VERSION "HNNBNNNYNNNNNNNNNNNNNNNNNNNNNNNNNNNNNNNNNN/4/%%%/4/'%**4NNN///"

NS_ :

BS_:

BU_: BAP_Tester ELV Gateway_Max HUD Kombi

BO_ 2536714496 BAP_Audio_ASG_01: 8 Kombi
 SG_ BAP_Audio_ASG_01_Header : 0|8@1+ (1.0,0.0) [0.0|255] ""  Gateway_Max

BO_ 2536714497 BAP_Audio_ASG_02: 8 Kombi
 SG_ BAP_Audio_ASG_02_Header : 0|8@1+ (1.0,0.0) [0.0|255] ""  Gateway_Max

BO_ 2536714498 BAP_Audio_ASG_03: 8 HUD
 SG_ BAP_Audio_ASG_03_Header : 0|8@1+ (1.0,0.0) [0.0|255] ""  Gateway_Max

BO_ 2536714499 BAP_Audio_ASG_04: 8 HUD
 SG_ BAP_Audio_ASG_04_Header : 0|8@1+ (1.0,0.0) [0.0|255] ""  Gateway_Max

BO_ 2536714512 BAP_Audio_FSG_01: 8 Gateway_Max
 SG_ BAP_Audio_FSG_01_Header : 0|8@1+ (1.0,0.0) [0.0|255] ""  HUD,Kombi

BO_ 2536714513 BAP_Audio_FSG_02: 8 Gateway_Max
 SG_ BAP_Audio_FSG_02_Header : 0|8@1+ (1.0,0.0) [0.0|255] ""  HUD,Kombi

BO_ 2536704256 BAP_Aussenlicht_ASG_01: 8 Kombi
 SG_ BAP_Aussenlicht_ASG_01_Header : 0|8@1+ (1.0,0.0) [0.0|255] ""  Gateway_Max

BO_ 2536704272 BAP_Aussenlicht_FSG_01: 8 Gateway_Max
 SG_ BAP_Aussenlicht_FSG_01_Header : 0|8@1+ (1.0,0.0) [0.0|255] ""  Kombi

BO_ 2536708865 BAP_AWV_ASG_02: 8 Kombi
 SG_ BAP_AWV_ASG_02_Header : 0|8@1+ (1.0,0.0) [0.0|255] ""  Gateway_Max

BO_ 2536708880 BAP_AWV_FSG_01: 8 Gateway_Max
 SG_ BAP_AWV_FSG_01_Header : 0|8@1+ (1.0,0.0) [0.0|255] ""  Kombi

BO_ 2536711426 BAP_BatteryControl_ASG_03: 8 Kombi
 SG_ BAP_BatteryControl_ASG_03_Header : 0|8@1+ (1.0,0.0) [0.0|255] ""  Gateway_Max

BO_ 2536711440 BAP_BatteryControl_FSG_01: 8 Gateway_Max
 SG_ BAP_BatteryControl_FSG_01_Header : 0|8@1+ (1.0,0.0) [0.0|255] ""  Kombi

BO_ 2536705792 BAP_BC_ASG_01: 8 Gateway_Max
 SG_ BAP_BC_ASG_01_Header : 0|8@1+ (1.0,0.0) [0.0|255] ""  Kombi

BO_ 2536705793 BAP_BC_ASG_02: 8 Gateway_Max
 SG_ BAP_BC_ASG_02_Header : 0|8@1+ (1.0,0.0) [0.0|255] ""  Kombi

BO_ 2536705808 BAP_BC_FSG_01: 8 Kombi
 SG_ BAP_BC_FSG_01_Header : 0|8@1+ (1.0,0.0) [0.0|255] ""  Gateway_Max

BO_ 2536705809 BAP_BC_FSG_02: 8 Kombi
 SG_ BAP_BC_FSG_02_Header : 0|64@1+ (1.0,0.0) [0.0|18446744073709551615] ""  Gateway_Max

BO_ 2536710912 BAP_BCmE_ASG_01: 8 Kombi
 SG_ BAP_BCmE_ASG_01_Header : 0|8@1+ (1.0,0.0) [0.0|255] ""  Gateway_Max

BO_ 2536710928 BAP_BCmE_FSG_01: 8 Gateway_Max
 SG_ BAP_BCmE_FSG_01_Header : 0|8@1+ (1.0,0.0) [0.0|255] ""  Kombi

BO_ 2536734976 BAP_California_ASG_01: 8 Gateway_Max
 SG_ BAP_California_ASG_01_Header : 0|64@1+ (1.0,0.0) [0.0|18446744073709551615] ""  Vector__XXX

BO_ 2536734992 BAP_California_FSG_01: 8 Vector__XXX
 SG_ BAP_California_FSG_01_Header : 0|64@1+ (1.0,0.0) [0.0|18446744073709551615] ""  Gateway_Max

BO_ 2536767264 BAP_Debug_Cmd: 8 BAP_Tester
 SG_ BAP_Debug_Cmd : 0|16@1+ (1.0,0.0) [0.0|65535] ""  Gateway_Max,HUD,Kombi

BO_ 2536767280 BAP_Debug_Data: 8 Gateway_Max
 SG_ BAP_Debug_Data : 0|64@1+ (1.0,0.0) [0.0|18446744073709551615] ""  BAP_Tester

BO_ 2536719616 BAP_DisplayConfig_ASG_01: 8 Gateway_Max
 SG_ BAP_DisplayConfig_ASG_01_Header : 0|8@1+ (1,0) [0|255] "Unit_None"  Kombi

BO_ 2536719617 BAP_DisplayConfig_ASG_02: 8 Gateway_Max
 SG_ BAP_DisplayConfig_ASG_02_Header : 0|64@1+ (1.0,0.0) [0.0|18446744073709551615] ""  Kombi

BO_ 2536719632 BAP_DisplayConfig_FSG_01: 8 Kombi
 SG_ BAP_DisplayConfig_FSG_01_Header : 0|8@1+ (1,0) [0|255] "Unit_None"  Gateway_Max

BO_ 2536705281 BAP_Doorlocking_ASG_02: 8 Kombi
 SG_ BAP_Doorlocking_ASG_02_Header : 0|8@1+ (1.0,0.0) [0.0|255] ""  Gateway_Max

BO_ 2536705296 BAP_Doorlocking_FSG_01: 8 Gateway_Max
 SG_ BAP_Doorlocking_FSG_01_Header : 0|8@1+ (1.0,0.0) [0.0|255] ""  Kombi

BO_ 2536717313 BAP_EfficiencyAssist_ASG_02: 8 Kombi
 SG_ BAP_EfficAssist_ASG_02_Header : 0|64@1+ (1.0,0.0) [0.0|18446744073709551615] ""  Gateway_Max

BO_ 2536717314 BAP_EfficiencyAssist_ASG_03: 8 HUD
 SG_ BAP_EfficAssist_ASG_03_Header : 0|64@1+ (1.0,0.0) [0.0|18446744073709551615] ""  Vector__XXX

BO_ 2536717328 BAP_EfficiencyAssist_FSG_01: 8 Gateway_Max
 SG_ BAP_EfficAssist_FSG_01_Header : 0|8@1+ (1.0,0.0) [0.0|255] ""  HUD,Kombi

BO_ 2536706816 BAP_Einheiten_ASG_01: 8 Gateway_Max
 SG_ BAP_Einheiten_ASG_01_Header : 0|8@1+ (1.0,0.0) [0.0|255] ""  Kombi

BO_ 2536706819 BAP_Einheiten_ASG_04: 8 Gateway_Max
 SG_ BAP_Einheiten_ASG_04_Header : 0|8@1+ (1,0) [0|255] "Unit_None"  Kombi

BO_ 2536706832 BAP_Einheiten_FSG_01: 8 Kombi
 SG_ BAP_Einheiten_FSG_01_Header : 0|8@1+ (1.0,0.0) [0.0|255] ""  Gateway_Max

BO_ 2536702976 BAP_HUD_ASG_01: 8 Gateway_Max
 SG_ BAP_HUD_ASG_01_Header : 0|8@1+ (1.0,0.0) [0.0|255] ""  HUD

BO_ 2536702977 BAP_HUD_ASG_02: 8 Kombi
 SG_ BAP_HUD_ASG_02_Header : 0|8@1+ (1,0) [0|255] "Unit_None"  HUD

BO_ 2536702978 BAP_HUD_ASG_03: 8 Gateway_Max
 SG_ BAP_HUD_ASG_03_Header : 0|8@1+ (1,0) [0|255] "Unit_None"  HUD

BO_ 2536702992 BAP_HUD_FSG_01: 8 HUD
 SG_ BAP_HUD_FSG_01_Header : 0|8@1+ (1.0,0.0) [0.0|255] ""  Gateway_Max,Kombi

BO_ 2536709121 BAP_Hybrid_ASG_02: 8 Kombi
 SG_ BAP_Hybrid_ASG_02_Header : 0|8@1+ (1.0,0.0) [0.0|255] ""  Gateway_Max

BO_ 2536709136 BAP_Hybrid_FSG_01: 8 Gateway_Max
 SG_ BAP_Hybrid_FSG_01_Header : 0|8@1+ (1.0,0.0) [0.0|255] ""  Kombi

BO_ 2536722945 BAP_IAA_PSO_ASG_02: 8 Kombi
 SG_ BAP_IAA_PSO_ASG_02_Header : 0|8@1+ (1,0) [0|255] "Unit_None"  Gateway_Max

BO_ 2536722960 BAP_IAA_PSO_FSG_01: 8 Gateway_Max
 SG_ BAP_IAA_PSO_FSG_01_Header : 0|8@1+ (1,0) [0|255] "Unit_None"  Kombi

BO_ 2536704000 BAP_Innenlicht_ASG_01: 8 Kombi
 SG_ BAP_Innenlicht_ASG_01_Header : 0|8@1+ (1.0,0.0) [0.0|255] ""  Gateway_Max

BO_ 2536704003 BAP_Innenlicht_ASG_04: 8 HUD
 SG_ BAP_Innenlicht_ASG_04_Header : 0|64@1+ (1.0,0.0) [0.0|18446744073709551615] ""  Gateway_Max

BO_ 2536704016 BAP_Innenlicht_FSG_01: 8 Gateway_Max
 SG_ BAP_Innenlicht_FSG_01_Header : 0|8@1+ (1.0,0.0) [0.0|255] ""  HUD,Kombi

BO_ 2536708353 BAP_LDW_ASG_02: 8 Kombi
 SG_ BAP_LDW_ASG_02_Header : 0|8@1+ (1.0,0.0) [0.0|255] ""  Gateway_Max

BO_ 2536708368 BAP_LDW_FSG_01: 8 Gateway_Max
 SG_ BAP_LDW_FSG_01_Header : 0|8@1+ (1.0,0.0) [0.0|255] ""  Kombi

BO_ 2536715264 BAP_MFL_ASG_01: 8 Kombi
 SG_ BAP_MFL_ASG_01_Header : 0|8@1+ (1.0,0.0) [0.0|255] ""  Gateway_Max

BO_ 2536715280 BAP_MFL_FSG_01: 8 Gateway_Max
 SG_ BAP_MFL_FSG_01_Header : 0|8@1+ (1.0,0.0) [0.0|255] ""  Kombi

BO_ 2536714752 BAP_Navigation_ASG_01: 8 Kombi
 SG_ BAP_Navigation_ASG_01_Header : 0|8@1+ (1.0,0.0) [0.0|255] ""  Gateway_Max

BO_ 2536714753 BAP_Navigation_ASG_02: 8 Kombi
 SG_ BAP_Navigation_ASG_02_Header : 0|8@1+ (1.0,0.0) [0.0|255] ""  Gateway_Max

BO_ 2536714754 BAP_Navigation_ASG_03: 8 HUD
 SG_ BAP_Navigation_ASG_03_Header : 0|8@1+ (1.0,0.0) [0.0|255] ""  Gateway_Max

BO_ 2536714755 BAP_Navigation_ASG_04: 8 HUD
 SG_ BAP_Navigation_ASG_04_Header : 0|8@1+ (1.0,0.0) [0.0|255] ""  Gateway_Max

BO_ 2536714768 BAP_Navigation_FSG_01: 8 Gateway_Max
 SG_ BAP_Navigation_FSG_01_Header : 0|8@1+ (1.0,0.0) [0.0|255] ""  HUD,Kombi

BO_ 2536714769 BAP_Navigation_FSG_02: 8 Gateway_Max
 SG_ BAP_Navigation_FSG_02_Header : 0|8@1+ (1.0,0.0) [0.0|255] ""  HUD,Kombi

BO_ 2536712704 BAP_OnlineFunction_ASG_01: 8 Kombi
 SG_ BAP_OnlineFunction_ASG_01_Header : 0|8@1+ (1,0) [0|255] "Unit_None"  Gateway_Max

BO_ 2536712705 BAP_OnlineFunction_ASG_02: 8 HUD
 SG_ BAP_OnlineFunction_ASG_02_Header : 0|8@1+ (1,0) [0|255] "Unit_None"  Gateway_Max

BO_ 2536712720 BAP_OnlineFunction_FSG_01: 8 Gateway_Max
 SG_ BAP_OnlineFunction_FSG_01_Header : 0|8@1+ (1,0) [0|255] "Unit_None"  HUD,Kombi

BO_ 2536704512 BAP_OPS_ASG_01: 8 Kombi
 SG_ BAP_OPS_ASG_01_Header : 0|8@1+ (1.0,0.0) [0.0|255] ""  Gateway_Max

BO_ 2536704518 BAP_OPS_ASG_07: 8 HUD
 SG_ BAP_OPS_ASG_07_Header : 0|64@1+ (1.0,0.0) [0.0|18446744073709551615] ""  Gateway_Max

BO_ 2536704528 BAP_OPS_FSG_01: 8 Gateway_Max
 SG_ BAP_OPS_FSG_01_Header : 0|8@1+ (1.0,0.0) [0.0|255] ""  HUD,Kombi

BO_ 2536704529 BAP_OPS_FSG_02: 8 Gateway_Max
 SG_ BAP_OPS_FSG_02_Header : 0|8@1+ (1.0,0.0) [0.0|255] ""  HUD,Kombi

BO_ 2536723713 BAP_PaCo_ASG_02: 8 Kombi
 SG_ BAP_PaCo_ASG_02_Header : 0|8@1+ (1,0) [0|255] "Unit_None"  Gateway_Max

BO_ 2536723716 BAP_PaCo_ASG_05: 8 HUD
 SG_ BAP_PaCo_ASG_05_Header : 0|64@1+ (1.0,0.0) [0.0|18446744073709551615] ""  Gateway_Max

BO_ 2536723728 BAP_PaCo_FSG_01: 8 Gateway_Max
 SG_ BAP_PaCo_FSG_01_Header : 0|8@1+ (1,0) [0|255] "Unit_None"  HUD,Kombi

BO_ 2536731136 BAP_RaceMeasurement_ASG_01: 8 Kombi
 SG_ BAP_RMeasurement_ASG_01_Header : 0|64@1+ (1.0,0.0) [0.0|18446744073709551615] ""  Gateway_Max

BO_ 2536731137 BAP_RaceMeasurement_ASG_02: 64 Kombi
 SG_ BAP_RMeasurement_ASG_02_Header : 0|512@1+ (1.0,0.0) [0.0|13407807929942597099574024998205846127479365820592393377723561443721764030073546976801874298166903427690031858186486050853753882811946569946433649006084095] ""  Gateway_Max

BO_ 2536731152 BAP_RaceMeasurement_FSG_01: 8 Gateway_Max
 SG_ BAP_RMeasurement_FSG_01_Header : 0|64@1+ (1.0,0.0) [0.0|18446744073709551615] ""  Kombi

BO_ 2536731153 BAP_RaceMeasurement_FSG_02: 64 Gateway_Max
 SG_ BAP_RMeasurement_FSG_02_Header : 0|512@1+ (1.0,0.0) [0.0|13407807929942597099574024998205846127479365820592393377723561443721764030073546976801874298166903427690031858186486050853753882811946569946433649006084095] ""  Kombi

BO_ 2536703745 BAP_RDK_ASG_02: 8 Kombi
 SG_ BAP_RDK_ASG_02_Header : 0|8@1+ (1.0,0.0) [0.0|255] ""  Gateway_Max

BO_ 2536703760 BAP_RDK_FSG_01: 8 Gateway_Max
 SG_ BAP_RDK_FSG_01_Header : 0|8@1+ (1.0,0.0) [0.0|255] ""  Kombi

BO_ 2536719872 BAP_SDS_ASG_01: 8 Vector__XXX
 SG_ BAP_SDS_ASG_01_Header : 0|8@1+ (1,0) [0|255] "Unit_None"  Gateway_Max

BO_ 2536719888 BAP_SDS_FSG_01: 8 Gateway_Max
 SG_ BAP_SDS_FSG_01_Header : 0|8@1+ (1,0) [0|255] "Unit_None"  Vector__XXX

BO_ 2536706560 BAP_SIA_ASG_01: 8 Gateway_Max
 SG_ BAP_SIA_ASG_01_Header : 0|8@1+ (1.0,0.0) [0.0|255] ""  Kombi

BO_ 2536706561 BAP_SIA_ASG_02: 8 Gateway_Max
 SG_ BAP_SIA_ASG_02_Header : 0|8@1+ (1.0,0.0) [0.0|255] ""  Kombi

BO_ 2536706576 BAP_SIA_FSG_01: 8 Kombi
 SG_ BAP_SIA_FSG_01_Header : 0|8@1+ (1.0,0.0) [0.0|255] ""  Gateway_Max

BO_ 2536736001 BAP_SLCView_ASG_02: 8 Kombi
 SG_ BAP_SLCView_ASG_02_Header : 0|64@1+ (1.0,0.0) [0.0|18446744073709551615] ""  Gateway_Max

BO_ 2536736016 BAP_SLCView_FSG_01: 8 Gateway_Max
 SG_ BAP_SLCView_FSG_01_Header : 0|64@1+ (1.0,0.0) [0.0|18446744073709551615] ""  Kombi

BO_ 2536711937 BAP_StartStopReasons_ASG_02: 8 Kombi
 SG_ BAP_StartStopReasons_ASG_02_Head : 0|8@1+ (1,0) [0|255] "Unit_None"  Gateway_Max

BO_ 2536711952 BAP_StartStopReasons_FSG_01: 8 Gateway_Max
 SG_ BAP_StartStopReasons_FSG_01_Head : 0|8@1+ (1.0,0.0) [0.0|255] ""  Kombi

BO_ 2536720896 BAP_Statistics_ASG_01: 8 Gateway_Max
 SG_ BAP_Statistics_ASG_01_Header : 0|8@1+ (1,0) [0|255] "Unit_None"  Kombi

BO_ 2536720912 BAP_Statistics_FSG_01: 8 Kombi
 SG_ BAP_Statistics_FSG_01_Header : 0|8@1+ (1,0) [0|255] "Unit_None"  Gateway_Max

BO_ 2536708609 BAP_SWA_ASG_02: 8 Kombi
 SG_ BAP_SWA_ASG_02_Header : 0|8@1+ (1.0,0.0) [0.0|255] ""  Gateway_Max

BO_ 2536708624 BAP_SWA_FSG_01: 8 Gateway_Max
 SG_ BAP_SWA_FSG_01_Header : 0|8@1+ (1.0,0.0) [0.0|255] ""  Kombi

BO_ 2536712448 BAP_Telefon2_ASG_01: 8 Kombi
 SG_ BAP_Telefon2_ASG_01_Header : 0|8@1+ (1.0,0.0) [0.0|255] ""  Gateway_Max

BO_ 2536712449 BAP_Telefon2_ASG_02: 8 HUD
 SG_ BAP_Telefon2_ASG_02_Header : 0|8@1+ (1,0) [0|255] "Unit_None"  Gateway_Max

BO_ 2536712464 BAP_Telefon2_FSG_01: 8 Gateway_Max
 SG_ BAP_Telefon2_FSG_01_Header : 0|8@1+ (1.0,0.0) [0.0|255] ""  HUD,Kombi

BO_ 2536712465 BAP_Telefon2_FSG_02: 8 Gateway_Max
 SG_ BAP_Telefon2_FSG_02_Header : 0|8@1+ (1,0) [0|255] "Unit_None"  HUD,Kombi

BO_ 2536712192 BAP_Telefon_ASG_01: 8 Kombi
 SG_ BAP_Telefon_ASG_01_Header : 0|8@1+ (1.0,0.0) [0.0|255] ""  Gateway_Max

BO_ 2536712193 BAP_Telefon_ASG_02: 8 Kombi
 SG_ BAP_Telefon_ASG_02_Header : 0|8@1+ (1.0,0.0) [0.0|255] ""  Gateway_Max

BO_ 2536712194 BAP_Telefon_ASG_03: 8 HUD
 SG_ BAP_Telefon_ASG_03_Header : 0|8@1+ (1,0) [0|255] "Unit_None"  Gateway_Max

BO_ 2536712195 BAP_Telefon_ASG_04: 8 HUD
 SG_ BAP_Telefon_ASG_04_Header : 0|8@1+ (1,0) [0|255] "Unit_None"  Gateway_Max

BO_ 2536712208 BAP_Telefon_FSG_01: 8 Gateway_Max
 SG_ BAP_Telefon_FSG_01_Header : 0|8@1+ (1.0,0.0) [0.0|255] ""  HUD,Kombi

BO_ 2536712209 BAP_Telefon_FSG_02: 8 Gateway_Max
 SG_ BAP_Telefon_FSG_02_Header : 0|8@1+ (1.0,0.0) [0.0|255] ""  HUD,Kombi

BO_ 2536706304 BAP_Uhrzeit_ASG_01: 8 Gateway_Max
 SG_ BAP_Uhrzeit_ASG_01_Header : 0|8@1+ (1.0,0.0) [0.0|255] ""  Kombi

BO_ 2536706305 BAP_Uhrzeit_ASG_02: 8 Gateway_Max
 SG_ BAP_Uhrzeit_ASG_02_Header : 0|8@1+ (1.0,0.0) [0.0|255] ""  Kombi

BO_ 2536706308 BAP_Uhrzeit_ASG_05: 8 Gateway_Max
 SG_ BAP_Uhrzeit_ASG_05_Header : 0|8@1+ (1.0,0.0) [0.0|255] ""  Kombi

BO_ 2536706320 BAP_Uhrzeit_FSG_01: 8 Kombi
 SG_ BAP_Uhrzeit_FSG_01_Header : 0|8@1+ (1.0,0.0) [0.0|255] ""  Gateway_Max

BO_ 2536710401 BAP_VZA_ASG_02: 8 Kombi
 SG_ BAP_VZA_ASG_02_Header : 0|8@1+ (1.0,0.0) [0.0|255] ""  Gateway_Max

BO_ 2536710402 BAP_VZA_ASG_03: 8 HUD
 SG_ BAP_VZA_ASG_03_Header : 0|8@1+ (1,0) [0|255] "Unit_None"  Gateway_Max

BO_ 2536710416 BAP_VZA_FSG_01: 8 Gateway_Max
 SG_ BAP_VZA_FSG_01_Header : 0|8@1+ (1.0,0.0) [0.0|255] ""  HUD,Kombi

BO_ 2583694872 BCM1_AuthTime_Req: 8 Gateway_Max
 SG_ BCM1_AuthTime_Req_Data : 0|64@1+ (1.0,0.0) [0.0|18446744073709551615] ""  Kombi

BO_ 2583825944 BCM1_AuthTime_Resp: 8 Kombi
 SG_ BCM1_AuthTime_Resp_Data : 0|64@1+ (1.0,0.0) [0.0|18446744073709551615] ""  Gateway_Max

BO_ 1626 BCM_01: 8 Gateway_Max
 SG_ BCM_Bremsbelag_Sensor : 12|1@1+ (1.0,0.0) [0.0|1] ""  Kombi
 SG_ BCM_Bremsfluessigkeit_Sensor : 13|1@1+ (1.0,0.0) [0.0|1] ""  Kombi
 SG_ BCM1_Licht_Warn : 14|1@1+ (1.0,0.0) [0.0|1] ""  Vector__XXX
 SG_ BCM_Waschwasser_Sensor : 15|1@1+ (1.0,0.0) [0.0|1] ""  Kombi
 SG_ BCM_Kuehlmittel_Sensor : 16|1@1+ (1.0,0.0) [0.0|1] ""  Kombi
 SG_ BCM1_Kl_15_HW_erkannt : 17|1@1+ (1.0,0.0) [0.0|1] ""  Vector__XXX
 SG_ BCM1_Kl_15_Sig_HW_erkannt : 18|1@1+ (1.0,0.0) [0.0|1] ""  Vector__XXX
 SG_ BCM_Kuehlmittel_Sensor_02 : 19|1@1+ (1.0,0.0) [0.0|1] ""  Vector__XXX
 SG_ BCM1_Hinweis_Lichtnachlauf : 20|1@1+ (1.0,0.0) [0.0|1] ""  Kombi
 SG_ BCM_Offroad_Taste : 21|1@1+ (1.0,0.0) [0.0|1] ""  Vector__XXX
 SG_ BCM_Charisma_Taste2 : 22|1@1+ (1.0,0.0) [0.0|1] ""  Vector__XXX
 SG_ BCM_Hybrid_StSt_Taste_Fehler : 23|1@1+ (1.0,0.0) [0.0|1] ""  Vector__XXX
 SG_ BCM_Hybrid_StartStopp_Taste : 24|1@1+ (1.0,0.0) [0.0|1] ""  Vector__XXX
 SG_ BCM1_Warnblink_Taster : 25|1@1+ (1.0,0.0) [0.0|1] ""  Kombi
 SG_ BCM1_Valet_Parking_Taster : 26|1@1+ (1.0,0.0) [0.0|1] ""  Vector__XXX
 SG_ BCM1_LDS_Stellung : 27|3@1+ (1.0,0.0) [0.0|7] ""  Vector__XXX
 SG_ BCM1_Rueckfahrlicht_Schalter : 30|1@1+ (1.0,0.0) [0.0|1] ""  Vector__XXX
 SG_ BCM1_MH_Schalter : 31|1@1+ (1.0,0.0) [0.0|1] ""  Kombi
 SG_ BCM1_MH_WIV_Schalter : 32|1@1+ (1.0,0.0) [0.0|1] ""  Vector__XXX
 SG_ BCM_Eco_Charisma_Taste : 33|1@1+ (1.0,0.0) [0.0|1] ""  Vector__XXX
 SG_ BCM1_NV_Taster : 34|1@1+ (1.0,0.0) [0.0|1] ""  Vector__XXX
 SG_ BCM1_AFS_Lampe : 35|1@1+ (1.0,0.0) [0.0|1] ""  Vector__XXX
 SG_ BCM1_Reisemodus_Texte : 36|2@1+ (1.0,0.0) [0.0|3] ""  Vector__XXX
 SG_ BCM1_Lichtwarn_Texte : 38|2@1+ (1.0,0.0) [0.0|3] ""  Kombi
 SG_ Gong_TFL_Umschaltung : 40|1@1+ (1.0,0.0) [0.0|1] ""  Kombi
 SG_ BCM_ValetTaster_Fkts_LED : 42|1@1+ (1.0,0.0) [0.0|1] ""  Kombi
 SG_ LRH_Taster : 43|1@1+ (1.0,0.0) [0.0|1] ""  Vector__XXX
 SG_ APS_Tongeber_defekt : 44|1@1+ (1.0,0.0) [0.0|1] ""  Vector__XXX
 SG_ BCM1_EasyEntry_Status : 45|1@1+ (1.0,0.0) [0.0|1] ""  Vector__XXX
 SG_ BCM1_Lenksaeule_aktiv : 46|1@1+ (1.0,0.0) [0.0|1] ""  Vector__XXX
 SG_ BCM1_Spannungs_Anf : 47|2@1+ (1.0,0.0) [0.0|3] ""  Vector__XXX
 SG_ DWA_Alarmquelle : 49|5@1+ (1.0,0.0) [0.0|31] ""  Vector__XXX
 SG_ DWA_Einschraenkung : 54|1@1+ (1.0,0.0) [0.0|1] ""  Vector__XXX
 SG_ BCM_HBFS_EOE_aktiv : 56|1@1+ (1.0,0.0) [0.0|1] ""  Vector__XXX
 SG_ BCM_HFS_EOE_aktiv : 57|1@1+ (1.0,0.0) [0.0|1] ""  Vector__XXX
 SG_ BCM_Anf_AAW_MoLaWa : 58|2@1+ (1.0,0.0) [0.0|3] ""  Kombi
 SG_ BCM_Handbremse_Hinweis : 60|1@1+ (1.0,0.0) [0.0|1] ""  Kombi
 SG_ BCM_Waehlhebel_P_Hinweis : 61|1@1+ (1.0,0.0) [0.0|1] ""  Kombi
 SG_ BCM1_Fahrlicht_Hinweis : 62|1@1+ (1.0,0.0) [0.0|1] ""  Kombi
 SG_ BCM_HDF_betaetigt : 63|1@1+ (1.0,0.0) [0.0|1] ""  Vector__XXX

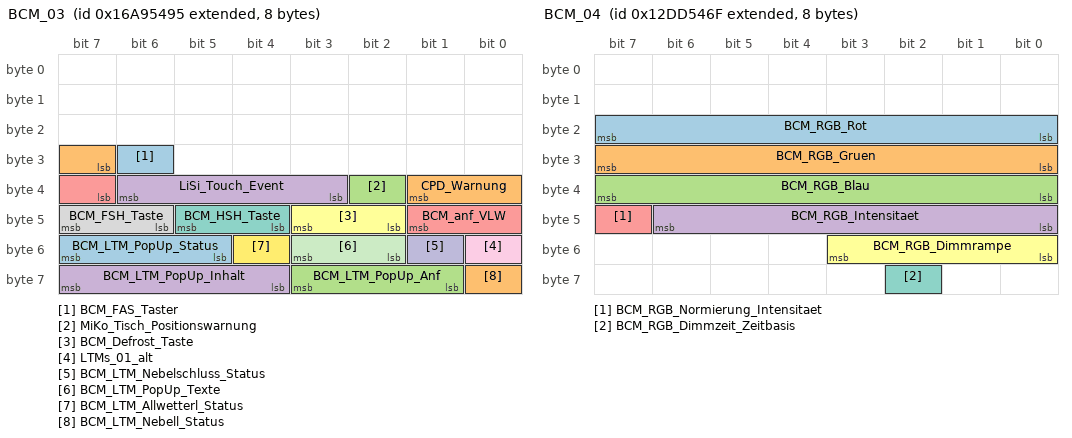
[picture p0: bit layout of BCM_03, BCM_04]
BO_ 2527679637 BCM_03: 8 Gateway_Max
 SG_ BCM_FAS_Taster : 30|1@1+ (1.0,0.0) [0.0|1] ""  Vector__XXX
 SG_ CPD_Warnung : 31|3@1+ (1.0,0.0) [0.0|7] ""  Kombi
 SG_ MiKo_Tisch_Positionswarnung : 34|1@1+ (1.0,0.0) [0.0|1] ""  Kombi
 SG_ LiSi_Touch_Event : 35|4@1+ (1.0,0.0) [0.0|15] ""  Vector__XXX
 SG_ BCM_anf_VLW : 39|3@1+ (1.0,0.0) [0.0|7] ""  Kombi
 SG_ BCM_Defrost_Taste : 42|2@1+ (1.0,0.0) [0.0|3] ""  Vector__XXX
 SG_ BCM_HSH_Taste : 44|2@1+ (1.0,0.0) [0.0|3] ""  Vector__XXX
 SG_ BCM_FSH_Taste : 46|2@1+ (1.0,0.0) [0.0|3] ""  Vector__XXX
 SG_ LTMs_01_alt : 48|1@1+ (1.0,0.0) [0.0|1] ""  Vector__XXX
 SG_ BCM_LTM_Nebelschluss_Status : 49|1@1+ (1.0,0.0) [0.0|1] ""  Kombi
 SG_ BCM_LTM_PopUp_Texte : 50|2@1+ (1.0,0.0) [0.0|3] ""  Vector__XXX
 SG_ BCM_LTM_Allwetterl_Status : 52|1@1+ (1.0,0.0) [0.0|1] ""  Kombi
 SG_ BCM_LTM_PopUp_Status : 53|3@1+ (1.0,0.0) [0.0|7] ""  Kombi
 SG_ BCM_LTM_Nebell_Status : 56|1@1+ (1.0,0.0) [0.0|1] ""  Kombi
 SG_ BCM_LTM_PopUp_Anf : 57|3@1+ (1.0,0.0) [0.0|7] ""  Kombi
 SG_ BCM_LTM_PopUp_Inhalt : 60|4@1+ (1.0,0.0) [0.0|15] ""  Kombi

BO_ 2463978607 BCM_04: 8 Gateway_Max
 SG_ BCM_RGB_Rot : 16|8@1+ (1,0) [0|255] ""  HUD,Kombi
 SG_ BCM_RGB_Gruen : 24|8@1+ (1,0) [0|255] ""  HUD,Kombi
 SG_ BCM_RGB_Blau : 32|8@1+ (1,0) [0|255] ""  HUD,Kombi
 SG_ BCM_RGB_Intensitaet : 40|7@1+ (1,0) [0|100] "Unit_PerCent"  Vector__XXX
 SG_ BCM_RGB_Normierung_Intensitaet : 47|1@1+ (1.0,0.0) [0.0|1] ""  Vector__XXX
 SG_ BCM_RGB_Dimmrampe : 48|4@1+ (0.25,0) [0.00|3.75] "Unit_Secon"  Vector__XXX
 SG_ BCM_RGB_Dimmzeit_Zeitbasis : 58|1@1+ (1.0,0.0) [0.0|1] ""  Vector__XXX

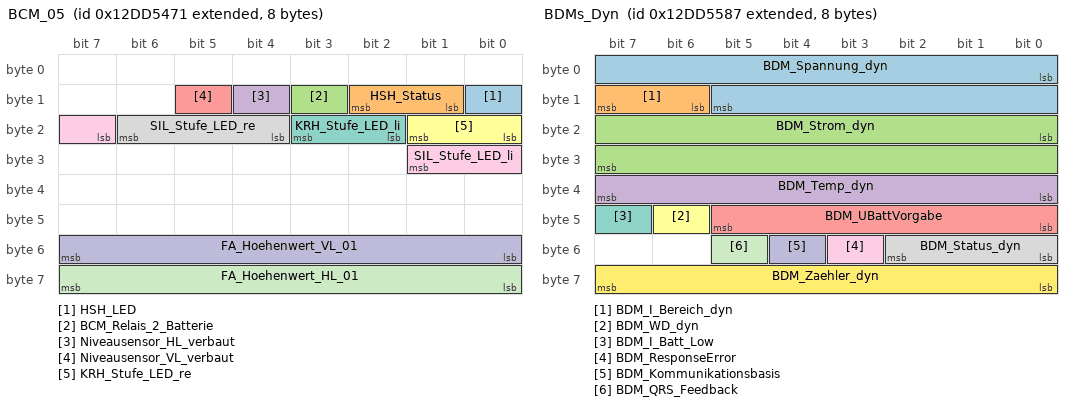
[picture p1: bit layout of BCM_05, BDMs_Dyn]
BO_ 2463978609 BCM_05: 8 Gateway_Max
 SG_ HSH_LED : 8|1@1+ (1.0,0.0) [0.0|1] ""  Vector__XXX
 SG_ HSH_Status : 9|2@1+ (1.0,0.0) [0.0|3] ""  Vector__XXX
 SG_ BCM_Relais_2_Batterie : 11|1@1+ (1.0,0.0) [0.0|1] ""  Vector__XXX
 SG_ Niveausensor_HL_verbaut : 12|1@1+ (1.0,0.0) [0.0|1] ""  Vector__XXX
 SG_ Niveausensor_VL_verbaut : 13|1@1+ (1.0,0.0) [0.0|1] ""  Vector__XXX
 SG_ KRH_Stufe_LED_re : 16|2@1+ (1.0,0.0) [0.0|3] ""  Vector__XXX
 SG_ KRH_Stufe_LED_li : 18|2@1+ (1.0,0.0) [0.0|3] ""  Vector__XXX
 SG_ SIL_Stufe_LED_re : 20|3@1+ (1.0,0.0) [0.0|7] ""  Vector__XXX
 SG_ SIL_Stufe_LED_li : 23|3@1+ (1.0,0.0) [0.0|7] ""  Vector__XXX
 SG_ FA_Hoehenwert_VL_01 : 48|8@1+ (0.4,0) [0.0|100.0] "Unit_PerCent"  Vector__XXX
 SG_ FA_Hoehenwert_HL_01 : 56|8@1+ (0.4,0) [0.0|100.0] "Unit_PerCent"  Vector__XXX

BO_ 2463978887 BDMs_Dyn: 8 Gateway_Max
 SG_ BDM_Spannung_dyn : 0|14@1+ (0.001,4) [4.000|20.000] "Unit_Volt"  Vector__XXX
 SG_ BDM_I_Bereich_dyn : 14|2@1+ (1.0,0.0) [0.0|3] ""  Vector__XXX
 SG_ BDM_Strom_dyn : 16|16@1+ (1,-32768) [-30000|30000] ""  Vector__XXX
 SG_ BDM_Temp_dyn : 32|8@1+ (1,-40) [-40|105] "Unit_DegreCelsi"  Vector__XXX
 SG_ BDM_UBattVorgabe : 40|6@1+ (0.1,12) [12.0|18.0] "Unit_Volt"  Vector__XXX
 SG_ BDM_WD_dyn : 46|1@1+ (1.0,0.0) [0.0|1] ""  Vector__XXX
 SG_ BDM_I_Batt_Low : 47|1@1+ (1.0,0.0) [0.0|1] ""  Vector__XXX
 SG_ BDM_Status_dyn : 48|3@1+ (1.0,0.0) [0.0|7] ""  Vector__XXX
 SG_ BDM_ResponseError : 51|1@1+ (1.0,0.0) [0.0|1] ""  Vector__XXX
 SG_ BDM_Kommunikationsbasis : 52|1@1+ (1.0,0.0) [0.0|1] ""  Vector__XXX
 SG_ BDM_QRS_Feedback : 53|1@1+ (1.0,0.0) [0.0|1] ""  Vector__XXX
 SG_ BDM_Zaehler_dyn : 56|8@1+ (1,0) [0|255] ""  Vector__XXX

BO_ 2463978882 BedienDisp_hbfs_01: 8 Gateway_Max
 SG_ BedienDisp_hbfs_01_CRC : 0|8@1+ (1,0) [0|255] ""  Kombi
 SG_ BedienDisp_hbfs_01_BZ : 8|4@1+ (1,0) [0|15] ""  Kombi
 SG_ BedienDisp_hbfs_control_vol : 12|4@1+ (1.0,0.0) [0.0|15] ""  Vector__XXX
 SG_ BedienDisp_hbfs_fader : 16|4@1+ (1.0,0.0) [0.0|15] ""  Vector__XXX
 SG_ BedienDisp_hbfs_surround : 20|4@1+ (1.0,0.0) [0.0|15] ""  Vector__XXX
 SG_ BedienDisp_hbfs_sound : 24|4@1+ (1.0,0.0) [0.0|15] ""  Vector__XXX
 SG_ BedienDisp_hbfs_Lordose_hoch : 28|1@1+ (1.0,0.0) [0.0|1] ""  Vector__XXX
 SG_ BedienDisp_hbfs_Lordose_runter : 29|1@1+ (1.0,0.0) [0.0|1] ""  Vector__XXX
 SG_ BedienDisp_hbfs_Lordose_vor : 30|1@1+ (1.0,0.0) [0.0|1] ""  Vector__XXX
 SG_ BedienDisp_hbfs_Lordose_zurueck : 31|1@1+ (1.0,0.0) [0.0|1] ""  Vector__XXX
 SG_ BedienDisp_hbfs_touch : 32|4@1+ (1.0,0.0) [0.0|15] ""  Vector__XXX
 SG_ BedienDisp_hbfs_sound_fokus : 36|4@1+ (1.0,0.0) [0.0|15] ""  Vector__XXX
 SG_ BedienDisp_hbfs_surround_02 : 40|7@1+ (1,0) [0|100] "Unit_None"  Vector__XXX
 SG_ BedienDisp_hbfs_control_vol_02 : 47|7@1+ (1,0) [0|100] "Unit_None"  Vector__XXX
 SG_ BedienDisp_HBFSFo_Bestaetigung : 54|2@1+ (1.0,0.0) [0.0|3] ""  Vector__XXX
 SG_ BedienDisp_HBFSFo_Stoerung : 56|2@1+ (1.0,0.0) [0.0|3] ""  Kombi
 SG_ BedienDisp_hbfs_UseCase_Pos : 58|3@1+ (1.0,0.0) [0.0|7] ""  Vector__XXX

BO_ 2463978881 BedienDisp_hfs_01: 8 Gateway_Max
 SG_ BedienDisp_hfs_01_CRC : 0|8@1+ (1,0) [0|255] ""  Kombi
 SG_ BedienDisp_hfs_01_BZ : 8|4@1+ (1,0) [0|15] ""  Kombi
 SG_ BedienDisp_hfs_control_vol : 12|4@1+ (1.0,0.0) [0.0|15] ""  Vector__XXX
 SG_ BedienDisp_hfs_fader : 16|4@1+ (1.0,0.0) [0.0|15] ""  Vector__XXX
 SG_ BedienDisp_hfs_surround : 20|4@1+ (1.0,0.0) [0.0|15] ""  Vector__XXX
 SG_ BedienDisp_hfs_sound : 24|4@1+ (1.0,0.0) [0.0|15] ""  Vector__XXX
 SG_ BedienDisp_hfs_Lordose_hoch : 28|1@1+ (1.0,0.0) [0.0|1] ""  Vector__XXX
 SG_ BedienDisp_hfs_Lordose_runter : 29|1@1+ (1.0,0.0) [0.0|1] ""  Vector__XXX
 SG_ BedienDisp_hfs_Lordose_vor : 30|1@1+ (1.0,0.0) [0.0|1] ""  Vector__XXX
 SG_ BedienDisp_hfs_Lordose_zurueck : 31|1@1+ (1.0,0.0) [0.0|1] ""  Vector__XXX
 SG_ BedienDisp_hfs_touch : 32|4@1+ (1.0,0.0) [0.0|15] ""  Vector__XXX
 SG_ BedienDisp_hfs_sound_fokus : 36|4@1+ (1.0,0.0) [0.0|15] ""  Vector__XXX
 SG_ BedienDisp_hfs_surround_02 : 40|7@1+ (1,0) [0|100] "Unit_None"  Vector__XXX
 SG_ BedienDisp_hfs_control_vol_02 : 47|7@1+ (1,0) [0|100] "Unit_None"  Vector__XXX
 SG_ BedienDisp_HFSFo_Bestaetigung : 54|2@1+ (1.0,0.0) [0.0|3] ""  Vector__XXX
 SG_ BedienDisp_HFSFo_Stoerung : 56|2@1+ (1.0,0.0) [0.0|3] ""  Kombi
 SG_ BedienDisp_hfs_UseCase_Pos : 58|3@1+ (1.0,0.0) [0.0|7] ""  Vector__XXX

BO_ 1635 BEM_02: 8 Gateway_Max
 SG_ NVEM_Abschaltstufe : 0|2@1+ (1.0,0.0) [0.0|3] ""  HUD
 SG_ BEM_STH_Zielzeit : 3|4@1+ (5,0) [0|60] "Unit_Minut"  Vector__XXX
 SG_ BEM_MMI_Vorwarnung : 7|1@1+ (1.0,0.0) [0.0|1] ""  Vector__XXX
 SG_ BEM_HL_Kontingentierung : 8|6@1+ (50,-1000) [-1000|1000] "Unit_Watt"  Vector__XXX
 SG_ NVEM_Freigabe_ZusBatt_Laden : 14|1@1+ (1.0,0.0) [0.0|1] ""  Vector__XXX
 SG_ NVEM_Anf_SD_schalten : 15|1@1+ (1.0,0.0) [0.0|1] ""  Vector__XXX
 SG_ BEM_Generatordiagnose : 16|2@1+ (1.0,0.0) [0.0|3] ""  Vector__XXX
 SG_ BEM_Red_Innengeblaese : 18|2@1+ (1.0,0.0) [0.0|3] ""  Vector__XXX
 SG_ BEM_STH_Einschaltverbot : 20|1@1+ (1.0,0.0) [0.0|1] ""  Vector__XXX
 SG_ BEM_HL_Regelung_Status : 21|3@1+ (1.0,0.0) [0.0|7] ""  Vector__XXX
 SG_ BEM_Ladezustand : 24|4@1+ (10,0) [0|100] "Unit_PerCent"  Vector__XXX
 SG_ BEM_Batteriediagnose : 28|3@1+ (1.0,0.0) [0.0|7] ""  Vector__XXX
 SG_ MIB_Stromsparmodus : 31|1@1+ (1.0,0.0) [0.0|1] ""  Vector__XXX
 SG_ BEM_DFM : 32|5@1+ (3.225,0.025) [0.025|100.000] ""  Vector__XXX
 SG_ BEM_REK_aktiv : 37|1@1+ (1.0,0.0) [0.0|1] ""  Vector__XXX
 SG_ BEM_EMLIN_ungueltig : 38|1@1+ (1.0,0.0) [0.0|1] ""  Vector__XXX
 SG_ BEM_Batt_Ab : 39|1@1+ (1.0,0.0) [0.0|1] ""  Vector__XXX
 SG_ BEM_UBDM : 40|8@1+ (0.05,5) [5.05|17.70] "Unit_Volt"  Vector__XXX
 SG_ BEM_UGenSoll : 48|6@1+ (0.1,10.6) [10.6|16.0] "Unit_Volt"  Vector__XXX
 SG_ BEM_Anf_KL15_schalten : 54|2@1+ (1.0,0.0) [0.0|3] ""  Vector__XXX
 SG_ NVEM_Batterie_Service : 56|2@1+ (1.0,0.0) [0.0|3] ""  Vector__XXX
 SG_ NVEM_Freigabe_OnlineUpdate : 58|1@1+ (1.0,0.0) [0.0|1] ""  Vector__XXX
 SG_ NVEM_Freigabe_ORU4 : 59|2@1+ (1.0,0.0) [0.0|3] ""  Vector__XXX
 SG_ NVEM_Verbraucherabsch_Anz : 61|1@1+ (1.0,0.0) [0.0|1] ""  Vector__XXX

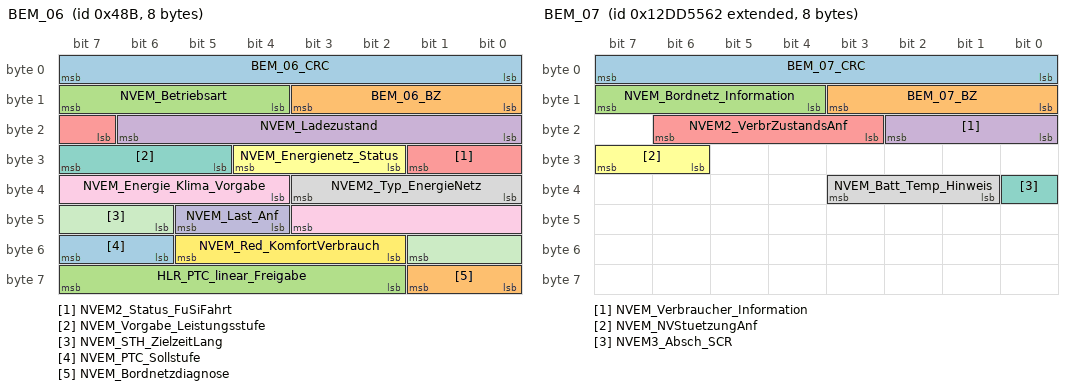
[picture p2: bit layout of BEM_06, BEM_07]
BO_ 1163 BEM_06: 8 Gateway_Max
 SG_ BEM_06_CRC : 0|8@1+ (1,0) [0|255] ""  Kombi
 SG_ BEM_06_BZ : 8|4@1+ (1,0) [0|15] ""  Kombi
 SG_ NVEM_Betriebsart : 12|4@1+ (1.0,0.0) [0.0|15] ""  Vector__XXX
 SG_ NVEM_Ladezustand : 16|7@1+ (1,0) [0|100] "Unit_PerCent"  Kombi
 SG_ NVEM2_Status_FuSiFahrt : 23|3@1+ (1.0,0.0) [0.0|7] ""  Vector__XXX
 SG_ NVEM_Energienetz_Status : 26|3@1+ (1.0,0.0) [0.0|7] ""  Vector__XXX
 SG_ NVEM_Vorgabe_Leistungsstufe : 29|3@1+ (1.0,0.0) [0.0|7] ""  Vector__XXX
 SG_ NVEM2_Typ_EnergieNetz : 32|4@1+ (1.0,0.0) [0.0|15] ""  Vector__XXX
 SG_ NVEM_Energie_Klima_Vorgabe : 36|8@1+ (10,0) [0|2530] "Unit_WattHour"  Vector__XXX
 SG_ NVEM_Last_Anf : 44|2@1+ (1.0,0.0) [0.0|3] ""  Vector__XXX
 SG_ NVEM_STH_ZielzeitLang : 46|4@1+ (10,0) [0|120] "Unit_Minut"  Vector__XXX
 SG_ NVEM_Red_KomfortVerbrauch : 50|4@1+ (1.0,0.0) [0.0|15] ""  Vector__XXX
 SG_ NVEM_PTC_Sollstufe : 54|2@1+ (1.0,0.0) [0.0|3] ""  Vector__XXX
 SG_ NVEM_Bordnetzdiagnose : 56|2@1+ (1.0,0.0) [0.0|3] ""  Kombi
 SG_ HLR_PTC_linear_Freigabe : 58|6@1+ (50,0) [0|3100] "Unit_Watt"  Vector__XXX

BO_ 2463978850 BEM_07: 8 Gateway_Max
 SG_ BEM_07_CRC : 0|8@1+ (1,0) [0|255] ""  Vector__XXX
 SG_ BEM_07_BZ : 8|4@1+ (1,0) [0|15] ""  Vector__XXX
 SG_ NVEM_Bordnetz_Information : 12|4@1+ (1.0,0.0) [0.0|15] ""  Kombi
 SG_ NVEM_Verbraucher_Information : 16|3@1+ (1.0,0.0) [0.0|7] ""  Kombi
 SG_ NVEM2_VerbrZustandsAnf : 19|4@1+ (1.0,0.0) [0.0|15] ""  Vector__XXX
 SG_ NVEM_NVStuetzungAnf : 30|2@1+ (1.0,0.0) [0.0|3] ""  Vector__XXX
 SG_ NVEM3_Absch_SCR : 32|1@1+ (1.0,0.0) [0.0|1] ""  Vector__XXX
 SG_ NVEM_Batt_Temp_Hinweis : 33|3@1+ (1.0,0.0) [0.0|7] ""  Kombi

BO_ 870 Blinkmodi_02: 8 Gateway_Max
 SG_ Blinkmodi_02_CRC : 0|8@1+ (1,0) [0|255] ""  Vector__XXX
 SG_ Blinkmodi_02_BZ : 8|4@1+ (1,0) [0|15] ""  Vector__XXX
 SG_ BM_ZV_auf : 12|1@1+ (1.0,0.0) [0.0|1] ""  Vector__XXX
 SG_ BM_ZV_zu : 13|1@1+ (1.0,0.0) [0.0|1] ""  Vector__XXX
 SG_ BM_DWA_ein : 14|1@1+ (1.0,0.0) [0.0|1] ""  Vector__XXX
 SG_ BM_DWA_Alarm : 15|1@1+ (1.0,0.0) [0.0|1] ""  Vector__XXX
 SG_ BM_Crash : 16|1@1+ (1.0,0.0) [0.0|1] ""  Vector__XXX
 SG_ BM_Panik : 17|1@1+ (1.0,0.0) [0.0|1] ""  Vector__XXX
 SG_ BM_Not_Bremsung : 18|1@1+ (1.0,0.0) [0.0|1] ""  Vector__XXX
 SG_ BM_GDO : 19|1@1+ (1.0,0.0) [0.0|1] ""  Vector__XXX
 SG_ BM_Warnblinken : 20|1@1+ (1.0,0.0) [0.0|1] ""  Kombi
 SG_ BM_Taxi_Notalarm : 21|1@1+ (1.0,0.0) [0.0|1] ""  Vector__XXX
 SG_ BM_Telematik : 22|1@1+ (1.0,0.0) [0.0|1] ""  Vector__XXX
 SG_ BM_links : 23|1@1+ (1.0,0.0) [0.0|1] ""  Vector__XXX
 SG_ BM_rechts : 24|1@1+ (1.0,0.0) [0.0|1] ""  Vector__XXX
 SG_ Blinken_li_Fzg_Takt : 25|1@1+ (1.0,0.0) [0.0|1] ""  Vector__XXX
 SG_ Blinken_re_Fzg_Takt : 26|1@1+ (1.0,0.0) [0.0|1] ""  Vector__XXX
 SG_ Blinken_li_Kombi_Takt : 27|1@1+ (1.0,0.0) [0.0|1] ""  HUD,Kombi
 SG_ Blinken_re_Kombi_Takt : 28|1@1+ (1.0,0.0) [0.0|1] ""  HUD,Kombi
 SG_ BM_NBA_n_codiert_n_aktiv : 29|1@1+ (1.0,0.0) [0.0|1] ""  Vector__XXX
 SG_ BM_NBA_Status : 30|2@1+ (1.0,0.0) [0.0|3] ""  Vector__XXX
 SG_ BM_WBT_Beleuchtung : 32|1@1+ (1.0,0.0) [0.0|1] ""  Vector__XXX
 SG_ BM_HD_Oeffnung_angelernt : 33|1@1+ (1.0,0.0) [0.0|1] ""  Vector__XXX
 SG_ BM_Autobahn : 34|1@1+ (1.0,0.0) [0.0|1] ""  Vector__XXX
 SG_ BM_Rollenmodus_Blinken : 35|1@1+ (1.0,0.0) [0.0|1] ""  Vector__XXX
 SG_ BM_Recas : 36|1@1+ (1.0,0.0) [0.0|1] ""  Vector__XXX
 SG_ BM_Wischblinken : 37|1@1+ (1.0,0.0) [0.0|1] ""  Vector__XXX
 SG_ BM_Telematik_Abbruchgrund : 38|6@1+ (1.0,0.0) [0.0|63] ""  Vector__XXX
 SG_ BM_PiloPa : 44|1@1+ (1.0,0.0) [0.0|1] ""  Vector__XXX
 SG_ SAL_TA_Blinken_Status : 45|3@1+ (1.0,0.0) [0.0|7] ""  Vector__XXX
 SG_ BM_WBA_Warnblinken : 48|1@1+ (1.0,0.0) [0.0|1] ""  Vector__XXX
 SG_ SAL_RHP_Blinken_Status : 49|3@1+ (1.0,0.0) [0.0|7] ""  Vector__XXX
 SG_ SAL_RHP_Warnblinken : 52|1@1+ (1.0,0.0) [0.0|1] ""  Vector__XXX

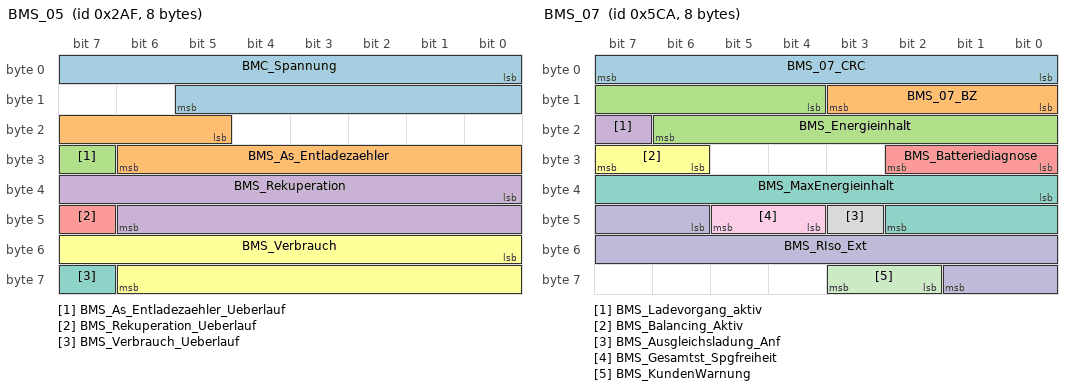
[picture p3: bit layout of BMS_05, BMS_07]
BO_ 687 BMS_05: 8 Gateway_Max
 SG_ BMC_Spannung : 0|14@1+ (0.0625,0) [0.0000|1023.7500] "Unit_Volt"  Vector__XXX
 SG_ BMS_As_Entladezaehler : 21|10@1+ (1,0) [0|1023] "Unit_AmperSecon"  Vector__XXX
 SG_ BMS_As_Entladezaehler_Ueberlauf : 31|1@1+ (1.0,0.0) [0.0|1] ""  Vector__XXX
 SG_ BMS_Rekuperation : 32|15@1+ (10,0) [0|327670] "Unit_WattSecond"  Kombi
 SG_ BMS_Rekuperation_Ueberlauf : 47|1@1+ (1.0,0.0) [0.0|1] ""  Kombi
 SG_ BMS_Verbrauch : 48|15@1+ (10,0) [0|327670] "Unit_WattSecond"  Kombi
 SG_ BMS_Verbrauch_Ueberlauf : 63|1@1+ (1.0,0.0) [0.0|1] ""  Kombi

BO_ 1482 BMS_07: 8 Gateway_Max
 SG_ BMS_07_CRC : 0|8@1+ (1,0) [0|255] ""  Kombi
 SG_ BMS_07_BZ : 8|4@1+ (1,0) [0|15] ""  Kombi
 SG_ BMS_Energieinhalt : 12|11@1+ (50,0) [0|102250] "Unit_WattHour"  Vector__XXX
 SG_ BMS_Ladevorgang_aktiv : 23|1@1+ (1.0,0.0) [0.0|1] ""  Vector__XXX
 SG_ BMS_Batteriediagnose : 24|3@1+ (1.0,0.0) [0.0|7] ""  Vector__XXX
 SG_ BMS_Balancing_Aktiv : 30|2@1+ (1.0,0.0) [0.0|3] ""  Vector__XXX
 SG_ BMS_MaxEnergieinhalt : 32|11@1+ (50,0) [0|102250] "Unit_WattHour"  Vector__XXX
 SG_ BMS_Ausgleichsladung_Anf : 43|1@1+ (1.0,0.0) [0.0|1] ""  Vector__XXX
 SG_ BMS_Gesamtst_Spgfreiheit : 44|2@1+ (1.0,0.0) [0.0|3] ""  Vector__XXX
 SG_ BMS_RIso_Ext : 46|12@1+ (5,0) [0|20465] "Unit_KiloOhm"  Vector__XXX
 SG_ BMS_KundenWarnung : 58|2@1+ (1.0,0.0) [0.0|3] ""  Kombi

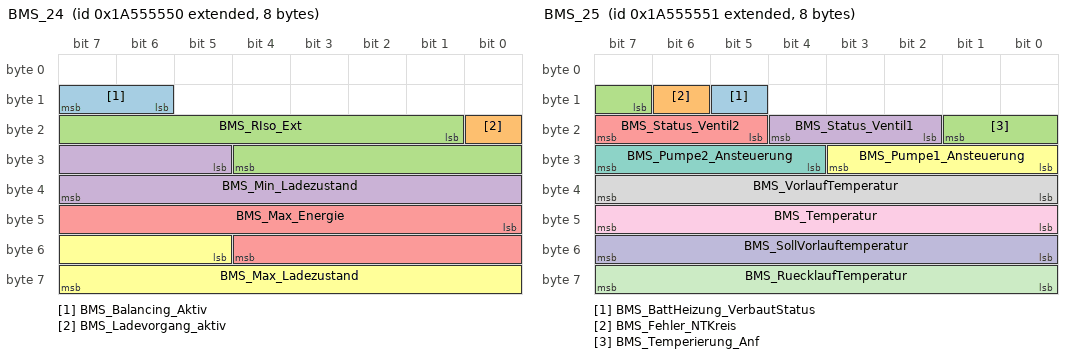
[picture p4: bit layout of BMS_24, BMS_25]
BO_ 2589283664 BMS_24: 8 Gateway_Max
 SG_ BMS_Balancing_Aktiv : 14|2@1+ (1.0,0.0) [0.0|3] ""  Vector__XXX
 SG_ BMS_Ladevorgang_aktiv : 16|1@1+ (1.0,0.0) [0.0|1] ""  Kombi
 SG_ BMS_RIso_Ext : 17|12@1+ (5,0) [0|20465] "Unit_KiloOhm"  Vector__XXX
 SG_ BMS_Min_Ladezustand : 29|11@1+ (0.05,0) [0.00|100.00] "Unit_PerCent"  Vector__XXX
 SG_ BMS_Max_Energie : 40|13@1+ (40,0) [0|327400] "Unit_WattHour"  Vector__XXX
 SG_ BMS_Max_Ladezustand : 53|11@1+ (0.05,0) [0.00|100.00] "Unit_PerCent"  Vector__XXX

BO_ 2589283665 BMS_25: 8 Gateway_Max
 SG_ BMS_BattHeizung_VerbautStatus : 13|1@1+ (1.0,0.0) [0.0|1] ""  Vector__XXX
 SG_ BMS_Fehler_NTKreis : 14|1@1+ (1.0,0.0) [0.0|1] ""  Vector__XXX
 SG_ BMS_Temperierung_Anf : 15|3@1+ (1.0,0.0) [0.0|7] ""  Vector__XXX
 SG_ BMS_Status_Ventil1 : 18|3@1+ (1.0,0.0) [0.0|7] ""  Vector__XXX
 SG_ BMS_Status_Ventil2 : 21|3@1+ (1.0,0.0) [0.0|7] ""  Vector__XXX
 SG_ BMS_Pumpe1_Ansteuerung : 24|4@1+ (10,0) [0|100] "Unit_PerCent"  Vector__XXX
 SG_ BMS_Pumpe2_Ansteuerung : 28|4@1+ (10,0) [0|100] "Unit_PerCent"  Vector__XXX
 SG_ BMS_VorlaufTemperatur : 32|8@1+ (0.5,-40) [-40.0|86.0] "Unit_DegreCelsi"  Vector__XXX
 SG_ BMS_Temperatur : 40|8@1+ (0.5,-40) [-40.0|86.5] "Unit_DegreCelsi"  Kombi
 SG_ BMS_SollVorlauftemperatur : 48|8@1+ (0.5,-40) [-40.0|86.5] "Unit_DegreCelsi"  Vector__XXX
 SG_ BMS_RuecklaufTemperatur : 56|8@1+ (0.5,-40) [-40.0|86.0] "Unit_DegreCelsi"  Vector__XXX

BO_ 2331595856 BMS_34: 32 Gateway_Max
 SG_ BMS_UBE : 16|16@1+ (5,-7400) [-7400|320000] "Unit_WattHour"  Vector__XXX
 SG_ BMS_UBE_T : 32|16@1+ (5,-7400) [-7400|320000] "Unit_WattHour"  Vector__XXX
 SG_ BMS_Max_UBE : 48|16@1+ (5,-7400) [-7400|320000] "Unit_WattHour"  Vector__XXX
 SG_ BMS_Nennspannung : 64|11@1+ (0.5,0) [0.0|1000.0] "Unit_Volt"  Vector__XXX
 SG_ BMS_DC_Ladeschuetze_Ist : 75|3@1+ (1.0,0.0) [0.0|7] ""  Vector__XXX
 SG_ BMS_Hauptschuetze_Ist : 78|3@1+ (1.0,0.0) [0.0|7] ""  Vector__XXX
 SG_ BMS_UBE_Indikator : 81|11@1+ (0.05,0) [0.00|100.00] "Unit_PerCent"  Vector__XXX
 SG_ BMS_UBE_Indik_last_update_km : 92|20@1+ (1,0) [0|1000000] "Unit_KiloMeter"  Vector__XXX
 SG_ BMS_Last_Chg_adeq_SOCswing_Day : 112|5@1+ (1,0) [1|31] "Unit_Day"  Vector__XXX
 SG_ BMS_Last_Chg_adeq_SOCswing_Month : 117|4@1+ (1,0) [1|12] "Unit_Month"  Vector__XXX
 SG_ BMS_Last_Chg_adeq_SOCswing_Year : 121|7@1+ (1,2000) [2001|2127] "Unit_Year"  Vector__XXX
 SG_ BMS_EnergieVorhalt : 128|16@1+ (0.1,0) [0.0|6400.0] "Unit_KiloWattHour"  Vector__XXX
 SG_ BMS_Range_Indikator : 144|11@1+ (0.05,0) [0.00|100.00] "Unit_PerCent"  Vector__XXX
 SG_ SOK_BMS_34_Signatur : 192|64@1+ (1,0) [1|18446744073709551615] "Unit_None"  Vector__XXX

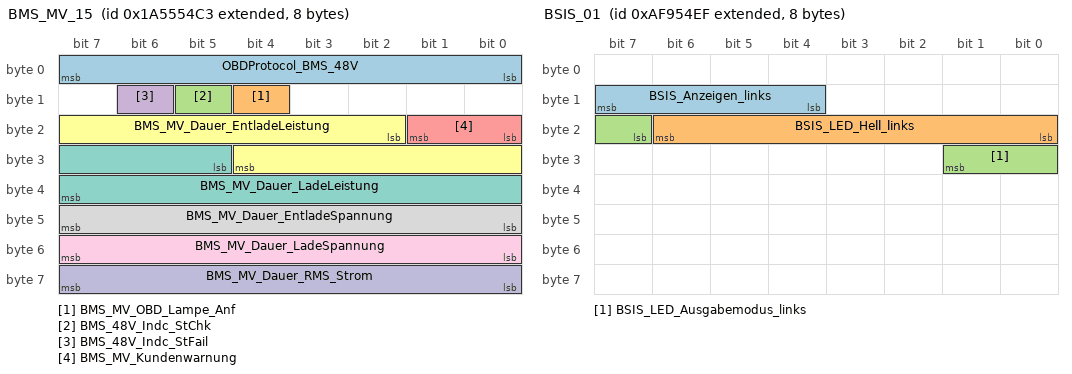
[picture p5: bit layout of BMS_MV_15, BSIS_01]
BO_ 2589283523 BMS_MV_15: 8 Gateway_Max
 SG_ OBDProtocol_BMS_48V : 0|8@1+ (1.0,0.0) [0.0|255] ""  Vector__XXX
 SG_ BMS_MV_OBD_Lampe_Anf : 12|1@1+ (1.0,0.0) [0.0|1] ""  Vector__XXX
 SG_ BMS_48V_Indc_StChk : 13|1@1+ (1.0,0.0) [0.0|1] ""  Vector__XXX
 SG_ BMS_48V_Indc_StFail : 14|1@1+ (1.0,0.0) [0.0|1] ""  Vector__XXX
 SG_ BMS_MV_Kundenwarnung : 16|2@1+ (1.0,0.0) [0.0|3] ""  Vector__XXX
 SG_ BMS_MV_Dauer_EntladeLeistung : 18|11@1+ (50,0) [0|102250] "Unit_Watt"  Vector__XXX
 SG_ BMS_MV_Dauer_LadeLeistung : 29|11@1+ (50,0) [0|102250] "Unit_Watt"  Vector__XXX
 SG_ BMS_MV_Dauer_EntladeSpannung : 40|8@1+ (0.25,0) [0.00|63.25] "Unit_Volt"  Vector__XXX
 SG_ BMS_MV_Dauer_LadeSpannung : 48|8@1+ (0.25,0) [0.00|63.25] "Unit_Volt"  Vector__XXX
 SG_ BMS_MV_Dauer_RMS_Strom : 56|8@1+ (1,0) [0|253] "Unit_Amper"  Vector__XXX

BO_ 2331596015 BSIS_01: 8 Gateway_Max
 SG_ BSIS_Anzeigen_links : 12|4@1+ (1.0,0.0) [0.0|15] ""  Kombi
 SG_ BSIS_LED_Hell_links : 16|7@1+ (1,0) [0|100] "Unit_PerCent"  Vector__XXX
 SG_ BSIS_LED_Ausgabemodus_links : 23|3@1+ (1.0,0.0) [0.0|7] ""  Vector__XXX

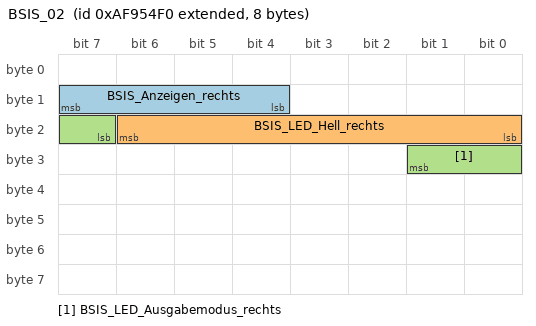
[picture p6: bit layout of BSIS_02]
BO_ 2331596016 BSIS_02: 8 Gateway_Max
 SG_ BSIS_Anzeigen_rechts : 12|4@1+ (1.0,0.0) [0.0|15] ""  Kombi
 SG_ BSIS_LED_Hell_rechts : 16|7@1+ (1,0) [0|100] "Unit_PerCent"  Vector__XXX
 SG_ BSIS_LED_Ausgabemodus_rechts : 23|3@1+ (1.0,0.0) [0.0|7] ""  Vector__XXX

BO_ 902 Charisma_03: 8 Gateway_Max
 SG_ CHA_Charisma_Taste2_LED : 0|2@1+ (1.0,0.0) [0.0|3] ""  Vector__XXX
 SG_ CHA_ReqPrgDispSetup : 2|4@1+ (1.0,0.0) [0.0|15] ""  Kombi
 SG_ CHA_Current_Mode_FPA : 6|6@1+ (1.0,0.0) [0.0|63] ""  HUD,Kombi
 SG_ CHA_Eco_Charisma_LED : 12|2@1+ (1.0,0.0) [0.0|3] ""  Vector__XXX
 SG_ CHA_Fahrer_Umschaltung : 14|1@1+ (1.0,0.0) [0.0|1] ""  Vector__XXX
 SG_ CHA_EV_LED : 15|1@1+ (1.0,0.0) [0.0|1] ""  Vector__XXX
 SG_ CHA_Ziel_FahrPr_AMB : 16|4@1+ (1.0,0.0) [0.0|15] ""  Vector__XXX
 SG_ CHA_Ziel_FahrPr_IVB : 20|4@1+ (1.0,0.0) [0.0|15] ""  Vector__XXX
 SG_ CHA_Kombi_Texte : 24|4@1+ (1.0,0.0) [0.0|15] ""  Kombi
 SG_ CHA_Ziel_FahrPr_KL : 28|4@1+ (1.0,0.0) [0.0|15] ""  Vector__XXX
 SG_ CHA_Ziel_FahrPr_HSP : 32|4@1+ (1.0,0.0) [0.0|15] ""  Vector__XXX
 SG_ CHA_StCurProfDft : 36|2@1+ (1.0,0.0) [0.0|3] ""  Kombi
 SG_ CHA_Ziel_FahrPr_RWB : 40|4@1+ (1.0,0.0) [0.0|15] ""  Vector__XXX
 SG_ CHA_Ziel_FahrPr_03_01 : 44|4@1+ (1.0,0.0) [0.0|15] ""  Vector__XXX
 SG_ CHA_Ziel_FahrPr_03_02 : 48|4@1+ (1.0,0.0) [0.0|15] ""  Vector__XXX
 SG_ CHA_Current_Mode : 52|4@1+ (1.0,0.0) [0.0|15] ""  Vector__XXX
 SG_ CHA_Charge_LED : 57|1@1+ (1.0,0.0) [0.0|1] ""  Vector__XXX
 SG_ CHA_Offroad_LED : 58|2@1+ (1.0,0.0) [0.0|3] ""  Vector__XXX
 SG_ CHA_Kombi_Texte_02 : 60|4@1+ (1.0,0.0) [0.0|15] ""  Kombi

BO_TX_BU_ 2536767280 :Gateway_Max,HUD,Kombi;
CM_ BO_ 2536717313 "BAP ASG message EfficiencyAssist (PEA)<br>
Sender: Kombi
Receiver: MSG";
CM_ BO_ 2536717314 "BAP ASG message EfficiencyAssist (PEA)<br>
Sender: Kombi
Receiver: MSG";
CM_ BO_ 2536717328 "BAP FSG message EfficiencyAssist (PEA)<br>
Sender: MSG<br>
Receiver: HU (MIB)";
CM_ BO_ 1635 "DLC=8 ab D4 gültig";
CM_ BO_ 870 "Nur die Kombination des statischen und toggelnden Signals ergibt den Blinktakt für die Hell & Dunkelphase";
CM_ BO_ 902 "ab MQB 7.2.1";

CM_ SG_ 2536705809 BAP_BC_FSG_02_Header "BC Funktionssteuergeraet zweites Sendesignal
(zusätzliches Signal für abzusichernde Inhalte)";

CM_ SG_ 2536734976 BAP_California_ASG_01_Header "California Anzeigesteuergerät";

CM_ SG_ 2536734992 BAP_California_FSG_01_Header "California Funktionssteuergeraet";

CM_ SG_ 2536719616 BAP_DisplayConfig_ASG_01_Header "Display Config Anzeigesteuergeraet";

CM_ SG_ 2536719617 BAP_DisplayConfig_ASG_02_Header "Display Config Anzeigesteuergeraet";

CM_ SG_ 2536719632 BAP_DisplayConfig_FSG_01_Header "Display Konfiguration Funktionssteuergeraet Kombi";

CM_ SG_ 2536717313 BAP_EfficAssist_ASG_02_Header "EfficiencyAssist Anzeigesteuergeraet 2";

CM_ SG_ 2536717314 BAP_EfficAssist_ASG_03_Header "EfficiencyAssist Anzeigesteuergeraet 3";

CM_ SG_ 2536717328 BAP_EfficAssist_FSG_01_Header "BAP dummy data";

CM_ SG_ 2536706819 BAP_Einheiten_ASG_04_Header "Einheiten Anzeigesteuergeraet";

CM_ SG_ 2536702977 BAP_HUD_ASG_02_Header "HUD Anzeigesteuergeraet";

CM_ SG_ 2536702978 BAP_HUD_ASG_03_Header "HUD Anzeigesteuergeraet 3";

CM_ SG_ 2536722945 BAP_IAA_PSO_ASG_02_Header "BAP Strecke für IAA & PSO
Anzeigesteuergeräte KI";

CM_ SG_ 2536722960 BAP_IAA_PSO_FSG_01_Header "BAP Strecke für IAA & PSO";

CM_ SG_ 2536704003 BAP_Innenlicht_ASG_04_Header "Innenlicht Anzeigesteuergeraet4";

CM_ SG_ 2536712704 BAP_OnlineFunction_ASG_01_Header "OnlineFunctions Anzeigesteuergeraet";

CM_ SG_ 2536712705 BAP_OnlineFunction_ASG_02_Header "OnlineFunctions Anzeigesteuergeraet";

CM_ SG_ 2536712720 BAP_OnlineFunction_FSG_01_Header "OnlineFunctions Funktionssteuergeraet";

CM_ SG_ 2536704518 BAP_OPS_ASG_07_Header "OPS Anzeigesteuergeraet 7";

CM_ SG_ 2536723713 BAP_PaCo_ASG_02_Header "PaCo Anzeigesteuergeraet2";

CM_ SG_ 2536723716 BAP_PaCo_ASG_05_Header "PaCo Anzeigesteuergeraet 5 HUD";

CM_ SG_ 2536723728 BAP_PaCo_FSG_01_Header "PaCo Funktionssteuergeraet";

CM_ SG_ 2536731136 BAP_RMeasurement_ASG_01_Header "RaceMeasurement ASG-Botschaft";

CM_ SG_ 2536731137 BAP_RMeasurement_ASG_02_Header "RaceMeasurement ASG-Botschaft
64 Byte PDU";

CM_ SG_ 2536731152 BAP_RMeasurement_FSG_01_Header "RaceMeasurement FSG-Botschaft";

CM_ SG_ 2536731153 BAP_RMeasurement_FSG_02_Header "RaceMeasurement FSG-Botschaft
64 Byte PDU";

CM_ SG_ 2536719872 BAP_SDS_ASG_01_Header "Sprach-Dialog-System Anzeigesteuergeraet";

CM_ SG_ 2536719888 BAP_SDS_FSG_01_Header "Sprach-Dialog-System
Funktionssteuergeraet";

CM_ SG_ 2536736001 BAP_SLCView_ASG_02_Header "SideLeaveCarView Anzeigesteuergeraet
LCU ID - 133dez";

CM_ SG_ 2536736016 BAP_SLCView_FSG_01_Header "SideLeaveCarView Funktionssteuergeraet
LCU ID - 133dez";

CM_ SG_ 2536711937 BAP_StartStopReasons_ASG_02_Head "LSG StartStopReasons zweite ASG Botschaft";

CM_ SG_ 2536720896 BAP_Statistics_ASG_01_Header "Statistics Anzeigesteuergeraet";

CM_ SG_ 2536720912 BAP_Statistics_FSG_01_Header "Statistics Funktionssteuergeraet";

CM_ SG_ 2536712448 BAP_Telefon2_ASG_01_Header "MQB AUDI: keine Verwendung im ZR Entry";

CM_ SG_ 2536712449 BAP_Telefon2_ASG_02_Header "Telefon2 Anzeigesteuergeraet
MMI <-> Head-Up Display";

CM_ SG_ 2536712464 BAP_Telefon2_FSG_01_Header "MQB AUDI: keine Verwendung im ZR Entry";

CM_ SG_ 2536712465 BAP_Telefon2_FSG_02_Header "BAP Strecke Telefon zum Kombi";

CM_ SG_ 2536712192 BAP_Telefon_ASG_01_Header "MQB AUDI: keine Verwendung im ZR Entry";

CM_ SG_ 2536712193 BAP_Telefon_ASG_02_Header "MQB AUDI: keine Verwendung im ZR Entry";

CM_ SG_ 2536712194 BAP_Telefon_ASG_03_Header "Telefon Anzeigesteuergeraet
Head-Up";

CM_ SG_ 2536712195 BAP_Telefon_ASG_04_Header "Telefon Anzeigesteuergeraet
MMI<->Head-Up Display";

CM_ SG_ 2536712208 BAP_Telefon_FSG_01_Header "MQB AUDI: keine Verwendung im ZR Entry";

CM_ SG_ 2536712209 BAP_Telefon_FSG_02_Header "MQB AUDI: keine Verwendung im ZR Entry";

CM_ SG_ 2583694872 BCM1_AuthTime_Req_Data "AuthTime - Authentische Zeit
ISO-TP Datenkanal - NA2FID

BCM1 an Funktion Authentische Zeit (Request)";

CM_ SG_ 2583825944 BCM1_AuthTime_Resp_Data "AuthTime - Authentische Zeit
ISO-TP Datenkanal - NA2FID
Response Funktion 0x18 AuthTime

Funktion Authentische Zeit an BCM1 (Transceiver Modul) (Response)";

CM_ SG_ 1626 APS_Tongeber_defekt "Status APS-Tongeber zur HMI-Ansteuerng der RCTA-Funktion";
CM_ SG_ 1626 BCM1_AFS_Lampe "Ansteuerung der AFS-Fehlermeldung im Kombi";
CM_ SG_ 1626 BCM1_EasyEntry_Status "Status EasyEntry für Lenksäule (wird auch von IVB verwendet)";
CM_ SG_ 1626 BCM1_Fahrlicht_Hinweis "Signal zum Kombi um den Hinweis 'Bitte Fahrlicht einschalten' anzufordern";
CM_ SG_ 1626 BCM1_Hinweis_Lichtnachlauf "Signal dient der Anzeige eines aktiven Lichtnachlaufes beim automatischen Abschalten der Klemme S und Klemme 15. Der Lichtnachlauf wird gestartet, wenn die Klemme 15 bei aktivem Fahrlicht deaktiviert wird.";
CM_ SG_ 1626 BCM1_Kl_15_HW_erkannt "Erkennung Klemme 15 (Hardware) vom BCM1
";
CM_ SG_ 1626 BCM1_Kl_15_Sig_HW_erkannt "Erkennung Klemme 15 Signal (Hardware) vom BCM1";
CM_ SG_ 1626 BCM1_LDS_Stellung "Das Signal wird vom AFS / LWR Steuergerät empfangen und dient der Verifizierung der Lichtdrehschalterstellung. Intelligente Lichtfunktionen wie dyn. KL und gleitende Leuchtweite (GLW) nur bei LDS = 'AUTO'.";
CM_ SG_ 1626 BCM1_Lenksaeule_aktiv "Lenksaeulenverstellung aktiv";
CM_ SG_ 1626 BCM1_Licht_Warn "Lichtwarnung";
CM_ SG_ 1626 BCM1_Lichtwarn_Texte "Anforderung von Lichtwarnungen vom BCM1 zum Kombi
MLB: nur Werte 0..2";
CM_ SG_ 1626 BCM1_MH_Schalter "Motorhaubenkontakt";
CM_ SG_ 1626 BCM1_MH_WIV_Schalter "Bewerteter Motorhaubenkontakt fuer WIV";
CM_ SG_ 1626 BCM1_NV_Taster "BCM1_NV_Taster gibt an, ob der NightVision-Taster im Lichtdrehschalter-Modul aktuell betaetigt wird.";
CM_ SG_ 1626 BCM1_Reisemodus_Texte "Ansteuerung der Reisemodus-Texte im Kombi";
CM_ SG_ 1626 BCM1_Rueckfahrlicht_Schalter "Rückfahrlichtschalter
ab MQB/ MLBevo: Die Ganginformation wird unentprellt übertragen, im AT-Getriebe wird evtl. kurzzeitig der R-Gang angezeigt. Eine Entprellung muß im Empfänger erfolgen (typisch 400ms).";
CM_ SG_ 1626 BCM1_Spannungs_Anf "Forderung des BCM1-SG's zur Spannungsanhebung.";
CM_ SG_ 1626 BCM1_Valet_Parking_Taster "Valet Parking Taster ";
CM_ SG_ 1626 BCM1_Warnblink_Taster "Warnblinktaster";
CM_ SG_ 1626 BCM_Anf_AAW_MoLaWa "Signal zur Anforderung der Antrieb-Aktiv-Warnung und Motorlaufwarnung. Die Berechnung erfolgt im BCM. Die Ausgabe der Warnungen wird vom Kombiinstrument realisiert";
CM_ SG_ 1626 BCM_Bremsbelag_Sensor "Sensorsignal der Stromschleife  für Bremsbelagverschleiß aktuell, entstört, unbewertet";
CM_ SG_ 1626 BCM_Bremsfluessigkeit_Sensor "Kontaktsignal des Sensorschalters für die Bremsflüssigkeitsreserve aktuell, entstört, unbewertet";
CM_ SG_ 1626 BCM_Charisma_Taste2 "Betätigung der Charisma-Taste 2";
CM_ SG_ 1626 BCM_Eco_Charisma_Taste "Betätigung Taster ECO alias BlueKey oder Charisma";
CM_ SG_ 1626 BCM_Handbremse_Hinweis "Infotext fuer das Kombiinstrument zur Oeffnung der elektr. Heckklappe.";
CM_ SG_ 1626 BCM_HBFS_EOE_aktiv "Elektrisch-Oeffnen-Motor aktiv";
CM_ SG_ 1626 BCM_HDF_betaetigt "Betätigung Taster für Heckdeckelfernentriegelung in Mittelkonsole";
CM_ SG_ 1626 BCM_HFS_EOE_aktiv "Elektrisch-Oeffnen-Motor aktiv";
CM_ SG_ 1626 BCM_Hybrid_StartStopp_Taste "Betaetigung Taster 'Hybrid' oder alternativ Taster 'Start/Stopp Deaktivierung', je nach Verbau";
CM_ SG_ 1626 BCM_Hybrid_StSt_Taste_Fehler "Fehlerflag, wenn Tasterdiagnose im BCM für den StSt-Taster anschlägt.";
CM_ SG_ 1626 BCM_Kuehlmittel_Sensor "Signal der Sensorelektroden für die Kühlmittelreserve aktuell, entstört, bewertet (OK/Mangel)";
CM_ SG_ 1626 BCM_Kuehlmittel_Sensor_02 "Signal der zweiten Sensorelektroden für die Kühlmittelreserve aktuell, entstört, bewertet (OK/Mangel)";
CM_ SG_ 1626 BCM_Offroad_Taste "Betätigung der Offroad-Taste";
CM_ SG_ 1626 BCM_ValetTaster_Fkts_LED "Im MQB beschreibt das Signal nur den Zustand der Funktion Valet Parking (aktiv/ inaktiv)
Im MLBevo wird über das Signal zusätzlich die ValetTaster_Fkts_LED (an/ aus) gesteuert";
CM_ SG_ 1626 BCM_Waehlhebel_P_Hinweis "Infotext NAR für die Vorbedingung 'Waehlhebel in P' für Öffnen der Heckklappe über den Fahrerrauminnentaster.";
CM_ SG_ 1626 BCM_Waschwasser_Sensor "Signal der Sensorelektroden für die Waschwasserreserve aktuell, entstört, bewertet (OK/Mangel)";
CM_ SG_ 1626 DWA_Alarmquelle "Signalisiert den Auslösegrund der DWA";
CM_ SG_ 1626 DWA_Einschraenkung "Signalisiert Fehler der DWA";
CM_ SG_ 1626 Gong_TFL_Umschaltung "Aktivierung / Deaktivierung des TFL per Affengriff wird mit einem Gong im Kombi quittiert.";
CM_ SG_ 1626 LRH_Taster "Tasterbetätigung Lenkradheizung";

CM_ SG_ 2527679637 BCM_anf_VLW "Über dieses Signal wird die vom BCM errechnete Verlassenswarnung sowie die Meldung eines aktiven Rollfaehigkeitsmodus zur Ausgabe durch das Kombinstrument angefordert.";
CM_ SG_ 2527679637 BCM_Defrost_Taste "Defrost AN/AUS und Status";
CM_ SG_ 2527679637 BCM_FAS_Taster "Betätigung des FAS-Tasters Schalterleiste.";
CM_ SG_ 2527679637 BCM_FSH_Taste "Frontscheibenheizung AN/AUS und Status";
CM_ SG_ 2527679637 BCM_HSH_Taste "Heckscheibenheizung AN/AUS und Status";
CM_ SG_ 2527679637 BCM_LTM_Allwetterl_Status "Allwetterlicht Status zur Anzeige im Allwetterlicht-PopUp";
CM_ SG_ 2527679637 BCM_LTM_Nebell_Status "Nebellicht Status zur Anzeige im Nebellicht-PopUp";
CM_ SG_ 2527679637 BCM_LTM_Nebelschluss_Status "Nebelschlusslicht Status zur Anzeige im Nebelschlusslicht-PopUp";
CM_ SG_ 2527679637 BCM_LTM_PopUp_Anf "Anforderung der entsprechenden Anzeige im Kombi bei Aussenlichtsteuerung über LTM (LichtTastenModul)";
CM_ SG_ 2527679637 BCM_LTM_PopUp_Inhalt "Definition Inhalt des PopUps zur Aussenlichtbedienung";
CM_ SG_ 2527679637 BCM_LTM_PopUp_Status "Auswahl der aktiven Aussenlichtfunktion im LTM PopUp";
CM_ SG_ 2527679637 BCM_LTM_PopUp_Texte "Anforderung Kombi-Texte bei Bedienung Aussenlicht über LTM (LichtTastenModul)";
CM_ SG_ 2527679637 CPD_Warnung "Ansteuerung einer Warnung im Kombi/ iID mit Ton oder ohne Ton durch die Fkt. ChildPresenceDetection";
CM_ SG_ 2527679637 LiSi_Touch_Event "Touch_Events für Informationen einer Funktionsauslösung auf der LiSi, welches dann für bspw. ein akustiches Signal zentral umgesetzt werden können.";
CM_ SG_ 2527679637 LTMs_01_alt "Veraltet-Bit für den LIN-Frame LTMs_01";
CM_ SG_ 2527679637 MiKo_Tisch_Positionswarnung "Positionswarnung des Tisches in der Mittelkonsole";

CM_ SG_ 2463978607 BCM_RGB_Blau "Farbanteil 'Blau'";
CM_ SG_ 2463978607 BCM_RGB_Dimmrampe "Vorgabe 'Dimmzeit' für RGB-Slave";
CM_ SG_ 2463978607 BCM_RGB_Dimmzeit_Zeitbasis "Umschaltung der Zeitbasis für die Berechnung der Dimmzeit zwischen 250ms (Altwert, log. Signalwert: 1) und 50ms (log. Signalwert: 0)";
CM_ SG_ 2463978607 BCM_RGB_Gruen "Farbanteil 'Grün'";
CM_ SG_ 2463978607 BCM_RGB_Intensitaet "Intensität für RGB-Slave";
CM_ SG_ 2463978607 BCM_RGB_Normierung_Intensitaet "Normierung der Intensität für die RGB-Slaves:
0 = keine Normierung
1 = Normierung";
CM_ SG_ 2463978607 BCM_RGB_Rot "Farbanteil 'Rot'";

CM_ SG_ 2463978609 BCM_Relais_2_Batterie "Zeigt den Zustand des vom BCM bzw KFG angesteuerten Laderelais einer verbauten 2. Batterie an";
CM_ SG_ 2463978609 FA_Hoehenwert_HL_01 "Aktueller Höhenwert (Rohwerte) Hinten Links; ungefiltertes Signal
Einheit, Offset und Faktor sind abhänig von 'FA_Hoehenwert_kalibriert'";
CM_ SG_ 2463978609 FA_Hoehenwert_VL_01 "Aktueller Höhenwert (Rohwerte) Vorne Links; ungefiltertes Signal
Einheit, Offset und Faktor sind abhänig von 'FA_Hoehenwert_kalibriert'";
CM_ SG_ 2463978609 HSH_LED "LED Ansteuerung Heckscheibenheizung";
CM_ SG_ 2463978609 HSH_Status "Status Heckscheibenheizung
";
CM_ SG_ 2463978609 KRH_Stufe_LED_li "Statusmeldung Kopfraumheizung links";
CM_ SG_ 2463978609 KRH_Stufe_LED_re "Statusmeldung Kopfraumheizung rechts";
CM_ SG_ 2463978609 Niveausensor_HL_verbaut "Signal wird gesetzt, wenn Niveausensor_hinten codiert wird.";
CM_ SG_ 2463978609 Niveausensor_VL_verbaut "Signal wird gesetzt, wenn Niveausensor_vorne codiert wird.";
CM_ SG_ 2463978609 SIL_Stufe_LED_li "Statusmeldung Sitzlüftung links";
CM_ SG_ 2463978609 SIL_Stufe_LED_re "Statusmeldung Sitzlüftung rechts";

CM_ SG_ 2463978887 BDM_Kommunikationsbasis "Signal zeigt die Kommunikationsbasis des BDMs an";
CM_ SG_ 2463978887 BDM_ResponseError "siehe LIN2.0-Specification
(Darf nicht über ein Fehlergueltigkeitsbit abgesichtert werden!)";
CM_ SG_ 2463978887 BDM_Status_dyn "Statusmeldung Batteriedatenmodul";

CM_ SG_ 2463978882 BedienDisp_hbfs_01_BZ "4bit Botschaftszähler, wird mit jeder Sendebotschaft inkrementiert";
CM_ SG_ 2463978882 BedienDisp_hbfs_01_CRC "Für MLB:
Berechnung siehe Lastenheft 'Kommunikationsabsicherung für FlexRay und CAN'
Ab MQB und MLBevo:
Berechnung siehe Lastenheft 'End-to-End Kommunikationsabsicherung'

Endwerte siehe Begleitdokument 'S-PDU Kennungsfolgen'";
CM_ SG_ 2463978882 BedienDisp_hbfs_control_vol "HMI Volume Steuerung via MCC4 HBFS Touch Display";
CM_ SG_ 2463978882 BedienDisp_hbfs_control_vol_02 "HMI Volume Wertebereich via MCC4 HBFS Touch Display";
CM_ SG_ 2463978882 BedienDisp_hbfs_fader "HMI Fader/Soundfokus Steuerung via MCC4 HBFS Touch Display

Fader_Front
Fader_Rear";
CM_ SG_ 2463978882 BedienDisp_hbfs_Lordose_hoch "Anforderung MCC4 Lordosenwölbung nach oben zu verschieben.";
CM_ SG_ 2463978882 BedienDisp_hbfs_Lordose_runter "Anforderung MCC4 Lordosenwölbung nach unten zu verschieben.";
CM_ SG_ 2463978882 BedienDisp_hbfs_Lordose_vor "Anforderung MCC4 Lordosenwölbung pneumatisch zu vergrößern.";
CM_ SG_ 2463978882 BedienDisp_hbfs_Lordose_zurueck "Anforderung MCC4 Lordosenwölbung zu verkleinern.";
CM_ SG_ 2463978882 BedienDisp_hbfs_sound "Source of Audio signal";
CM_ SG_ 2463978882 BedienDisp_hbfs_sound_fokus "HMI Sound Fokus Zonen via MCC4 HBFS Touch Display";
CM_ SG_ 2463978882 BedienDisp_hbfs_surround "HMI Surround Steuerung via MCC4 HBFS Touch Display";
CM_ SG_ 2463978882 BedienDisp_hbfs_surround_02 "HMI Surround Wertebereich via MCC4 HBFS Touch Display";
CM_ SG_ 2463978882 BedienDisp_hbfs_touch "Touchsignale MCC4 Toch-ABT HBFS";
CM_ SG_ 2463978882 BedienDisp_hbfs_UseCase_Pos "Anforderung MCC Sitz UseCaseposition zu verstellen";
CM_ SG_ 2463978882 BedienDisp_HBFSFo_Bestaetigung "HMI Bestätigung der Warnung nach Softstop Lehnenverstellung";
CM_ SG_ 2463978882 BedienDisp_HBFSFo_Stoerung "Störung des MCC4-ABT an Kombi und Sitz";

CM_ SG_ 2463978881 BedienDisp_hfs_01_BZ "4bit Botschaftszähler, wird mit jeder Sendebotschaft inkrementiert";
CM_ SG_ 2463978881 BedienDisp_hfs_01_CRC "Für MLB:
Berechnung siehe Lastenheft 'Kommunikationsabsicherung für FlexRay und CAN'
Ab MQB und MLBevo:
Berechnung siehe Lastenheft 'End-to-End Kommunikationsabsicherung'

Endwerte siehe Begleitdokument 'S-PDU Kennungsfolgen'";
CM_ SG_ 2463978881 BedienDisp_hfs_control_vol "HMI Volume Steuerung via MCC4 HFS Touch Display";
CM_ SG_ 2463978881 BedienDisp_hfs_control_vol_02 "HMI Volume Wertebereich via MCC4 HFS Touch Display";
CM_ SG_ 2463978881 BedienDisp_hfs_fader "HMI Fader/Soundfokus Steuerung via MCC4 HFS Touch Display

Fader_Front
Fader_Rear";
CM_ SG_ 2463978881 BedienDisp_hfs_Lordose_hoch "Anforderung MCC4 Lordosenwölbung nach oben zu verschieben.";
CM_ SG_ 2463978881 BedienDisp_hfs_Lordose_runter "Anforderung MCC4 Lordosenwölbung nach unten zu verschieben.";
CM_ SG_ 2463978881 BedienDisp_hfs_Lordose_vor "Anforderung MCC4 Lordosenwölbung pneumatisch zu vergrößern.";
CM_ SG_ 2463978881 BedienDisp_hfs_Lordose_zurueck "Anforderung MCC4 Lordosenwölbung zu verkleinern.";
CM_ SG_ 2463978881 BedienDisp_hfs_sound "Source of Audio signal";
CM_ SG_ 2463978881 BedienDisp_hfs_sound_fokus "HMI Sound Fokus Zonen via MCC4 HFS Touch Display";
CM_ SG_ 2463978881 BedienDisp_hfs_surround "HMI Surround Steuerung via MCC4 HFS Touch Display";
CM_ SG_ 2463978881 BedienDisp_hfs_surround_02 "HMI Surround Wertebereich via MCC4 HFS Touch Display";
CM_ SG_ 2463978881 BedienDisp_hfs_touch "Touchsignale MCC4 Toch-ABT HFS";
CM_ SG_ 2463978881 BedienDisp_hfs_UseCase_Pos "Anforderung MCC Sitz UseCaseposition zu verstellen";
CM_ SG_ 2463978881 BedienDisp_HFSFo_Bestaetigung "HMI Bestätigung der Warnung nach Softstop Lehnenverstellung";
CM_ SG_ 2463978881 BedienDisp_HFSFo_Stoerung "Störung des MCC4-ABT an Kombi und Sitz";

CM_ SG_ 1635 BEM_Anf_KL15_schalten "Abschaltempfehlung bzw. Verhinderung der automatischen Abschaltung Kl15 durch das BCM";
CM_ SG_ 1635 BEM_Batt_Ab "Batterieverbindungskontrolle:
0x0: Batterie am Bordnetz
0x1: Batterie ab erkannt";
CM_ SG_ 1635 BEM_Batteriediagnose "Anzeige von Textwarnungen";
CM_ SG_ 1635 BEM_DFM "Generatorauslastungsgrad, vom Generator über LIN an das Gateway gesandt. Das Motorsteuergerät regelt auf dieses Signal die PTC, das Energiemanagement im BSG/BCM kalkuliert die Bordnetzauslastung";
CM_ SG_ 1635 BEM_EMLIN_ungueltig "Energie-Lin - Signale sind ungültig vom Slave Batteriedatenmodul oder Generator
0 = Signale gültig
1 = Signale ungültig";
CM_ SG_ 1635 BEM_Generatordiagnose "Ansteuerung Generatorwarnleuchte im Kombi
";
CM_ SG_ 1635 BEM_HL_Kontingentierung "Leistungskontingente für Heizsysteme";
CM_ SG_ 1635 BEM_HL_Regelung_Status "Status Regelung Heizleistung
";
CM_ SG_ 1635 BEM_Ladezustand "Ladezustand der Niedervoltbatterie
";
CM_ SG_ 1635 BEM_MMI_Vorwarnung "Anzeige Vorwarnung MMI-Abschaltung (Initialisierungswert aus EEprom)
";
CM_ SG_ 1635 BEM_Red_Innengeblaese "Reduzierung Innengebläse
";
CM_ SG_ 1635 BEM_REK_aktiv "Rekuperationsfreigabe vom Energiemanagement
0x0 = keine Rekuperationsfreigabe
0x1 = Rekuperationsfreigabe";
CM_ SG_ 1635 BEM_STH_Einschaltverbot "Einschränkung Standheizung/-lüftung durch BEM: Setzt der BEM das Bit, dann darf die Standheizung nicht mehr einschalten
(Die Standheizung muss aber nicht abschalten, sondern darf weiterbrennen)
(Initialisierungswert aus EEprom)
";
CM_ SG_ 1635 BEM_STH_Zielzeit "Maximal mögliche Zeit für den Standheizungsbetrieb, um die Startfähigkeit nicht zu gefährden";
CM_ SG_ 1635 BEM_UBDM "Batteriespannung, gemessen vom Batteriedatenmodul";
CM_ SG_ 1635 BEM_UGenSoll "Sollspannungsvorgabe an den Generator, beinhaltet temperaturoptimierte Batterieladung und Rekuperation";
CM_ SG_ 1635 MIB_Stromsparmodus "Signal beschreibt die Aktivierung für den Stromsparmodus beim MIB.
Bei AUS (= 0) gibt es keine weitere Anforderung an die MIB-Komponenten.
Bei EIN (= 1) werden alle MIB Komponenten in einen Stromsparmodus versetzt.";
CM_ SG_ 1635 NVEM_Abschaltstufe "Abschaltstufe aus dem Ruheenergiemanagement
Maßnahmen des Empfängers werden im QLAH Ruhestrommanagement definiert";
CM_ SG_ 1635 NVEM_Anf_SD_schalten "Anforderung Nachlauf für den Steckdosenbetrieb
Initialisierungswert aus EEprom";
CM_ SG_ 1635 NVEM_Batterie_Service "Anforderung einer Batterie-Service - Anzeige / Anforderung an die Werkstatt über MOD";
CM_ SG_ 1635 NVEM_Freigabe_OnlineUpdate "Freigabe für Online-Update durch Energiemanagement";
CM_ SG_ 1635 NVEM_Freigabe_ORU4 "Bestätigung oder Ablehnung eines konkreten, angefragten Online Updates durch das Energiemanagements";
CM_ SG_ 1635 NVEM_Freigabe_ZusBatt_Laden "NVEM gibt die Freigabe zum Schließen des Laderelais im Ruhebetrieb (z.B. bei Verwendung eines Ladegerätes)";
CM_ SG_ 1635 NVEM_Verbraucherabsch_Anz "Information über eine Verbraucherbschaltung durch das Energiemanagement";

CM_ SG_ 1163 BEM_06_BZ "4bit Botschaftszähler, wird mit jeder Sendebotschaft inkrementiert";
CM_ SG_ 1163 BEM_06_CRC "Für MLB:
Berechnung siehe Lastenheft 'Kommunikationsabsicherung für FlexRay und CAN'
Ab MQB und MLBevo:
Berechnung siehe Lastenheft 'End-to-End Kommunikationsabsicherung'

Endwerte siehe Begleitdokument 'S-PDU Kennungsfolgen'";
CM_ SG_ 1163 HLR_PTC_linear_Freigabe "Freigabe des EEM für den linearen PTC-Zuheizer";
CM_ SG_ 1163 NVEM2_Status_FuSiFahrt "Status sicherheitsrelevante Diagnosen NVEM";
CM_ SG_ 1163 NVEM2_Typ_EnergieNetz "Identifizierte NV-Energiearchitektur";
CM_ SG_ 1163 NVEM_Betriebsart "Betriebsart des Niedervolt - Energiemanagements";
CM_ SG_ 1163 NVEM_Bordnetzdiagnose "Wird vom NVEM im NV-Netz ein Bordnetz-Fehler erkannt, so soll dies zu einer mehrstufigen Anzeige führen.";
CM_ SG_ 1163 NVEM_Energie_Klima_Vorgabe "NVEM-Energievorgabe für Klima-Vorkonditionierung";
CM_ SG_ 1163 NVEM_Energienetz_Status "NVEM kommuniziert abgesichert den Zustand des Energienetzes.";
CM_ SG_ 1163 NVEM_Ladezustand "Ladezustand des NV-Hauptspeichers.";
CM_ SG_ 1163 NVEM_Last_Anf "Das NVEM fordert für die Batteriediagnose einen Lastimpuls vom Fahrzeug an, der durch kontrollierte Verbraucherzuschaltungen (z. B. Aktivierung Heckscheibenheizung) generiert wird";
CM_ SG_ 1163 NVEM_PTC_Sollstufe "Vorgabe des BEM an das BCM zur Aktivierung der geforderten PTC - Stufe.
Das MSG kopiert dies auf das Signal MO_PTC_Status";
CM_ SG_ 1163 NVEM_Red_KomfortVerbrauch "Master - SubMaster Kommunikation";
CM_ SG_ 1163 NVEM_STH_ZielzeitLang "Energetisch erlaubte Betriebszeit im Zielzeitkonzept für Standheizungen mit 2 Stunden Laufzeit";
CM_ SG_ 1163 NVEM_Vorgabe_Leistungsstufe "Ermittelte Leistungsstufe der Energiequelle";

CM_ SG_ 2463978850 BEM_07_BZ "4bit Botschaftszähler, wird mit jeder Sendebotschaft inkrementiert";
CM_ SG_ 2463978850 BEM_07_CRC "Für MLB:
Berechnung siehe Lastenheft 'Kommunikationsabsicherung für FlexRay und CAN'
Ab MQB und MLBevo:
Berechnung siehe Lastenheft 'End-to-End Kommunikationsabsicherung'

Endwerte siehe Begleitdokument 'S-PDU Kennungsfolgen'";
CM_ SG_ 2463978850 NVEM2_VerbrZustandsAnf "Dieses Signal soll bei FuSi-relevanten Energienotsituationen die Reaktion bei den Nichtdynamischen Verbrauchern auslösen.";
CM_ SG_ 2463978850 NVEM3_Absch_SCR "Abschaltung der SCR-Heizung durch das NVEM bei energetisch kritischen Zuständen.";
CM_ SG_ 2463978850 NVEM_Batt_Temp_Hinweis "Anforderung Kühlungsunterstützung der NV - Batterie";
CM_ SG_ 2463978850 NVEM_Bordnetz_Information "Informationsanzeigen zum 12V - Bordnetz";
CM_ SG_ 2463978850 NVEM_NVStuetzungAnf "Aktivierung / Deaktivierung Primärenergieversorger";
CM_ SG_ 2463978850 NVEM_Verbraucher_Information "Mit diesem Signal löst Das NVM eine Anzeige bzgl. einer bevorstehenden oder erfolgten Verbraucherabschaltung aus";

CM_ SG_ 870 Blinken_li_Fzg_Takt "Fzg-Takt Blinker links

";
CM_ SG_ 870 Blinken_li_Kombi_Takt "Kombi-Takt Blinker links

";
CM_ SG_ 870 Blinken_re_Fzg_Takt "Fzg-Takt Blinker rechts

";
CM_ SG_ 870 Blinken_re_Kombi_Takt "Kombi-Takt Blinker rechts

";
CM_ SG_ 870 Blinkmodi_02_BZ "4bit Botschaftszähler, wird mit jeder Sendebotschaft inkrementiert";
CM_ SG_ 870 Blinkmodi_02_CRC "Für MLB:
Berechnung siehe Lastenheft 'Kommunikationsabsicherung für FlexRay und CAN'
Ab MQB und MLBevo:
Berechnung siehe Lastenheft 'End-to-End Kommunikationsabsicherung'

Endwerte siehe Begleitdokument 'S-PDU Kennungsfolgen'";
CM_ SG_ 870 BM_Autobahn "Status Autobahnblinken
";
CM_ SG_ 870 BM_Crash "Status Crashblinken
";
CM_ SG_ 870 BM_DWA_Alarm "Status DWA-Alarmblinken
";
CM_ SG_ 870 BM_DWA_ein "Status Quittierungsblinken DWA";
CM_ SG_ 870 BM_GDO "Blinken bei UGDO anlernen

";
CM_ SG_ 870 BM_HD_Oeffnung_angelernt "HD_Rueckmeld_prog eine Blinkerquittierung wird beim BCM2 angefordert.
Wenn die Geschwindigkeit kleiner einer vorgegebenen Schwelle (default 2km/h) ist wird das Signal BM_HD_Öffnung_angelernt versendet und die Blinkerquittierung ausgelöst";
CM_ SG_ 870 BM_links "Richtungsblinken links

";
CM_ SG_ 870 BM_NBA_n_codiert_n_aktiv "Notbremsanzeige nicht codiert/nicht aktiv (Fehler)";
CM_ SG_ 870 BM_NBA_Status "Notbremsanzeige Status nicht aktiv / BRL Dunkelphase / BRL Hellphase";
CM_ SG_ 870 BM_Not_Bremsung "Das Signal BM_Not_Bremsung  zeigt an,  ob ein Warnblinken aufgrund einer vom Bremssystem signalisierten Notbremsung aktiv ist.";
CM_ SG_ 870 BM_Panik "Panikblinken
";
CM_ SG_ 870 BM_PiloPa "Quittierungsblinken bei pilotierten Parkvorgängen";
CM_ SG_ 870 BM_Recas "Blinkermodus RECAS  (RearEndCollisionAlertSignal)";
CM_ SG_ 870 BM_rechts "Richtungsblinken rechts

";
CM_ SG_ 870 BM_Rollenmodus_Blinken "Das Signal wird statisch gesetzt, wenn die Blinkerart Rollenmodus_Blinken aktiv ist.";
CM_ SG_ 870 BM_Taxi_Notalarm "Blinken bei Taxi-Not-Alarm

";
CM_ SG_ 870 BM_Telematik "Telematikblinken
";
CM_ SG_ 870 BM_Telematik_Abbruchgrund "Gibt bei erwaretem aber ausbleibendem Flankenanstieg der BM_Telematik an wieso die Ausführung verhindert wurde. Bei Flankenabfall der BM_Telematik wird angegeben wieso die Ausführung beendet wurde.

Bei nicht bereitem Sender soll 'init' gesendet werden,";
CM_ SG_ 870 BM_Warnblinken "Warnblinken

";
CM_ SG_ 870 BM_WBA_Warnblinken "Rückkanal des durch WBA (Warnen, Bremsen, Ausweichen) angeforderten Warnblinken";
CM_ SG_ 870 BM_WBT_Beleuchtung "Aktivierung Warnblinktasterfunktionsbeleuchtung
Warnblinktasterfunktionsbeleuchtung soll aktiviert werden (statisch auf 1)";
CM_ SG_ 870 BM_Wischblinken "Blinkermodus Wisch_Blinken";
CM_ SG_ 870 BM_ZV_auf "Blinken bei ZV auf

";
CM_ SG_ 870 BM_ZV_zu "Blinken bei ZV zu

";
CM_ SG_ 870 SAL_RHP_Blinken_Status "SAL Rückmeldung Rush Hour Pilot Blinker-Status an Funktion RHP";
CM_ SG_ 870 SAL_RHP_Warnblinken "Rückkanal des durch RHP angeforderten Warnblinken";
CM_ SG_ 870 SAL_TA_Blinken_Status "SAL RückmeldungTravelAssist Blinker-Status an Funktion TA (MFK)";

CM_ SG_ 687 BMC_Spannung "actual voltage of the battery / Momentanwert: Batteriespannung";
CM_ SG_ 687 BMS_As_Entladezaehler "Signal zur Berechnung des Lastprofils durch die RWB";
CM_ SG_ 687 BMS_As_Entladezaehler_Ueberlauf "Wird beim ersten Überlauf von BMS_As_Entladezahler auf 1 gesetzt. Reset über KL15-Wechsel";
CM_ SG_ 687 BMS_Rekuperation "Zähler: Anzeigesignal: Energiezufuhr in die HV-Batterie (Reku). Darf nicht durch Laden der Batterie bedatet werden";
CM_ SG_ 687 BMS_Rekuperation_Ueberlauf "Rekuperationleistungssignal BMS_Rekuperation mindest 1x übergelaufen";
CM_ SG_ 687 BMS_Verbrauch "Zähler: Energieentnahme aus der HV-Batterie";
CM_ SG_ 687 BMS_Verbrauch_Ueberlauf "Verbrauchssignal mindest 1x übergelaufen";

CM_ SG_ 1482 BMS_07_CRC "Für MLB:
'Berechnung siehe Lastenheft 'Kommunikationsabsicherung für FlexRay und CAN''

Ab MQB und MLBevo:
'Berechnung siehe Lastenheft 'End-to-End Kommunikationsabsicherung''

Endwerte siehe Begleitdokument 'S-PDU Kennungsfolgen'";
CM_ SG_ 1482 BMS_Ausgleichsladung_Anf "BMS wünscht eine Ausgleichsladung
Flag derzeit ungenutzt, da BalancingModus im Detail noch nicht geklärt.";
CM_ SG_ 1482 BMS_Balancing_Aktiv "Signal zeigt an, ob mindestens eine Zelle der HV Batterie balanciert wird";
CM_ SG_ 1482 BMS_Batteriediagnose "Anzeige von Textwarnungen";
CM_ SG_ 1482 BMS_Energieinhalt "aktuell nutzbarer Energieinhalt der HV-Batterie
(bezogen auf ein definiertes mittleres Belastungsprofil)";
CM_ SG_ 1482 BMS_Gesamtst_Spgfreiheit "0 = Funktion nicht aktiviert
1 = HV-System spannungsfrei (U_Zwkr von BMS, LE und Ladegerät < 20V, DCLadestecker nicht gesteckt und Service Disconnect entriegelt)
2 = HV-System nicht spannungsfrei (U_Zwkr von BMS, LE und Ladegerät >= 20V, Ladestecker ges";
CM_ SG_ 1482 BMS_KundenWarnung "Kundenwarnung und Ersatzreaktionen aufgrund von Batteriebrandgefahr";
CM_ SG_ 1482 BMS_Ladevorgang_aktiv "Signalisiert aktiven Ladevorgang, Ladegerät und DC/DC aktiv.
Signal bleibt nach Kl.15 ein aktiv, bis ESP_Stillstandsflag gelöscht.

Abhängigkeit zu BMS_Energieinhalt";
CM_ SG_ 1482 BMS_MaxEnergieinhalt "maximaler nutzbarer Energieinhalt der HV-Batterie (bezogen auf Last KBI_RWDS_Lastprofil bei SOC=100%)
Abhängig von KBI_RWDS_Lastprofil";
CM_ SG_ 1482 BMS_RIso_Ext "Minimum des Isolationswiderstands zwischen Batteriegehäuse und HV+ bzw. Batteriegehäuse und HV- bei geschlossenen Schützen (externe Iso Messung)";

CM_ SG_ 2589283664 BMS_Balancing_Aktiv "Signal zeigt an, ob mindestens eine Zelle der HV Batterie balanciert wird";
CM_ SG_ 2589283664 BMS_Ladevorgang_aktiv "Signalisiert aktiven Ladevorgang, Ladegerät und DC/DC aktiv.
Signal bleibt nach Kl.15 ein aktiv, bis ESP_Stillstandsflag gelöscht.

Abhängigkeit zu BMS_Energieinhalt";
CM_ SG_ 2589283664 BMS_Max_Energie "Nutzbarer maximaler Entlade-Energieinhalt der vollgeladenen Batterie. 

Projektabhängig kann der Energiewert vom variablen SOC-Fenster (zwischen oberer und unterer SOC-Grenze), dem Alterungszustand, dem aktuellen Lastprofil sowie der Temperatur abhängen";
CM_ SG_ 2589283664 BMS_Max_Ladezustand "Obere Ladezustandsgrenze für das SOC-Fenster in der Betriebsstrategie. 
Der Wert kann sich über Lebensdauer und Alterung des Batteriesystems ändern; 
Erreicht der Wert 'BMS_Ladezustand' den hier übertragenen Wert, darf die Batterie nicht weiter geladen ";
CM_ SG_ 2589283664 BMS_Min_Ladezustand "Untere Ladezustandsgrenze für das SOC-Fenster in der Betriebsstrategie. 
Der Wert kann sich über Lebensdauer und Alterung des Batteriesystems ändern; 
Erreicht der Wert 'BMS_Ladezustand' nach unten hin den hier übertragenen Wert, darf die Batterie nicht";
CM_ SG_ 2589283664 BMS_RIso_Ext "Minimum des Isolationswiderstands zwischen Batteriegehäuse und HV+ bzw. Batteriegehäuse und HV- bei geschlossenen Schützen (externe Iso Messung)";

CM_ SG_ 2589283665 BMS_BattHeizung_VerbautStatus "Verbausignalisierung der optionalen HV-Batterieheizung";
CM_ SG_ 2589283665 BMS_Fehler_NTKreis "Fehler im NTKreis, HV-Batterie wird nicht klimatisiert
(Fehler, Fehlerfrei) ";
CM_ SG_ 2589283665 BMS_Pumpe1_Ansteuerung "Ansteuerung der Batterie-Kühlmittelpumpe.
0% = Pumpe abgeschaltet
100% = Pumpe maximal angesteuert";
CM_ SG_ 2589283665 BMS_Pumpe2_Ansteuerung "Ansteuerung einer zweiten Kühlmittelpumpe.
Projektabhängig für Systeme, die seitens Batterie zwei Pumpen ansteuern.
0% = Pumpe abgeschaltet
100% = Pumpe maximal angesteuert";
CM_ SG_ 2589283665 BMS_RuecklaufTemperatur "Aktueller Messwert der Kühlmittel-Rücklauftemperatur
am Kühlmittel-Auslass des Batteriesystems.";
CM_ SG_ 2589283665 BMS_SollVorlauftemperatur "Soll_Vorlauftemperatur_Kühlmedium in °C";
CM_ SG_ 2589283665 BMS_Status_Ventil1 "Status Ventil; wassergekühltes Batteriesystem.
Batteriekreis-Absperrventil.

nicht-angesteuert = Batterie im kleinen Kühlkreislauf, abgetrennt vom restlichen Kühlsystem
angesteuert = Batterie eingeschleift in großen Kühlkreislauf (Niedertemperatur-Küh";
CM_ SG_ 2589283665 BMS_Status_Ventil2 "Status des zweiten Ventils; wassergekühltes Batteriesystem.
Für Systeme, wo die Batterie ein zweites Ventil ansteuert.
Belegung projektabhängig.

nicht-angesteuert = großer Kühlkreislauf (Niedertemperatur-Kühlkreis) abgetrennt vom Batteriesystem oder ";
CM_ SG_ 2589283665 BMS_Temperatur "battery temperature / Momentanwert: Temperatur der Traktionsbatterie";
CM_ SG_ 2589283665 BMS_Temperierung_Anf "Temperierungsbedarf der HV-Batterie";
CM_ SG_ 2589283665 BMS_VorlaufTemperatur "Aktueller Messwert der Kühlmittel-Vorlauftemperatur
am Kühlmittel-Einlass des Batteriesystems.";

CM_ SG_ 2331595856 BMS_DC_Ladeschuetze_Ist "Status der DC-Ladeschütze der HV-Batterie";
CM_ SG_ 2331595856 BMS_EnergieVorhalt "Energievorhalt der Batterie (z.B. als Alterungsreserve), welcher nicht in der aktuellen Betriebsstrategie verwendet werden kann, aber zur Kompensation der Alterung genutzt werden kann.";
CM_ SG_ 2331595856 BMS_Hauptschuetze_Ist "Status der Hauptschütze der HV-Batterie";
CM_ SG_ 2331595856 BMS_Last_Chg_adeq_SOCswing_Day "Zeitpunkt (Tag) des letzten, für die UBE_Indikator-Berechnung adäquaten  Ladehubs (aktuelle Forderung: >50% SOC)";
CM_ SG_ 2331595856 BMS_Last_Chg_adeq_SOCswing_Month "Zeitpunkt (Monat) des letzten, für die UBE_Indikator-Berechnung adäquaten  Ladehubs (aktuelle Forderung: >50% SOC)";
CM_ SG_ 2331595856 BMS_Last_Chg_adeq_SOCswing_Year "Zeitpunkt (Jahr) des letzten, für die UBE_Indikator-Berechnung adäquaten  Ladehubs (aktuelle Forderung: >50% SOC)";
CM_ SG_ 2331595856 BMS_Max_UBE "BMS_UBE bei BMS_Ladezustand = BMS_Max_Ladezustand. Das Verhältnis BMS_UBE/BMS_UBE_Max ergibt den energetischen Kunden-SOC (ohne Berücksichtigung eventueller Anzeigereserven)";
CM_ SG_ 2331595856 BMS_Nennspannung "Nennspannung der HV Batterie (Nennspannung der Zelle nach PV8450 multipliziert mal Anzahl in Serie geschalteter Zellen)";
CM_ SG_ 2331595856 BMS_Range_Indikator "Der Range-Indikator gibt das Verhältnis der aktuellen maximalen Reichweite zur maximalen Reichweite eines Neufahrzeugs wieder. Da die Reichweite primär von der UBE abhängt, wird dieser Wert im BMS berechnet.";
CM_ SG_ 2331595856 BMS_UBE "„Usable Battery Energy“ = Nutzbare Entladeenergie der HV Batterie vom aktuellen Ladezustand bis zum Ende des elektrischen Fahrens unter Annahme von Homologationsbedingungen (Lastprofil, Temperatur). Ein negativer Wert bedeutet, dass der aktuelle Ladezusta";
CM_ SG_ 2331595856 BMS_UBE_Indik_last_update_km "Strecke seit letzter Aktualisierung des UBE-Indikators. Ausgabe in der Einheit [km]";
CM_ SG_ 2331595856 BMS_UBE_Indikator "Der UBE Indikator gibt das Verhältnis der aktuellen maximalen UBE (BMS_Max_UBE) zur maximalen UBE einer neuen HV Batterie wieder.";
CM_ SG_ 2331595856 BMS_UBE_T "Gleiche Bedeutung wie das Signal BMS_UBE unter Berücksichtigung der aktuellen Batterietemperatur. Eine Temperaturänderung wird nicht angenommen.
Dieses Signal kann zum Beispiel verwendet werden, um eine Restenergie der HV Batterie zu berechnen.";
CM_ SG_ 2331595856 SOK_BMS_34_Signatur "Signatur im Rahmen der durch SOK geschützen Broadcast-Kommunikation

Geschützte Funktion: UBE-Indikator
Geschützte PDU: BMS_34";

CM_ SG_ 2589283523 BMS_48V_Indc_StChk "Übermittlung vom Diagnoseergebnis für das Inducement";
CM_ SG_ 2589283523 BMS_48V_Indc_StFail "Inducement Anforderung";
CM_ SG_ 2589283523 BMS_MV_Dauer_EntladeLeistung "ist die aktuelle Dauer-Leistungsfähigkeit der Batterie. 
Wenn dieser Wert überschritten wird, kann ein zeitliches Derating der maximalen Leistungsgrenzen stattfindet. Die Dauerleistung ändert sich mit Batterietemperatur und Ladezustand.";
CM_ SG_ 2589283523 BMS_MV_Dauer_EntladeSpannung "Erwartete Spannung, die sich bei Belastung der MV Batterie mit der Dauer-Entladeleistung einstellt.";
CM_ SG_ 2589283523 BMS_MV_Dauer_LadeLeistung "ist die aktuelle Dauer-Leistungsfähigkeit der Batterie. 
Wenn dieser Wert überschritten wird, kann ein zeitliches Derating der maximalen Leistungsgrenzen stattfindet. Die Dauerleistung ändert sich mit Batterietemperatur und Ladezustand.";
CM_ SG_ 2589283523 BMS_MV_Dauer_LadeSpannung "Erwartete Spannung, die sich bei Belastung der MV Batterie mit der Dauer-Ladeleistung einstellt.";
CM_ SG_ 2589283523 BMS_MV_Dauer_RMS_Strom "Dauerhaft maximal verfügbarer RMS-Strom ohne thermisches Derating.";
CM_ SG_ 2589283523 BMS_MV_Kundenwarnung "Kundenwarnung aufgrund eines Batteriefehlers.";
CM_ SG_ 2589283523 BMS_MV_OBD_Lampe_Anf "Anforderung MIL (MalfunctionIndicationLamp) von BMS (Motorsteuergerät reicht diese Info an Kombi weiter).";
CM_ SG_ 2589283523 OBDProtocol_BMS_48V "Bestätigung des aktuell umgesetzten Scan Tool Protokolls";

CM_ SG_ 2331596015 BSIS_Anzeigen_links "BSIS- Texte und -Akustik zur Anzeige und Tonausgabe im Kombiinstrument";
CM_ SG_ 2331596015 BSIS_LED_Ausgabemodus_links "Ansteuerung der SWA-LED Fahrtrichtung links für die Funktion BSIS (Priorisierung BSIS/SWA)";
CM_ SG_ 2331596015 BSIS_LED_Hell_links "Helligkeitswert SWA-LED Fahrtrichtung links für die Funktion BSIS (Priorisierung BSIS/SWA)";

CM_ SG_ 2331596016 BSIS_Anzeigen_rechts "BSIS- Texte und -Akustik zur Anzeige und Tonausgabe im Kombiinstrument";
CM_ SG_ 2331596016 BSIS_LED_Ausgabemodus_rechts "Ansteuerung der SWA-LED Fahrtrichtung rechts für die Funktion BSIS (Priorisierung BSIS/SWA)";
CM_ SG_ 2331596016 BSIS_LED_Hell_rechts "Helligkeitswert SWA-LED Fahrtrichtung rechts für die Funktion BSIS (Priorisierung BSIS/SWA)";

CM_ SG_ 902 CHA_Charge_LED "Ansteuerung der LED am Charge-Taster durch Charisma im PHEV";
CM_ SG_ 902 CHA_Charisma_Taste2_LED "Ansteuerung der 2. Charisma-Taste-LED";
CM_ SG_ 902 CHA_Current_Mode "Aktuell eingestelltes Charisma Fahrprogramm";
CM_ SG_ 902 CHA_Current_Mode_FPA "Aktuell eingestelltes Charisma Fahrprogramm";
CM_ SG_ 902 CHA_Eco_Charisma_LED "Ansteuerung der Funktions-LED der ECO alias Bluekey Taste bzw. Charisma-Taste.
Der Master der Fahrmodus-Funktion soll die Funktionsleuchte ansteuern, in der MQB Architektur ist der Master im Gateway untergebracht.";
CM_ SG_ 902 CHA_EV_LED "Ansteuerung der LED am EV-Taster durch Charisma im PHEV";
CM_ SG_ 902 CHA_Fahrer_Umschaltung "Die manuelle Umschaltung durch den Fahrer soll signalisiert werden, um zu automatischen Umschaltungen (z.B. Retries) differenzieren zu können.";
CM_ SG_ 902 CHA_Kombi_Texte "Anzeige des aktuellen Charisma-Fahrprofiles im Kombi.
Die Texte werden HUT-Spezifisch in einem Schnittstellen-LAH definiert.";
CM_ SG_ 902 CHA_Kombi_Texte_02 "Anzeige von Hinweistexten bzgl. Charismaumschaltungen im Kombi.
Die Texte werden HUT-Spezifisch in einem Schnittstellen-LAH definiert.";
CM_ SG_ 902 CHA_Offroad_LED "Ansteuerung der Offroad-LED";
CM_ SG_ 902 CHA_ReqPrgDispSetup "Requested Charisma-programm to Kombi to change display setup.";
CM_ SG_ 902 CHA_StCurProfDft "Signal indicates if the current Charisma-profile";
CM_ SG_ 902 CHA_Ziel_FahrPr_03_01 "reserviert für Anforderung Ziel-Fahrprogramm";
CM_ SG_ 902 CHA_Ziel_FahrPr_03_02 "reserviert für Anforderung Ziel-Fahrprogramm";
CM_ SG_ 902 CHA_Ziel_FahrPr_AMB "Anforderung Ziel-Fahrprogramm Ambientelichtmodul";
CM_ SG_ 902 CHA_Ziel_FahrPr_HSP "Anforderung Ziel-Fahrprogramm Heckspoiler";
CM_ SG_ 902 CHA_Ziel_FahrPr_IVB "Anforderung Ziel-Fahrprogramm IVB";
CM_ SG_ 902 CHA_Ziel_FahrPr_KL "Anforderung Ziel-Fahrprogramm Klima";
CM_ SG_ 902 CHA_Ziel_FahrPr_RWB "Anforderung Zielfahrprogramm Reichweitenberechnung (RWB)";
BA_DEF_REL_ BU_SG_REL_  "GenSigTimeoutTime" INT 0 65535;
BA_DEF_ BO_  "DiagRequest" ENUM "No", "Yes";
BA_DEF_ BO_  "DiagResponse" ENUM "No", "Yes";
BA_DEF_ BO_  "DiagState" ENUM "No", "Yes";
BA_DEF_ BO_  "GenMsgChkConstant" HEX 0 4095;
BA_DEF_ BO_  "GenMsgCycleTime" INT 0 65535;
BA_DEF_ BO_  "GenMsgCycleTimeFast" INT 0 65535;
BA_DEF_ BO_  "GenMsgDelayTime" INT 0 100000;
BA_DEF_ BO_  "GenMsgILSupport" ENUM "No", "Yes";
BA_DEF_ BO_  "GenMsgNrOfRepetition" INT 0 100;
BA_DEF_ BO_  "GenMsgPDUConstants" STRING;
BA_DEF_ BO_  "GenMsgSendType" ENUM "Cyclic", "not_used", "not_used", "not_used", "not_used", "not_used", "not_used", "IfActive", "NoMsgSendType";
BA_DEF_ BO_  "GenMsgStartDelayTime" INT 0 100000;
BA_DEF_ BO_  "NmMessage" ENUM "No", "Yes";
BA_DEF_ BO_  "NmhMessage" ENUM "No", "Yes";
BA_DEF_ BO_  "MsgType" ENUM "Application", "NM ", "NMH", "TP2.0", "ISO-TP ", "BAP", "EID", "KS", "XCP_PRE_CONFIGURED", "XCP_RUNTIME_CONFIGURED";
BA_DEF_ BO_  "VAGTP20_API" HEX 0 255;
BA_DEF_ BO_  "VAGTP20_DynConnection" ENUM "No", "Yes";
BA_DEF_ BO_  "VAGTP20_DynSetup" ENUM "No", "Yes";
BA_DEF_ BO_  "VAGTP20_StatConnection" ENUM "No", "Yes";
BA_DEF_ BO_  "CANFD_BRS" ENUM "0", "1";
BA_DEF_ BO_  "VFrameFormat" ENUM "StandardCAN", "ExtendedCAN", "reserved", "reserved", "reserved", "reserved", "reserved", "reserved", "reserved", "reserved", "reserved", "reserved", "reserved", "reserved", "StandardCAN_FD", "ExtendedCAN_FD";
BA_DEF_ SG_  "GenSigActiveRepetitions" INT -2147483648 2147483647;
BA_DEF_ SG_  "GenSigInactiveValue" INT -2147483648 2147483647;
BA_DEF_ SG_  "GenSigSendType" ENUM "Cyclic", "OnWrite", "OnWriteWithRepetition", "OnChange", "OnChangeWithRepetition", "IfActive", "IfActiveWithRepetition", "NoSigSendType", "OnChangeAndIfActive", "OnChangeAndIfActiveWithRepetition";
BA_DEF_ SG_  "GenSigStartValue" INT -2147483648 2147483647;
BA_DEF_ SG_  "NWM-WakeupAllowed" ENUM "No", "Yes";
BA_DEF_ SG_  "GenSigFuncType" ENUM "NoFunction", "MsgCounter", "CRC-8", "XOR", "XOR-2", "DatedBit", "SW-Kl15", "CHK", "Constant", "Protocol", "CRC-8-SAE_J1850", "CRC-32", "DataLength", "DataID", "MsgCounter16", "SOK-Signatur", "Cluster";
BA_DEF_ SG_  "GenSigSwitchedByIgnition" ENUM "No", "Yes";
BA_DEF_ SG_  "Fehlerwert" HEX 0 2147483647;
BA_DEF_ SG_  "GenSigMissingSourceValue" HEX 0 2147483647;
BA_DEF_DEF_REL_  "GenSigTimeoutTime" 0;
BA_DEF_DEF_  "DiagRequest" "No";
BA_DEF_DEF_  "DiagResponse" "No";
BA_DEF_DEF_  "DiagState" "No";
BA_DEF_DEF_  "GenMsgChkConstant" 0;
BA_DEF_DEF_  "GenMsgCycleTime" 0;
BA_DEF_DEF_  "GenMsgCycleTimeFast" 0;
BA_DEF_DEF_  "GenMsgDelayTime" 0;
BA_DEF_DEF_  "GenMsgILSupport" "No";
BA_DEF_DEF_  "GenMsgNrOfRepetition" 0;
BA_DEF_DEF_  "GenMsgPDUConstants" "";
BA_DEF_DEF_  "GenMsgSendType" "NoMsgSendType";
BA_DEF_DEF_  "GenMsgStartDelayTime" 0;
BA_DEF_DEF_  "NmMessage" "No";
BA_DEF_DEF_  "NmhMessage" "No";
BA_DEF_DEF_  "MsgType" "Application";
BA_DEF_DEF_  "VAGTP20_API" 0;
BA_DEF_DEF_  "VAGTP20_DynConnection" "No";
BA_DEF_DEF_  "VAGTP20_DynSetup" "No";
BA_DEF_DEF_  "VAGTP20_StatConnection" "No";
BA_DEF_DEF_  "CANFD_BRS" "1";
BA_DEF_DEF_  "VFrameFormat" "StandardCAN";
BA_DEF_DEF_  "GenSigActiveRepetitions" 0;
BA_DEF_DEF_  "GenSigInactiveValue" 0;
BA_DEF_DEF_  "GenSigSendType" "NoSigSendType";
BA_DEF_DEF_  "GenSigStartValue" 0;
BA_DEF_DEF_  "NWM-WakeupAllowed" "No";
BA_DEF_DEF_  "GenSigFuncType" "NoFunction";
BA_DEF_DEF_  "GenSigSwitchedByIgnition" "Yes";
BA_DEF_DEF_  "Fehlerwert" 0;
BA_DEF_DEF_  "GenSigMissingSourceValue" 0;
BA_ "GenMsgCycleTimeFast" BO_ 2536714496 50;
BA_ "GenMsgSendType" BO_ 2536714496 7;
BA_ "MsgType" BO_ 2536714496 5;
BA_ "VFrameFormat" BO_ 2536714496 15;
BA_ "GenMsgCycleTimeFast" BO_ 2536714497 30;
BA_ "GenMsgSendType" BO_ 2536714497 7;
BA_ "MsgType" BO_ 2536714497 5;
BA_ "VFrameFormat" BO_ 2536714497 15;
BA_ "GenMsgCycleTimeFast" BO_ 2536714498 50;
BA_ "GenMsgSendType" BO_ 2536714498 7;
BA_ "MsgType" BO_ 2536714498 5;
BA_ "VFrameFormat" BO_ 2536714498 15;
BA_ "GenMsgCycleTimeFast" BO_ 2536714499 30;
BA_ "GenMsgSendType" BO_ 2536714499 7;
BA_ "MsgType" BO_ 2536714499 5;
BA_ "VFrameFormat" BO_ 2536714499 15;
BA_ "GenMsgCycleTime" BO_ 2536714512 1000;
BA_ "GenMsgCycleTimeFast" BO_ 2536714512 30;
BA_ "GenMsgSendType" BO_ 2536714512 7;
BA_ "MsgType" BO_ 2536714512 5;
BA_ "VFrameFormat" BO_ 2536714512 15;
BA_ "GenMsgCycleTime" BO_ 2536714513 1000;
BA_ "GenMsgCycleTimeFast" BO_ 2536714513 10;
BA_ "GenMsgSendType" BO_ 2536714513 7;
BA_ "MsgType" BO_ 2536714513 5;
BA_ "VFrameFormat" BO_ 2536714513 15;
BA_ "GenMsgCycleTimeFast" BO_ 2536704256 80;
BA_ "GenMsgSendType" BO_ 2536704256 7;
BA_ "MsgType" BO_ 2536704256 5;
BA_ "VFrameFormat" BO_ 2536704256 15;
BA_ "GenMsgCycleTime" BO_ 2536704272 1000;
BA_ "GenMsgCycleTimeFast" BO_ 2536704272 50;
BA_ "GenMsgSendType" BO_ 2536704272 7;
BA_ "MsgType" BO_ 2536704272 5;
BA_ "VFrameFormat" BO_ 2536704272 15;
BA_ "GenMsgCycleTimeFast" BO_ 2536708865 80;
BA_ "GenMsgSendType" BO_ 2536708865 7;
BA_ "MsgType" BO_ 2536708865 5;
BA_ "VFrameFormat" BO_ 2536708865 15;
BA_ "GenMsgCycleTime" BO_ 2536708880 1000;
BA_ "GenMsgCycleTimeFast" BO_ 2536708880 50;
BA_ "GenMsgSendType" BO_ 2536708880 7;
BA_ "MsgType" BO_ 2536708880 5;
BA_ "VFrameFormat" BO_ 2536708880 15;
BA_ "GenMsgCycleTimeFast" BO_ 2536711426 80;
BA_ "GenMsgSendType" BO_ 2536711426 7;
BA_ "MsgType" BO_ 2536711426 5;
BA_ "VFrameFormat" BO_ 2536711426 15;
BA_ "GenMsgCycleTime" BO_ 2536711440 1000;
BA_ "GenMsgCycleTimeFast" BO_ 2536711440 50;
BA_ "GenMsgSendType" BO_ 2536711440 7;
BA_ "MsgType" BO_ 2536711440 5;
BA_ "VFrameFormat" BO_ 2536711440 15;
BA_ "GenMsgCycleTimeFast" BO_ 2536705792 80;
BA_ "GenMsgSendType" BO_ 2536705792 7;
BA_ "MsgType" BO_ 2536705792 5;
BA_ "VFrameFormat" BO_ 2536705792 15;
BA_ "GenMsgCycleTimeFast" BO_ 2536705793 80;
BA_ "GenMsgSendType" BO_ 2536705793 7;
BA_ "MsgType" BO_ 2536705793 5;
BA_ "VFrameFormat" BO_ 2536705793 15;
BA_ "GenMsgCycleTime" BO_ 2536705808 1000;
BA_ "GenMsgCycleTimeFast" BO_ 2536705808 50;
BA_ "GenMsgSendType" BO_ 2536705808 7;
BA_ "MsgType" BO_ 2536705808 5;
BA_ "VFrameFormat" BO_ 2536705808 15;
BA_ "GenMsgCycleTime" BO_ 2536705809 1000;
BA_ "GenMsgCycleTimeFast" BO_ 2536705809 50;
BA_ "GenMsgSendType" BO_ 2536705809 7;
BA_ "MsgType" BO_ 2536705809 5;
BA_ "VFrameFormat" BO_ 2536705809 15;
BA_ "GenMsgCycleTimeFast" BO_ 2536710912 80;
BA_ "GenMsgSendType" BO_ 2536710912 7;
BA_ "MsgType" BO_ 2536710912 5;
BA_ "VFrameFormat" BO_ 2536710912 15;
BA_ "GenMsgCycleTime" BO_ 2536710928 1000;
BA_ "GenMsgCycleTimeFast" BO_ 2536710928 50;
BA_ "GenMsgSendType" BO_ 2536710928 7;
BA_ "MsgType" BO_ 2536710928 5;
BA_ "VFrameFormat" BO_ 2536710928 15;
BA_ "GenMsgCycleTimeFast" BO_ 2536734976 80;
BA_ "GenMsgSendType" BO_ 2536734976 7;
BA_ "MsgType" BO_ 2536734976 5;
BA_ "VFrameFormat" BO_ 2536734976 15;
BA_ "GenMsgCycleTime" BO_ 2536734992 1000;
BA_ "GenMsgCycleTimeFast" BO_ 2536734992 50;
BA_ "GenMsgSendType" BO_ 2536734992 7;
BA_ "MsgType" BO_ 2536734992 5;
BA_ "VFrameFormat" BO_ 2536734992 15;
BA_ "MsgType" BO_ 2536767264 5;
BA_ "VFrameFormat" BO_ 2536767264 15;
BA_ "MsgType" BO_ 2536767280 5;
BA_ "VFrameFormat" BO_ 2536767280 15;
BA_ "GenMsgCycleTimeFast" BO_ 2536719616 80;
BA_ "GenMsgSendType" BO_ 2536719616 7;
BA_ "MsgType" BO_ 2536719616 5;
BA_ "VFrameFormat" BO_ 2536719616 15;
BA_ "GenMsgCycleTimeFast" BO_ 2536719617 80;
BA_ "GenMsgSendType" BO_ 2536719617 7;
BA_ "MsgType" BO_ 2536719617 5;
BA_ "VFrameFormat" BO_ 2536719617 15;
BA_ "GenMsgCycleTime" BO_ 2536719632 1000;
BA_ "GenMsgCycleTimeFast" BO_ 2536719632 50;
BA_ "GenMsgSendType" BO_ 2536719632 7;
BA_ "MsgType" BO_ 2536719632 5;
BA_ "VFrameFormat" BO_ 2536719632 15;
BA_ "GenMsgCycleTimeFast" BO_ 2536705281 80;
BA_ "GenMsgSendType" BO_ 2536705281 7;
BA_ "MsgType" BO_ 2536705281 5;
BA_ "VFrameFormat" BO_ 2536705281 15;
BA_ "GenMsgCycleTime" BO_ 2536705296 1000;
BA_ "GenMsgCycleTimeFast" BO_ 2536705296 20;
BA_ "GenMsgSendType" BO_ 2536705296 7;
BA_ "MsgType" BO_ 2536705296 5;
BA_ "VFrameFormat" BO_ 2536705296 15;
BA_ "GenMsgCycleTimeFast" BO_ 2536717313 80;
BA_ "GenMsgSendType" BO_ 2536717313 7;
BA_ "MsgType" BO_ 2536717313 5;
BA_ "VFrameFormat" BO_ 2536717313 15;
BA_ "GenMsgCycleTimeFast" BO_ 2536717314 80;
BA_ "GenMsgSendType" BO_ 2536717314 7;
BA_ "MsgType" BO_ 2536717314 5;
BA_ "VFrameFormat" BO_ 2536717314 15;
BA_ "GenMsgCycleTime" BO_ 2536717328 1000;
BA_ "GenMsgCycleTimeFast" BO_ 2536717328 50;
BA_ "GenMsgSendType" BO_ 2536717328 7;
BA_ "MsgType" BO_ 2536717328 5;
BA_ "VFrameFormat" BO_ 2536717328 15;
BA_ "GenMsgCycleTimeFast" BO_ 2536706816 80;
BA_ "GenMsgSendType" BO_ 2536706816 7;
BA_ "MsgType" BO_ 2536706816 5;
BA_ "VFrameFormat" BO_ 2536706816 15;
BA_ "GenMsgCycleTimeFast" BO_ 2536706819 80;
BA_ "GenMsgSendType" BO_ 2536706819 7;
BA_ "MsgType" BO_ 2536706819 5;
BA_ "VFrameFormat" BO_ 2536706819 15;
BA_ "GenMsgCycleTime" BO_ 2536706832 1000;
BA_ "GenMsgCycleTimeFast" BO_ 2536706832 50;
BA_ "GenMsgSendType" BO_ 2536706832 7;
BA_ "MsgType" BO_ 2536706832 5;
BA_ "VFrameFormat" BO_ 2536706832 15;
BA_ "GenMsgCycleTimeFast" BO_ 2536702976 80;
BA_ "GenMsgSendType" BO_ 2536702976 7;
BA_ "MsgType" BO_ 2536702976 5;
BA_ "VFrameFormat" BO_ 2536702976 15;
BA_ "GenMsgCycleTimeFast" BO_ 2536702977 80;
BA_ "GenMsgSendType" BO_ 2536702977 7;
BA_ "MsgType" BO_ 2536702977 5;
BA_ "VFrameFormat" BO_ 2536702977 15;
BA_ "GenMsgCycleTimeFast" BO_ 2536702978 80;
BA_ "GenMsgSendType" BO_ 2536702978 7;
BA_ "MsgType" BO_ 2536702978 5;
BA_ "VFrameFormat" BO_ 2536702978 15;
BA_ "GenMsgCycleTime" BO_ 2536702992 1000;
BA_ "GenMsgCycleTimeFast" BO_ 2536702992 50;
BA_ "GenMsgSendType" BO_ 2536702992 7;
BA_ "MsgType" BO_ 2536702992 5;
BA_ "VFrameFormat" BO_ 2536702992 15;
BA_ "GenMsgCycleTimeFast" BO_ 2536709121 80;
BA_ "GenMsgSendType" BO_ 2536709121 7;
BA_ "MsgType" BO_ 2536709121 5;
BA_ "VFrameFormat" BO_ 2536709121 15;
BA_ "GenMsgCycleTime" BO_ 2536709136 1000;
BA_ "GenMsgCycleTimeFast" BO_ 2536709136 50;
BA_ "GenMsgSendType" BO_ 2536709136 7;
BA_ "MsgType" BO_ 2536709136 5;
BA_ "VFrameFormat" BO_ 2536709136 15;
BA_ "GenMsgCycleTimeFast" BO_ 2536722945 80;
BA_ "GenMsgSendType" BO_ 2536722945 7;
BA_ "MsgType" BO_ 2536722945 5;
BA_ "VFrameFormat" BO_ 2536722945 15;
BA_ "GenMsgCycleTime" BO_ 2536722960 1000;
BA_ "GenMsgCycleTimeFast" BO_ 2536722960 50;
BA_ "GenMsgSendType" BO_ 2536722960 7;
BA_ "MsgType" BO_ 2536722960 5;
BA_ "VFrameFormat" BO_ 2536722960 15;
BA_ "DiagState" BO_ 2536704000 1;
BA_ "GenMsgCycleTimeFast" BO_ 2536704000 80;
BA_ "GenMsgSendType" BO_ 2536704000 7;
BA_ "MsgType" BO_ 2536704000 5;
BA_ "VFrameFormat" BO_ 2536704000 15;
BA_ "GenMsgCycleTimeFast" BO_ 2536704003 80;
BA_ "GenMsgSendType" BO_ 2536704003 7;
BA_ "MsgType" BO_ 2536704003 5;
BA_ "VFrameFormat" BO_ 2536704003 15;
BA_ "GenMsgCycleTime" BO_ 2536704016 1000;
BA_ "GenMsgCycleTimeFast" BO_ 2536704016 50;
BA_ "GenMsgSendType" BO_ 2536704016 7;
BA_ "MsgType" BO_ 2536704016 5;
BA_ "VFrameFormat" BO_ 2536704016 15;
BA_ "GenMsgCycleTimeFast" BO_ 2536708353 80;
BA_ "GenMsgSendType" BO_ 2536708353 7;
BA_ "MsgType" BO_ 2536708353 5;
BA_ "VFrameFormat" BO_ 2536708353 15;
BA_ "GenMsgCycleTime" BO_ 2536708368 1000;
BA_ "GenMsgCycleTimeFast" BO_ 2536708368 50;
BA_ "GenMsgSendType" BO_ 2536708368 7;
BA_ "MsgType" BO_ 2536708368 5;
BA_ "VFrameFormat" BO_ 2536708368 15;
BA_ "GenMsgCycleTimeFast" BO_ 2536715264 80;
BA_ "GenMsgSendType" BO_ 2536715264 7;
BA_ "MsgType" BO_ 2536715264 5;
BA_ "VFrameFormat" BO_ 2536715264 15;
BA_ "GenMsgCycleTime" BO_ 2536715280 1000;
BA_ "GenMsgCycleTimeFast" BO_ 2536715280 50;
BA_ "GenMsgSendType" BO_ 2536715280 7;
BA_ "MsgType" BO_ 2536715280 5;
BA_ "VFrameFormat" BO_ 2536715280 15;
BA_ "GenMsgCycleTimeFast" BO_ 2536714752 30;
BA_ "GenMsgSendType" BO_ 2536714752 7;
BA_ "MsgType" BO_ 2536714752 5;
BA_ "VFrameFormat" BO_ 2536714752 15;
BA_ "GenMsgCycleTimeFast" BO_ 2536714753 50;
BA_ "GenMsgSendType" BO_ 2536714753 7;
BA_ "MsgType" BO_ 2536714753 5;
BA_ "VFrameFormat" BO_ 2536714753 15;
BA_ "GenMsgCycleTimeFast" BO_ 2536714754 30;
BA_ "GenMsgSendType" BO_ 2536714754 7;
BA_ "MsgType" BO_ 2536714754 5;
BA_ "VFrameFormat" BO_ 2536714754 15;
BA_ "GenMsgCycleTimeFast" BO_ 2536714755 50;
BA_ "GenMsgSendType" BO_ 2536714755 7;
BA_ "MsgType" BO_ 2536714755 5;
BA_ "VFrameFormat" BO_ 2536714755 15;
BA_ "GenMsgCycleTime" BO_ 2536714768 1000;
BA_ "GenMsgCycleTimeFast" BO_ 2536714768 30;
BA_ "GenMsgSendType" BO_ 2536714768 7;
BA_ "MsgType" BO_ 2536714768 5;
BA_ "VFrameFormat" BO_ 2536714768 15;
BA_ "GenMsgCycleTime" BO_ 2536714769 1000;
BA_ "GenMsgCycleTimeFast" BO_ 2536714769 10;
BA_ "GenMsgSendType" BO_ 2536714769 7;
BA_ "MsgType" BO_ 2536714769 5;
BA_ "VFrameFormat" BO_ 2536714769 15;
BA_ "GenMsgCycleTimeFast" BO_ 2536712704 80;
BA_ "GenMsgSendType" BO_ 2536712704 7;
BA_ "MsgType" BO_ 2536712704 5;
BA_ "VFrameFormat" BO_ 2536712704 15;
BA_ "GenMsgCycleTimeFast" BO_ 2536712705 80;
BA_ "GenMsgSendType" BO_ 2536712705 7;
BA_ "MsgType" BO_ 2536712705 5;
BA_ "VFrameFormat" BO_ 2536712705 15;
BA_ "GenMsgCycleTime" BO_ 2536712720 1000;
BA_ "GenMsgCycleTimeFast" BO_ 2536712720 50;
BA_ "GenMsgSendType" BO_ 2536712720 7;
BA_ "MsgType" BO_ 2536712720 5;
BA_ "VFrameFormat" BO_ 2536712720 15;
BA_ "GenMsgCycleTimeFast" BO_ 2536704512 80;
BA_ "GenMsgSendType" BO_ 2536704512 7;
BA_ "MsgType" BO_ 2536704512 5;
BA_ "VFrameFormat" BO_ 2536704512 15;
BA_ "GenMsgCycleTimeFast" BO_ 2536704518 80;
BA_ "GenMsgSendType" BO_ 2536704518 7;
BA_ "MsgType" BO_ 2536704518 5;
BA_ "VFrameFormat" BO_ 2536704518 15;
BA_ "GenMsgCycleTime" BO_ 2536704528 1000;
BA_ "GenMsgCycleTimeFast" BO_ 2536704528 50;
BA_ "GenMsgSendType" BO_ 2536704528 7;
BA_ "MsgType" BO_ 2536704528 5;
BA_ "VFrameFormat" BO_ 2536704528 15;
BA_ "GenMsgCycleTime" BO_ 2536704529 1000;
BA_ "GenMsgCycleTimeFast" BO_ 2536704529 50;
BA_ "GenMsgSendType" BO_ 2536704529 7;
BA_ "MsgType" BO_ 2536704529 5;
BA_ "VFrameFormat" BO_ 2536704529 15;
BA_ "GenMsgCycleTimeFast" BO_ 2536723713 20;
BA_ "GenMsgSendType" BO_ 2536723713 7;
BA_ "MsgType" BO_ 2536723713 5;
BA_ "VFrameFormat" BO_ 2536723713 15;
BA_ "GenMsgCycleTimeFast" BO_ 2536723716 50;
BA_ "GenMsgSendType" BO_ 2536723716 7;
BA_ "MsgType" BO_ 2536723716 5;
BA_ "VFrameFormat" BO_ 2536723716 15;
BA_ "GenMsgCycleTime" BO_ 2536723728 1000;
BA_ "GenMsgCycleTimeFast" BO_ 2536723728 20;
BA_ "GenMsgSendType" BO_ 2536723728 7;
BA_ "MsgType" BO_ 2536723728 5;
BA_ "VFrameFormat" BO_ 2536723728 15;
BA_ "GenMsgCycleTimeFast" BO_ 2536731136 80;
BA_ "GenMsgSendType" BO_ 2536731136 7;
BA_ "MsgType" BO_ 2536731136 5;
BA_ "VFrameFormat" BO_ 2536731136 15;
BA_ "GenMsgCycleTimeFast" BO_ 2536731137 80;
BA_ "GenMsgSendType" BO_ 2536731137 7;
BA_ "MsgType" BO_ 2536731137 5;
BA_ "VFrameFormat" BO_ 2536731137 15;
BA_ "GenMsgCycleTime" BO_ 2536731152 1000;
BA_ "GenMsgCycleTimeFast" BO_ 2536731152 20;
BA_ "GenMsgSendType" BO_ 2536731152 7;
BA_ "MsgType" BO_ 2536731152 5;
BA_ "VFrameFormat" BO_ 2536731152 15;
BA_ "GenMsgCycleTime" BO_ 2536731153 1000;
BA_ "GenMsgCycleTimeFast" BO_ 2536731153 50;
BA_ "GenMsgSendType" BO_ 2536731153 7;
BA_ "MsgType" BO_ 2536731153 5;
BA_ "VFrameFormat" BO_ 2536731153 15;
BA_ "GenMsgCycleTimeFast" BO_ 2536703745 80;
BA_ "GenMsgSendType" BO_ 2536703745 7;
BA_ "MsgType" BO_ 2536703745 5;
BA_ "VFrameFormat" BO_ 2536703745 15;
BA_ "GenMsgCycleTime" BO_ 2536703760 1000;
BA_ "GenMsgCycleTimeFast" BO_ 2536703760 50;
BA_ "GenMsgSendType" BO_ 2536703760 7;
BA_ "MsgType" BO_ 2536703760 5;
BA_ "VFrameFormat" BO_ 2536703760 15;
BA_ "GenMsgCycleTimeFast" BO_ 2536719872 80;
BA_ "GenMsgSendType" BO_ 2536719872 7;
BA_ "MsgType" BO_ 2536719872 5;
BA_ "VFrameFormat" BO_ 2536719872 15;
BA_ "GenMsgCycleTime" BO_ 2536719888 1000;
BA_ "GenMsgCycleTimeFast" BO_ 2536719888 50;
BA_ "GenMsgSendType" BO_ 2536719888 7;
BA_ "MsgType" BO_ 2536719888 5;
BA_ "VFrameFormat" BO_ 2536719888 15;
BA_ "GenMsgCycleTimeFast" BO_ 2536706560 80;
BA_ "GenMsgSendType" BO_ 2536706560 7;
BA_ "MsgType" BO_ 2536706560 5;
BA_ "VFrameFormat" BO_ 2536706560 15;
BA_ "GenMsgCycleTimeFast" BO_ 2536706561 80;
BA_ "GenMsgSendType" BO_ 2536706561 7;
BA_ "MsgType" BO_ 2536706561 5;
BA_ "VFrameFormat" BO_ 2536706561 15;
BA_ "GenMsgCycleTime" BO_ 2536706576 1000;
BA_ "GenMsgCycleTimeFast" BO_ 2536706576 50;
BA_ "GenMsgSendType" BO_ 2536706576 7;
BA_ "MsgType" BO_ 2536706576 5;
BA_ "VFrameFormat" BO_ 2536706576 15;
BA_ "GenMsgCycleTimeFast" BO_ 2536736001 80;
BA_ "GenMsgSendType" BO_ 2536736001 7;
BA_ "MsgType" BO_ 2536736001 5;
BA_ "VFrameFormat" BO_ 2536736001 15;
BA_ "GenMsgCycleTime" BO_ 2536736016 1000;
BA_ "GenMsgCycleTimeFast" BO_ 2536736016 50;
BA_ "GenMsgSendType" BO_ 2536736016 7;
BA_ "MsgType" BO_ 2536736016 5;
BA_ "VFrameFormat" BO_ 2536736016 15;
BA_ "GenMsgCycleTimeFast" BO_ 2536711937 80;
BA_ "GenMsgSendType" BO_ 2536711937 7;
BA_ "MsgType" BO_ 2536711937 5;
BA_ "VFrameFormat" BO_ 2536711937 15;
BA_ "GenMsgCycleTime" BO_ 2536711952 1000;
BA_ "GenMsgCycleTimeFast" BO_ 2536711952 50;
BA_ "GenMsgSendType" BO_ 2536711952 7;
BA_ "MsgType" BO_ 2536711952 5;
BA_ "VFrameFormat" BO_ 2536711952 15;
BA_ "GenMsgCycleTimeFast" BO_ 2536720896 80;
BA_ "GenMsgSendType" BO_ 2536720896 7;
BA_ "MsgType" BO_ 2536720896 5;
BA_ "VFrameFormat" BO_ 2536720896 15;
BA_ "GenMsgCycleTime" BO_ 2536720912 1000;
BA_ "GenMsgCycleTimeFast" BO_ 2536720912 50;
BA_ "GenMsgSendType" BO_ 2536720912 7;
BA_ "MsgType" BO_ 2536720912 5;
BA_ "VFrameFormat" BO_ 2536720912 15;
BA_ "GenMsgCycleTimeFast" BO_ 2536708609 80;
BA_ "GenMsgSendType" BO_ 2536708609 7;
BA_ "MsgType" BO_ 2536708609 5;
BA_ "VFrameFormat" BO_ 2536708609 15;
BA_ "GenMsgCycleTime" BO_ 2536708624 1000;
BA_ "GenMsgCycleTimeFast" BO_ 2536708624 50;
BA_ "GenMsgSendType" BO_ 2536708624 7;
BA_ "MsgType" BO_ 2536708624 5;
BA_ "VFrameFormat" BO_ 2536708624 15;
BA_ "GenMsgCycleTimeFast" BO_ 2536712448 80;
BA_ "GenMsgSendType" BO_ 2536712448 7;
BA_ "MsgType" BO_ 2536712448 5;
BA_ "VFrameFormat" BO_ 2536712448 15;
BA_ "GenMsgCycleTimeFast" BO_ 2536712449 80;
BA_ "GenMsgSendType" BO_ 2536712449 7;
BA_ "MsgType" BO_ 2536712449 5;
BA_ "VFrameFormat" BO_ 2536712449 15;
BA_ "GenMsgCycleTime" BO_ 2536712464 1000;
BA_ "GenMsgCycleTimeFast" BO_ 2536712464 50;
BA_ "GenMsgSendType" BO_ 2536712464 7;
BA_ "MsgType" BO_ 2536712464 5;
BA_ "VFrameFormat" BO_ 2536712464 15;
BA_ "GenMsgCycleTime" BO_ 2536712465 1000;
BA_ "GenMsgCycleTimeFast" BO_ 2536712465 50;
BA_ "GenMsgSendType" BO_ 2536712465 7;
BA_ "MsgType" BO_ 2536712465 5;
BA_ "VFrameFormat" BO_ 2536712465 15;
BA_ "GenMsgCycleTimeFast" BO_ 2536712192 30;
BA_ "GenMsgSendType" BO_ 2536712192 7;
BA_ "MsgType" BO_ 2536712192 5;
BA_ "VFrameFormat" BO_ 2536712192 15;
BA_ "GenMsgCycleTimeFast" BO_ 2536712193 50;
BA_ "GenMsgSendType" BO_ 2536712193 7;
BA_ "MsgType" BO_ 2536712193 5;
BA_ "VFrameFormat" BO_ 2536712193 15;
BA_ "GenMsgCycleTimeFast" BO_ 2536712194 30;
BA_ "GenMsgSendType" BO_ 2536712194 7;
BA_ "MsgType" BO_ 2536712194 5;
BA_ "VFrameFormat" BO_ 2536712194 15;
BA_ "GenMsgCycleTimeFast" BO_ 2536712195 50;
BA_ "GenMsgSendType" BO_ 2536712195 7;
BA_ "MsgType" BO_ 2536712195 5;
BA_ "VFrameFormat" BO_ 2536712195 15;
BA_ "GenMsgCycleTime" BO_ 2536712208 1000;
BA_ "GenMsgCycleTimeFast" BO_ 2536712208 30;
BA_ "GenMsgSendType" BO_ 2536712208 7;
BA_ "MsgType" BO_ 2536712208 5;
BA_ "VFrameFormat" BO_ 2536712208 15;
BA_ "GenMsgCycleTime" BO_ 2536712209 1000;
BA_ "GenMsgCycleTimeFast" BO_ 2536712209 10;
BA_ "GenMsgSendType" BO_ 2536712209 7;
BA_ "MsgType" BO_ 2536712209 5;
BA_ "VFrameFormat" BO_ 2536712209 15;
BA_ "GenMsgCycleTimeFast" BO_ 2536706304 80;
BA_ "GenMsgSendType" BO_ 2536706304 7;
BA_ "MsgType" BO_ 2536706304 5;
BA_ "VFrameFormat" BO_ 2536706304 15;
BA_ "GenMsgCycleTimeFast" BO_ 2536706305 80;
BA_ "GenMsgSendType" BO_ 2536706305 7;
BA_ "MsgType" BO_ 2536706305 5;
BA_ "VFrameFormat" BO_ 2536706305 15;
BA_ "GenMsgCycleTimeFast" BO_ 2536706308 80;
BA_ "GenMsgSendType" BO_ 2536706308 7;
BA_ "MsgType" BO_ 2536706308 5;
BA_ "VFrameFormat" BO_ 2536706308 15;
BA_ "GenMsgCycleTime" BO_ 2536706320 1000;
BA_ "GenMsgCycleTimeFast" BO_ 2536706320 50;
BA_ "GenMsgSendType" BO_ 2536706320 7;
BA_ "MsgType" BO_ 2536706320 5;
BA_ "VFrameFormat" BO_ 2536706320 15;
BA_ "GenMsgCycleTimeFast" BO_ 2536710401 80;
BA_ "GenMsgSendType" BO_ 2536710401 7;
BA_ "MsgType" BO_ 2536710401 5;
BA_ "VFrameFormat" BO_ 2536710401 15;
BA_ "GenMsgCycleTimeFast" BO_ 2536710402 80;
BA_ "GenMsgSendType" BO_ 2536710402 7;
BA_ "MsgType" BO_ 2536710402 5;
BA_ "VFrameFormat" BO_ 2536710402 15;
BA_ "GenMsgCycleTime" BO_ 2536710416 1000;
BA_ "GenMsgCycleTimeFast" BO_ 2536710416 50;
BA_ "GenMsgSendType" BO_ 2536710416 7;
BA_ "MsgType" BO_ 2536710416 5;
BA_ "VFrameFormat" BO_ 2536710416 15;
BA_ "MsgType" BO_ 2583694872 4;
BA_ "VFrameFormat" BO_ 2583694872 15;
BA_ "MsgType" BO_ 2583825944 4;
BA_ "VFrameFormat" BO_ 2583825944 15;
BA_ "GenMsgCycleTime" BO_ 1626 1000;
BA_ "GenMsgCycleTimeFast" BO_ 1626 100;
BA_ "GenMsgDelayTime" BO_ 1626 30;
BA_ "GenMsgILSupport" BO_ 1626 1;
BA_ "GenMsgNrOfRepetition" BO_ 1626 5;
BA_ "GenMsgSendType" BO_ 1626 0;
BA_ "VFrameFormat" BO_ 1626 14;
BA_ "GenMsgCycleTime" BO_ 2527679637 1000;
BA_ "GenMsgCycleTimeFast" BO_ 2527679637 100;
BA_ "GenMsgDelayTime" BO_ 2527679637 50;
BA_ "GenMsgILSupport" BO_ 2527679637 1;
BA_ "GenMsgNrOfRepetition" BO_ 2527679637 5;
BA_ "GenMsgSendType" BO_ 2527679637 0;
BA_ "VFrameFormat" BO_ 2527679637 15;
BA_ "GenMsgCycleTime" BO_ 2463978607 200;
BA_ "GenMsgDelayTime" BO_ 2463978607 20;
BA_ "GenMsgILSupport" BO_ 2463978607 1;
BA_ "GenMsgSendType" BO_ 2463978607 0;
BA_ "VFrameFormat" BO_ 2463978607 15;
BA_ "GenMsgCycleTime" BO_ 2463978609 200;
BA_ "GenMsgDelayTime" BO_ 2463978609 20;
BA_ "GenMsgILSupport" BO_ 2463978609 1;
BA_ "GenMsgSendType" BO_ 2463978609 0;
BA_ "VFrameFormat" BO_ 2463978609 15;
BA_ "GenMsgCycleTime" BO_ 2463978887 100;
BA_ "GenMsgILSupport" BO_ 2463978887 1;
BA_ "GenMsgSendType" BO_ 2463978887 0;
BA_ "VFrameFormat" BO_ 2463978887 15;
BA_ "GenMsgCycleTime" BO_ 2463978882 1000;
BA_ "GenMsgCycleTimeFast" BO_ 2463978882 30;
BA_ "GenMsgDelayTime" BO_ 2463978882 30;
BA_ "GenMsgILSupport" BO_ 2463978882 1;
BA_ "GenMsgNrOfRepetition" BO_ 2463978882 5;
BA_ "GenMsgPDUConstants" BO_ 2463978882 "0x12,0x06,0x44,0x35,0x6a,0x54,0x88,0xaa,0x80,0xe0,0xbc,0x53,0x70,0x45,0x71,0x0e";
BA_ "GenMsgSendType" BO_ 2463978882 0;
BA_ "VFrameFormat" BO_ 2463978882 15;
BA_ "GenMsgCycleTime" BO_ 2463978881 1000;
BA_ "GenMsgCycleTimeFast" BO_ 2463978881 30;
BA_ "GenMsgDelayTime" BO_ 2463978881 30;
BA_ "GenMsgILSupport" BO_ 2463978881 1;
BA_ "GenMsgNrOfRepetition" BO_ 2463978881 5;
BA_ "GenMsgPDUConstants" BO_ 2463978881 "0xfb,0xbc,0xed,0x2c,0xda,0x67,0xd6,0xd8,0xe1,0x85,0x96,0x69,0x4e,0xea,0x63,0x31";
BA_ "GenMsgSendType" BO_ 2463978881 0;
BA_ "VFrameFormat" BO_ 2463978881 15;
BA_ "GenMsgCycleTime" BO_ 1635 100;
BA_ "GenMsgILSupport" BO_ 1635 1;
BA_ "GenMsgSendType" BO_ 1635 0;
BA_ "VFrameFormat" BO_ 1635 14;
BA_ "GenMsgCycleTime" BO_ 1163 100;
BA_ "GenMsgILSupport" BO_ 1163 1;
BA_ "GenMsgPDUConstants" BO_ 1163 "0x54,0xaf,0x8a,0xfb,0x0d,0x87,0x6a,0x0f,0x47,0x78,0x31,0x4f,0x35,0x28,0x82,0x6d";
BA_ "GenMsgSendType" BO_ 1163 0;
BA_ "VFrameFormat" BO_ 1163 14;
BA_ "GenMsgCycleTime" BO_ 2463978850 100;
BA_ "GenMsgILSupport" BO_ 2463978850 1;
BA_ "GenMsgPDUConstants" BO_ 2463978850 "0xaa,0xa9,0xe6,0xc5,0xc4,0x2b,0x0b,0x8e,0xfb,0x15,0xa4,0x64,0x1e,0x20,0x50,0x95";
BA_ "GenMsgSendType" BO_ 2463978850 0;
BA_ "VFrameFormat" BO_ 2463978850 15;
BA_ "GenMsgCycleTime" BO_ 870 1000;
BA_ "GenMsgCycleTimeFast" BO_ 870 50;
BA_ "GenMsgDelayTime" BO_ 870 10;
BA_ "GenMsgILSupport" BO_ 870 1;
BA_ "GenMsgNrOfRepetition" BO_ 870 5;
BA_ "GenMsgPDUConstants" BO_ 870 "0xa9,0xbd,0xfb,0x3c,0x95,0x0f,0x75,0x3a,0x4f,0x19,0x59,0x6d,0xb2,0xe9,0xd1,0x97";
BA_ "GenMsgSendType" BO_ 870 0;
BA_ "VFrameFormat" BO_ 870 14;
BA_ "GenMsgCycleTime" BO_ 687 50;
BA_ "GenMsgILSupport" BO_ 687 1;
BA_ "GenMsgSendType" BO_ 687 0;
BA_ "VFrameFormat" BO_ 687 14;
BA_ "GenMsgChkConstant" BO_ 1482 67;
BA_ "GenMsgCycleTime" BO_ 1482 500;
BA_ "GenMsgDelayTime" BO_ 1482 50;
BA_ "GenMsgILSupport" BO_ 1482 1;
BA_ "GenMsgPDUConstants" BO_ 1482 "0x43,0x43,0x43,0x43,0x43,0x43,0x43,0x43,0x43,0x43,0x43,0x43,0x43,0x43,0x43,0x43";
BA_ "GenMsgSendType" BO_ 1482 0;
BA_ "VFrameFormat" BO_ 1482 14;
BA_ "GenMsgCycleTime" BO_ 2589283664 500;
BA_ "GenMsgILSupport" BO_ 2589283664 1;
BA_ "GenMsgSendType" BO_ 2589283664 0;
BA_ "VFrameFormat" BO_ 2589283664 15;
BA_ "GenMsgCycleTime" BO_ 2589283665 500;
BA_ "GenMsgILSupport" BO_ 2589283665 1;
BA_ "GenMsgSendType" BO_ 2589283665 0;
BA_ "VFrameFormat" BO_ 2589283665 15;
BA_ "GenMsgCycleTime" BO_ 2331595856 100;
BA_ "GenMsgDelayTime" BO_ 2331595856 10;
BA_ "GenMsgILSupport" BO_ 2331595856 1;
BA_ "GenMsgSendType" BO_ 2331595856 0;
BA_ "VFrameFormat" BO_ 2331595856 15;
BA_ "GenMsgCycleTime" BO_ 2589283523 500;
BA_ "GenMsgDelayTime" BO_ 2589283523 50;
BA_ "GenMsgILSupport" BO_ 2589283523 1;
BA_ "GenMsgSendType" BO_ 2589283523 0;
BA_ "VFrameFormat" BO_ 2589283523 15;
BA_ "GenMsgCycleTime" BO_ 2331596015 500;
BA_ "GenMsgCycleTimeFast" BO_ 2331596015 50;
BA_ "GenMsgDelayTime" BO_ 2331596015 50;
BA_ "GenMsgILSupport" BO_ 2331596015 1;
BA_ "GenMsgNrOfRepetition" BO_ 2331596015 5;
BA_ "GenMsgSendType" BO_ 2331596015 0;
BA_ "VFrameFormat" BO_ 2331596015 15;
BA_ "GenMsgCycleTime" BO_ 2331596016 500;
BA_ "GenMsgCycleTimeFast" BO_ 2331596016 50;
BA_ "GenMsgDelayTime" BO_ 2331596016 50;
BA_ "GenMsgILSupport" BO_ 2331596016 1;
BA_ "GenMsgNrOfRepetition" BO_ 2331596016 5;
BA_ "GenMsgSendType" BO_ 2331596016 0;
BA_ "VFrameFormat" BO_ 2331596016 15;
BA_ "GenMsgCycleTime" BO_ 902 1000;
BA_ "GenMsgDelayTime" BO_ 902 50;
BA_ "GenMsgILSupport" BO_ 902 1;
BA_ "GenMsgSendType" BO_ 902 0;
BA_ "VFrameFormat" BO_ 902 14;
BA_ "GenSigSendType" SG_ 2536714496 BAP_Audio_ASG_01_Header 3;
BA_ "GenSigSwitchedByIgnition" SG_ 2536714496 BAP_Audio_ASG_01_Header 0;
BA_ "GenSigSendType" SG_ 2536714497 BAP_Audio_ASG_02_Header 3;
BA_ "GenSigSwitchedByIgnition" SG_ 2536714497 BAP_Audio_ASG_02_Header 0;
BA_ "GenSigSendType" SG_ 2536714498 BAP_Audio_ASG_03_Header 3;
BA_ "GenSigSwitchedByIgnition" SG_ 2536714498 BAP_Audio_ASG_03_Header 0;
BA_ "GenSigSendType" SG_ 2536714499 BAP_Audio_ASG_04_Header 3;
BA_ "GenSigSwitchedByIgnition" SG_ 2536714499 BAP_Audio_ASG_04_Header 0;
BA_ "GenSigSendType" SG_ 2536714512 BAP_Audio_FSG_01_Header 3;
BA_ "GenSigSwitchedByIgnition" SG_ 2536714512 BAP_Audio_FSG_01_Header 0;
BA_ "GenSigSendType" SG_ 2536714513 BAP_Audio_FSG_02_Header 3;
BA_ "GenSigSwitchedByIgnition" SG_ 2536714513 BAP_Audio_FSG_02_Header 0;
BA_ "GenSigSendType" SG_ 2536704256 BAP_Aussenlicht_ASG_01_Header 3;
BA_ "GenSigSwitchedByIgnition" SG_ 2536704256 BAP_Aussenlicht_ASG_01_Header 0;
BA_ "GenSigSendType" SG_ 2536704272 BAP_Aussenlicht_FSG_01_Header 3;
BA_ "GenSigSwitchedByIgnition" SG_ 2536704272 BAP_Aussenlicht_FSG_01_Header 0;
BA_ "GenSigSendType" SG_ 2536708865 BAP_AWV_ASG_02_Header 3;
BA_ "GenSigSwitchedByIgnition" SG_ 2536708865 BAP_AWV_ASG_02_Header 0;
BA_ "GenSigSendType" SG_ 2536708880 BAP_AWV_FSG_01_Header 3;
BA_ "GenSigSwitchedByIgnition" SG_ 2536708880 BAP_AWV_FSG_01_Header 0;
BA_ "GenSigSendType" SG_ 2536711426 BAP_BatteryControl_ASG_03_Header 3;
BA_ "GenSigSwitchedByIgnition" SG_ 2536711426 BAP_BatteryControl_ASG_03_Header 0;
BA_ "GenSigSendType" SG_ 2536711440 BAP_BatteryControl_FSG_01_Header 3;
BA_ "GenSigSwitchedByIgnition" SG_ 2536711440 BAP_BatteryControl_FSG_01_Header 0;
BA_ "GenSigSendType" SG_ 2536705792 BAP_BC_ASG_01_Header 3;
BA_ "GenSigSwitchedByIgnition" SG_ 2536705792 BAP_BC_ASG_01_Header 0;
BA_ "GenSigSendType" SG_ 2536705793 BAP_BC_ASG_02_Header 3;
BA_ "GenSigSwitchedByIgnition" SG_ 2536705793 BAP_BC_ASG_02_Header 0;
BA_ "GenSigSendType" SG_ 2536705808 BAP_BC_FSG_01_Header 3;
BA_ "GenSigSwitchedByIgnition" SG_ 2536705808 BAP_BC_FSG_01_Header 0;
BA_ "GenSigSendType" SG_ 2536705809 BAP_BC_FSG_02_Header 3;
BA_ "GenSigSwitchedByIgnition" SG_ 2536705809 BAP_BC_FSG_02_Header 0;
BA_ "GenSigSendType" SG_ 2536710912 BAP_BCmE_ASG_01_Header 3;
BA_ "GenSigSwitchedByIgnition" SG_ 2536710912 BAP_BCmE_ASG_01_Header 0;
BA_ "GenSigSendType" SG_ 2536710928 BAP_BCmE_FSG_01_Header 3;
BA_ "GenSigSwitchedByIgnition" SG_ 2536710928 BAP_BCmE_FSG_01_Header 0;
BA_ "GenSigSendType" SG_ 2536734976 BAP_California_ASG_01_Header 3;
BA_ "GenSigSwitchedByIgnition" SG_ 2536734976 BAP_California_ASG_01_Header 0;
BA_ "GenSigSendType" SG_ 2536734992 BAP_California_FSG_01_Header 3;
BA_ "GenSigSwitchedByIgnition" SG_ 2536734992 BAP_California_FSG_01_Header 0;
BA_ "GenSigSendType" SG_ 2536767264 BAP_Debug_Cmd 3;
BA_ "GenSigSwitchedByIgnition" SG_ 2536767264 BAP_Debug_Cmd 0;
BA_ "GenSigSendType" SG_ 2536767280 BAP_Debug_Data 3;
BA_ "GenSigSwitchedByIgnition" SG_ 2536767280 BAP_Debug_Data 0;
BA_ "GenSigSendType" SG_ 2536719616 BAP_DisplayConfig_ASG_01_Header 3;
BA_ "GenSigSwitchedByIgnition" SG_ 2536719616 BAP_DisplayConfig_ASG_01_Header 0;
BA_ "GenSigSendType" SG_ 2536719617 BAP_DisplayConfig_ASG_02_Header 3;
BA_ "GenSigSwitchedByIgnition" SG_ 2536719617 BAP_DisplayConfig_ASG_02_Header 0;
BA_ "GenSigSendType" SG_ 2536719632 BAP_DisplayConfig_FSG_01_Header 3;
BA_ "GenSigSwitchedByIgnition" SG_ 2536719632 BAP_DisplayConfig_FSG_01_Header 0;
BA_ "GenSigSendType" SG_ 2536705281 BAP_Doorlocking_ASG_02_Header 3;
BA_ "GenSigSwitchedByIgnition" SG_ 2536705281 BAP_Doorlocking_ASG_02_Header 0;
BA_ "GenSigSendType" SG_ 2536705296 BAP_Doorlocking_FSG_01_Header 3;
BA_ "GenSigSwitchedByIgnition" SG_ 2536705296 BAP_Doorlocking_FSG_01_Header 0;
BA_ "GenSigSendType" SG_ 2536717313 BAP_EfficAssist_ASG_02_Header 3;
BA_ "GenSigSwitchedByIgnition" SG_ 2536717313 BAP_EfficAssist_ASG_02_Header 0;
BA_ "GenSigSendType" SG_ 2536717314 BAP_EfficAssist_ASG_03_Header 3;
BA_ "GenSigSwitchedByIgnition" SG_ 2536717314 BAP_EfficAssist_ASG_03_Header 0;
BA_ "GenSigSendType" SG_ 2536717328 BAP_EfficAssist_FSG_01_Header 3;
BA_ "GenSigSwitchedByIgnition" SG_ 2536717328 BAP_EfficAssist_FSG_01_Header 0;
BA_ "GenSigSendType" SG_ 2536706816 BAP_Einheiten_ASG_01_Header 3;
BA_ "GenSigSwitchedByIgnition" SG_ 2536706816 BAP_Einheiten_ASG_01_Header 0;
BA_ "GenSigSendType" SG_ 2536706819 BAP_Einheiten_ASG_04_Header 3;
BA_ "GenSigSwitchedByIgnition" SG_ 2536706819 BAP_Einheiten_ASG_04_Header 0;
BA_ "GenSigSendType" SG_ 2536706832 BAP_Einheiten_FSG_01_Header 3;
BA_ "GenSigSwitchedByIgnition" SG_ 2536706832 BAP_Einheiten_FSG_01_Header 0;
BA_ "GenSigSendType" SG_ 2536702976 BAP_HUD_ASG_01_Header 3;
BA_ "GenSigSwitchedByIgnition" SG_ 2536702976 BAP_HUD_ASG_01_Header 0;
BA_ "GenSigSendType" SG_ 2536702977 BAP_HUD_ASG_02_Header 3;
BA_ "GenSigSwitchedByIgnition" SG_ 2536702977 BAP_HUD_ASG_02_Header 0;
BA_ "GenSigSendType" SG_ 2536702978 BAP_HUD_ASG_03_Header 3;
BA_ "GenSigSwitchedByIgnition" SG_ 2536702978 BAP_HUD_ASG_03_Header 0;
BA_ "GenSigSendType" SG_ 2536702992 BAP_HUD_FSG_01_Header 3;
BA_ "GenSigSwitchedByIgnition" SG_ 2536702992 BAP_HUD_FSG_01_Header 0;
BA_ "GenSigSendType" SG_ 2536709121 BAP_Hybrid_ASG_02_Header 3;
BA_ "GenSigSwitchedByIgnition" SG_ 2536709121 BAP_Hybrid_ASG_02_Header 0;
BA_ "GenSigSendType" SG_ 2536709136 BAP_Hybrid_FSG_01_Header 3;
BA_ "GenSigSwitchedByIgnition" SG_ 2536709136 BAP_Hybrid_FSG_01_Header 0;
BA_ "GenSigSendType" SG_ 2536722945 BAP_IAA_PSO_ASG_02_Header 3;
BA_ "GenSigSwitchedByIgnition" SG_ 2536722945 BAP_IAA_PSO_ASG_02_Header 0;
BA_ "GenSigSendType" SG_ 2536722960 BAP_IAA_PSO_FSG_01_Header 3;
BA_ "GenSigSwitchedByIgnition" SG_ 2536722960 BAP_IAA_PSO_FSG_01_Header 0;
BA_ "GenSigSendType" SG_ 2536704000 BAP_Innenlicht_ASG_01_Header 3;
BA_ "GenSigSwitchedByIgnition" SG_ 2536704000 BAP_Innenlicht_ASG_01_Header 0;
BA_ "GenSigSendType" SG_ 2536704003 BAP_Innenlicht_ASG_04_Header 3;
BA_ "GenSigSwitchedByIgnition" SG_ 2536704003 BAP_Innenlicht_ASG_04_Header 0;
BA_ "GenSigSendType" SG_ 2536704016 BAP_Innenlicht_FSG_01_Header 3;
BA_ "GenSigSwitchedByIgnition" SG_ 2536704016 BAP_Innenlicht_FSG_01_Header 0;
BA_ "GenSigSendType" SG_ 2536708353 BAP_LDW_ASG_02_Header 3;
BA_ "GenSigSwitchedByIgnition" SG_ 2536708353 BAP_LDW_ASG_02_Header 0;
BA_ "GenSigSendType" SG_ 2536708368 BAP_LDW_FSG_01_Header 3;
BA_ "GenSigSendType" SG_ 2536715264 BAP_MFL_ASG_01_Header 3;
BA_ "GenSigSwitchedByIgnition" SG_ 2536715264 BAP_MFL_ASG_01_Header 0;
BA_ "GenSigSendType" SG_ 2536715280 BAP_MFL_FSG_01_Header 3;
BA_ "GenSigSwitchedByIgnition" SG_ 2536715280 BAP_MFL_FSG_01_Header 0;
BA_ "GenSigSendType" SG_ 2536714752 BAP_Navigation_ASG_01_Header 3;
BA_ "GenSigSwitchedByIgnition" SG_ 2536714752 BAP_Navigation_ASG_01_Header 0;
BA_ "GenSigSendType" SG_ 2536714753 BAP_Navigation_ASG_02_Header 3;
BA_ "GenSigSwitchedByIgnition" SG_ 2536714753 BAP_Navigation_ASG_02_Header 0;
BA_ "GenSigSendType" SG_ 2536714754 BAP_Navigation_ASG_03_Header 3;
BA_ "GenSigSwitchedByIgnition" SG_ 2536714754 BAP_Navigation_ASG_03_Header 0;
BA_ "GenSigSendType" SG_ 2536714755 BAP_Navigation_ASG_04_Header 3;
BA_ "GenSigSwitchedByIgnition" SG_ 2536714755 BAP_Navigation_ASG_04_Header 0;
BA_ "GenSigSendType" SG_ 2536714768 BAP_Navigation_FSG_01_Header 3;
BA_ "GenSigSwitchedByIgnition" SG_ 2536714768 BAP_Navigation_FSG_01_Header 0;
BA_ "GenSigSendType" SG_ 2536714769 BAP_Navigation_FSG_02_Header 3;
BA_ "GenSigSwitchedByIgnition" SG_ 2536714769 BAP_Navigation_FSG_02_Header 0;
BA_ "GenSigSendType" SG_ 2536712704 BAP_OnlineFunction_ASG_01_Header 3;
BA_ "GenSigSwitchedByIgnition" SG_ 2536712704 BAP_OnlineFunction_ASG_01_Header 0;
BA_ "GenSigSendType" SG_ 2536712705 BAP_OnlineFunction_ASG_02_Header 3;
BA_ "GenSigSwitchedByIgnition" SG_ 2536712705 BAP_OnlineFunction_ASG_02_Header 0;
BA_ "GenSigSendType" SG_ 2536712720 BAP_OnlineFunction_FSG_01_Header 3;
BA_ "GenSigSwitchedByIgnition" SG_ 2536712720 BAP_OnlineFunction_FSG_01_Header 0;
BA_ "GenSigSendType" SG_ 2536704512 BAP_OPS_ASG_01_Header 3;
BA_ "GenSigSwitchedByIgnition" SG_ 2536704512 BAP_OPS_ASG_01_Header 0;
BA_ "GenSigSendType" SG_ 2536704518 BAP_OPS_ASG_07_Header 3;
BA_ "GenSigSwitchedByIgnition" SG_ 2536704518 BAP_OPS_ASG_07_Header 0;
BA_ "GenSigSendType" SG_ 2536704528 BAP_OPS_FSG_01_Header 3;
BA_ "GenSigSwitchedByIgnition" SG_ 2536704528 BAP_OPS_FSG_01_Header 0;
BA_ "GenSigSendType" SG_ 2536704529 BAP_OPS_FSG_02_Header 3;
BA_ "GenSigSwitchedByIgnition" SG_ 2536704529 BAP_OPS_FSG_02_Header 0;
BA_ "GenSigSendType" SG_ 2536723713 BAP_PaCo_ASG_02_Header 3;
BA_ "GenSigSwitchedByIgnition" SG_ 2536723713 BAP_PaCo_ASG_02_Header 0;
BA_ "GenSigSendType" SG_ 2536723716 BAP_PaCo_ASG_05_Header 3;
BA_ "GenSigSwitchedByIgnition" SG_ 2536723716 BAP_PaCo_ASG_05_Header 0;
BA_ "GenSigSendType" SG_ 2536723728 BAP_PaCo_FSG_01_Header 3;
BA_ "GenSigSwitchedByIgnition" SG_ 2536723728 BAP_PaCo_FSG_01_Header 0;
BA_ "GenSigSendType" SG_ 2536731136 BAP_RMeasurement_ASG_01_Header 3;
BA_ "GenSigSwitchedByIgnition" SG_ 2536731136 BAP_RMeasurement_ASG_01_Header 0;
BA_ "GenSigSendType" SG_ 2536731137 BAP_RMeasurement_ASG_02_Header 3;
BA_ "GenSigSwitchedByIgnition" SG_ 2536731137 BAP_RMeasurement_ASG_02_Header 0;
BA_ "GenSigSendType" SG_ 2536731152 BAP_RMeasurement_FSG_01_Header 3;
BA_ "GenSigSwitchedByIgnition" SG_ 2536731152 BAP_RMeasurement_FSG_01_Header 0;
BA_ "GenSigSendType" SG_ 2536731153 BAP_RMeasurement_FSG_02_Header 3;
BA_ "GenSigSwitchedByIgnition" SG_ 2536731153 BAP_RMeasurement_FSG_02_Header 0;
BA_ "GenSigSendType" SG_ 2536703745 BAP_RDK_ASG_02_Header 3;
BA_ "GenSigSwitchedByIgnition" SG_ 2536703745 BAP_RDK_ASG_02_Header 0;
BA_ "GenSigSendType" SG_ 2536703760 BAP_RDK_FSG_01_Header 3;
BA_ "GenSigSwitchedByIgnition" SG_ 2536703760 BAP_RDK_FSG_01_Header 0;
BA_ "GenSigSendType" SG_ 2536719872 BAP_SDS_ASG_01_Header 3;
BA_ "GenSigSwitchedByIgnition" SG_ 2536719872 BAP_SDS_ASG_01_Header 0;
BA_ "GenSigSendType" SG_ 2536719888 BAP_SDS_FSG_01_Header 3;
BA_ "GenSigSwitchedByIgnition" SG_ 2536719888 BAP_SDS_FSG_01_Header 0;
BA_ "GenSigSendType" SG_ 2536706560 BAP_SIA_ASG_01_Header 3;
BA_ "GenSigSwitchedByIgnition" SG_ 2536706560 BAP_SIA_ASG_01_Header 0;
BA_ "GenSigSendType" SG_ 2536706561 BAP_SIA_ASG_02_Header 3;
BA_ "GenSigSwitchedByIgnition" SG_ 2536706561 BAP_SIA_ASG_02_Header 0;
BA_ "GenSigSendType" SG_ 2536706576 BAP_SIA_FSG_01_Header 3;
BA_ "GenSigSwitchedByIgnition" SG_ 2536706576 BAP_SIA_FSG_01_Header 0;
BA_ "GenSigSendType" SG_ 2536736001 BAP_SLCView_ASG_02_Header 3;
BA_ "GenSigSwitchedByIgnition" SG_ 2536736001 BAP_SLCView_ASG_02_Header 0;
BA_ "GenSigSendType" SG_ 2536736016 BAP_SLCView_FSG_01_Header 3;
BA_ "GenSigSwitchedByIgnition" SG_ 2536736016 BAP_SLCView_FSG_01_Header 0;
BA_ "GenSigSendType" SG_ 2536711937 BAP_StartStopReasons_ASG_02_Head 3;
BA_ "GenSigSwitchedByIgnition" SG_ 2536711937 BAP_StartStopReasons_ASG_02_Head 0;
BA_ "GenSigSendType" SG_ 2536711952 BAP_StartStopReasons_FSG_01_Head 3;
BA_ "GenSigSwitchedByIgnition" SG_ 2536711952 BAP_StartStopReasons_FSG_01_Head 0;
BA_ "GenSigSendType" SG_ 2536720896 BAP_Statistics_ASG_01_Header 3;
BA_ "GenSigSwitchedByIgnition" SG_ 2536720896 BAP_Statistics_ASG_01_Header 0;
BA_ "GenSigSendType" SG_ 2536720912 BAP_Statistics_FSG_01_Header 3;
BA_ "GenSigSwitchedByIgnition" SG_ 2536720912 BAP_Statistics_FSG_01_Header 0;
BA_ "GenSigSendType" SG_ 2536708609 BAP_SWA_ASG_02_Header 3;
BA_ "GenSigSwitchedByIgnition" SG_ 2536708609 BAP_SWA_ASG_02_Header 0;
BA_ "GenSigSendType" SG_ 2536708624 BAP_SWA_FSG_01_Header 3;
BA_ "GenSigSendType" SG_ 2536712448 BAP_Telefon2_ASG_01_Header 3;
BA_ "GenSigSwitchedByIgnition" SG_ 2536712448 BAP_Telefon2_ASG_01_Header 0;
BA_ "GenSigSendType" SG_ 2536712449 BAP_Telefon2_ASG_02_Header 3;
BA_ "GenSigSwitchedByIgnition" SG_ 2536712449 BAP_Telefon2_ASG_02_Header 0;
BA_ "GenSigSendType" SG_ 2536712464 BAP_Telefon2_FSG_01_Header 3;
BA_ "GenSigSwitchedByIgnition" SG_ 2536712464 BAP_Telefon2_FSG_01_Header 0;
BA_ "GenSigSendType" SG_ 2536712465 BAP_Telefon2_FSG_02_Header 3;
BA_ "GenSigSwitchedByIgnition" SG_ 2536712465 BAP_Telefon2_FSG_02_Header 0;
BA_ "GenSigSendType" SG_ 2536712192 BAP_Telefon_ASG_01_Header 3;
BA_ "GenSigSwitchedByIgnition" SG_ 2536712192 BAP_Telefon_ASG_01_Header 0;
BA_ "GenSigSendType" SG_ 2536712193 BAP_Telefon_ASG_02_Header 3;
BA_ "GenSigSwitchedByIgnition" SG_ 2536712193 BAP_Telefon_ASG_02_Header 0;
BA_ "GenSigSendType" SG_ 2536712194 BAP_Telefon_ASG_03_Header 3;
BA_ "GenSigSwitchedByIgnition" SG_ 2536712194 BAP_Telefon_ASG_03_Header 0;
BA_ "GenSigSendType" SG_ 2536712195 BAP_Telefon_ASG_04_Header 3;
BA_ "GenSigSwitchedByIgnition" SG_ 2536712195 BAP_Telefon_ASG_04_Header 0;
BA_ "GenSigSendType" SG_ 2536712208 BAP_Telefon_FSG_01_Header 3;
BA_ "GenSigSwitchedByIgnition" SG_ 2536712208 BAP_Telefon_FSG_01_Header 0;
BA_ "GenSigSendType" SG_ 2536712209 BAP_Telefon_FSG_02_Header 3;
BA_ "GenSigSwitchedByIgnition" SG_ 2536712209 BAP_Telefon_FSG_02_Header 0;
BA_ "GenSigSendType" SG_ 2536706304 BAP_Uhrzeit_ASG_01_Header 3;
BA_ "GenSigSwitchedByIgnition" SG_ 2536706304 BAP_Uhrzeit_ASG_01_Header 0;
BA_ "GenSigSendType" SG_ 2536706305 BAP_Uhrzeit_ASG_02_Header 3;
BA_ "GenSigSwitchedByIgnition" SG_ 2536706305 BAP_Uhrzeit_ASG_02_Header 0;
BA_ "GenSigSendType" SG_ 2536706308 BAP_Uhrzeit_ASG_05_Header 3;
BA_ "GenSigSwitchedByIgnition" SG_ 2536706308 BAP_Uhrzeit_ASG_05_Header 0;
BA_ "GenSigSendType" SG_ 2536706320 BAP_Uhrzeit_FSG_01_Header 3;
BA_ "GenSigSwitchedByIgnition" SG_ 2536706320 BAP_Uhrzeit_FSG_01_Header 0;
BA_ "GenSigSendType" SG_ 2536710401 BAP_VZA_ASG_02_Header 3;
BA_ "GenSigSwitchedByIgnition" SG_ 2536710401 BAP_VZA_ASG_02_Header 0;
BA_ "GenSigSendType" SG_ 2536710402 BAP_VZA_ASG_03_Header 3;
BA_ "GenSigSwitchedByIgnition" SG_ 2536710402 BAP_VZA_ASG_03_Header 0;
BA_ "GenSigSendType" SG_ 2536710416 BAP_VZA_FSG_01_Header 3;
BA_ "GenSigSendType" SG_ 2583694872 BCM1_AuthTime_Req_Data 3;
BA_ "GenSigFuncType" SG_ 2583694872 BCM1_AuthTime_Req_Data 9;
BA_ "GenSigSwitchedByIgnition" SG_ 2583694872 BCM1_AuthTime_Req_Data 0;
BA_ "GenSigSendType" SG_ 2583825944 BCM1_AuthTime_Resp_Data 3;
BA_ "GenSigFuncType" SG_ 2583825944 BCM1_AuthTime_Resp_Data 9;
BA_ "GenSigSwitchedByIgnition" SG_ 2583825944 BCM1_AuthTime_Resp_Data 0;
BA_ "GenSigSendType" SG_ 1626 APS_Tongeber_defekt 3;
BA_ "GenSigSwitchedByIgnition" SG_ 1626 APS_Tongeber_defekt 0;
BA_ "GenSigSendType" SG_ 1626 BCM1_AFS_Lampe 3;
BA_ "GenSigSwitchedByIgnition" SG_ 1626 BCM1_AFS_Lampe 0;
BA_ "GenSigSendType" SG_ 1626 BCM1_EasyEntry_Status 3;
BA_ "GenSigSwitchedByIgnition" SG_ 1626 BCM1_EasyEntry_Status 0;
BA_ "GenSigSendType" SG_ 1626 BCM1_Fahrlicht_Hinweis 3;
BA_ "GenSigSwitchedByIgnition" SG_ 1626 BCM1_Fahrlicht_Hinweis 0;
BA_ "GenSigSendType" SG_ 1626 BCM1_Hinweis_Lichtnachlauf 3;
BA_ "GenSigSwitchedByIgnition" SG_ 1626 BCM1_Hinweis_Lichtnachlauf 0;
BA_ "GenSigSendType" SG_ 1626 BCM1_Kl_15_HW_erkannt 3;
BA_ "GenSigSwitchedByIgnition" SG_ 1626 BCM1_Kl_15_HW_erkannt 0;
BA_ "GenSigSendType" SG_ 1626 BCM1_Kl_15_Sig_HW_erkannt 3;
BA_ "GenSigSwitchedByIgnition" SG_ 1626 BCM1_Kl_15_Sig_HW_erkannt 0;
BA_ "GenSigSendType" SG_ 1626 BCM1_LDS_Stellung 3;
BA_ "GenSigSwitchedByIgnition" SG_ 1626 BCM1_LDS_Stellung 0;
BA_ "Fehlerwert" SG_ 1626 BCM1_LDS_Stellung 7;
BA_ "GenSigSendType" SG_ 1626 BCM1_Lenksaeule_aktiv 3;
BA_ "GenSigSwitchedByIgnition" SG_ 1626 BCM1_Lenksaeule_aktiv 0;
BA_ "GenSigSendType" SG_ 1626 BCM1_Licht_Warn 3;
BA_ "GenSigSwitchedByIgnition" SG_ 1626 BCM1_Licht_Warn 0;
BA_ "GenSigSendType" SG_ 1626 BCM1_Lichtwarn_Texte 3;
BA_ "GenSigSwitchedByIgnition" SG_ 1626 BCM1_Lichtwarn_Texte 0;
BA_ "GenSigSendType" SG_ 1626 BCM1_MH_Schalter 3;
BA_ "GenSigSwitchedByIgnition" SG_ 1626 BCM1_MH_Schalter 0;
BA_ "GenSigSendType" SG_ 1626 BCM1_MH_WIV_Schalter 3;
BA_ "GenSigSwitchedByIgnition" SG_ 1626 BCM1_MH_WIV_Schalter 0;
BA_ "GenSigSendType" SG_ 1626 BCM1_NV_Taster 0;
BA_ "GenSigSwitchedByIgnition" SG_ 1626 BCM1_NV_Taster 0;
BA_ "GenSigSendType" SG_ 1626 BCM1_Reisemodus_Texte 3;
BA_ "GenSigSwitchedByIgnition" SG_ 1626 BCM1_Reisemodus_Texte 0;
BA_ "GenSigSendType" SG_ 1626 BCM1_Rueckfahrlicht_Schalter 3;
BA_ "GenSigSwitchedByIgnition" SG_ 1626 BCM1_Rueckfahrlicht_Schalter 0;
BA_ "GenSigSendType" SG_ 1626 BCM1_Spannungs_Anf 3;
BA_ "GenSigSwitchedByIgnition" SG_ 1626 BCM1_Spannungs_Anf 0;
BA_ "GenSigSendType" SG_ 1626 BCM1_Valet_Parking_Taster 0;
BA_ "GenSigSwitchedByIgnition" SG_ 1626 BCM1_Valet_Parking_Taster 0;
BA_ "GenSigSendType" SG_ 1626 BCM1_Warnblink_Taster 3;
BA_ "GenSigSwitchedByIgnition" SG_ 1626 BCM1_Warnblink_Taster 0;
BA_ "GenSigSendType" SG_ 1626 BCM_Anf_AAW_MoLaWa 3;
BA_ "GenSigSwitchedByIgnition" SG_ 1626 BCM_Anf_AAW_MoLaWa 0;
BA_ "GenSigSendType" SG_ 1626 BCM_Bremsbelag_Sensor 3;
BA_ "GenSigSwitchedByIgnition" SG_ 1626 BCM_Bremsbelag_Sensor 0;
BA_ "GenSigSendType" SG_ 1626 BCM_Bremsfluessigkeit_Sensor 3;
BA_ "GenSigSwitchedByIgnition" SG_ 1626 BCM_Bremsfluessigkeit_Sensor 0;
BA_ "GenSigSendType" SG_ 1626 BCM_Charisma_Taste2 3;
BA_ "GenSigSwitchedByIgnition" SG_ 1626 BCM_Charisma_Taste2 0;
BA_ "GenSigSendType" SG_ 1626 BCM_Eco_Charisma_Taste 3;
BA_ "GenSigSwitchedByIgnition" SG_ 1626 BCM_Eco_Charisma_Taste 0;
BA_ "GenSigSendType" SG_ 1626 BCM_Handbremse_Hinweis 4;
BA_ "GenSigSwitchedByIgnition" SG_ 1626 BCM_Handbremse_Hinweis 0;
BA_ "GenSigSendType" SG_ 1626 BCM_HBFS_EOE_aktiv 4;
BA_ "GenSigSwitchedByIgnition" SG_ 1626 BCM_HBFS_EOE_aktiv 0;
BA_ "GenSigSendType" SG_ 1626 BCM_HDF_betaetigt 4;
BA_ "GenSigSwitchedByIgnition" SG_ 1626 BCM_HDF_betaetigt 0;
BA_ "GenSigSendType" SG_ 1626 BCM_HFS_EOE_aktiv 4;
BA_ "GenSigSwitchedByIgnition" SG_ 1626 BCM_HFS_EOE_aktiv 0;
BA_ "GenSigSendType" SG_ 1626 BCM_Hybrid_StartStopp_Taste 3;
BA_ "GenSigSwitchedByIgnition" SG_ 1626 BCM_Hybrid_StartStopp_Taste 0;
BA_ "GenSigSendType" SG_ 1626 BCM_Hybrid_StSt_Taste_Fehler 3;
BA_ "GenSigSwitchedByIgnition" SG_ 1626 BCM_Hybrid_StSt_Taste_Fehler 0;
BA_ "GenSigSendType" SG_ 1626 BCM_Kuehlmittel_Sensor 3;
BA_ "GenSigSwitchedByIgnition" SG_ 1626 BCM_Kuehlmittel_Sensor 0;
BA_ "GenSigSendType" SG_ 1626 BCM_Kuehlmittel_Sensor_02 3;
BA_ "GenSigSwitchedByIgnition" SG_ 1626 BCM_Kuehlmittel_Sensor_02 0;
BA_ "GenSigSendType" SG_ 1626 BCM_Offroad_Taste 3;
BA_ "GenSigSwitchedByIgnition" SG_ 1626 BCM_Offroad_Taste 0;
BA_ "GenSigSendType" SG_ 1626 BCM_ValetTaster_Fkts_LED 4;
BA_ "GenSigSwitchedByIgnition" SG_ 1626 BCM_ValetTaster_Fkts_LED 0;
BA_ "GenSigSendType" SG_ 1626 BCM_Waehlhebel_P_Hinweis 4;
BA_ "GenSigSwitchedByIgnition" SG_ 1626 BCM_Waehlhebel_P_Hinweis 0;
BA_ "GenSigSendType" SG_ 1626 BCM_Waschwasser_Sensor 3;
BA_ "GenSigSwitchedByIgnition" SG_ 1626 BCM_Waschwasser_Sensor 0;
BA_ "GenSigSendType" SG_ 1626 DWA_Alarmquelle 0;
BA_ "GenSigStartValue" SG_ 1626 DWA_Alarmquelle 30;
BA_ "GenSigSwitchedByIgnition" SG_ 1626 DWA_Alarmquelle 0;
BA_ "Fehlerwert" SG_ 1626 DWA_Alarmquelle 31;
BA_ "GenSigSendType" SG_ 1626 DWA_Einschraenkung 0;
BA_ "GenSigSwitchedByIgnition" SG_ 1626 DWA_Einschraenkung 0;
BA_ "Fehlerwert" SG_ 1626 DWA_Einschraenkung 1;
BA_ "GenSigSendType" SG_ 1626 Gong_TFL_Umschaltung 3;
BA_ "GenSigSwitchedByIgnition" SG_ 1626 Gong_TFL_Umschaltung 0;
BA_ "GenSigSendType" SG_ 1626 LRH_Taster 3;
BA_ "GenSigSwitchedByIgnition" SG_ 1626 LRH_Taster 0;
BA_ "GenSigSendType" SG_ 2527679637 BCM_anf_VLW 3;
BA_ "GenSigSwitchedByIgnition" SG_ 2527679637 BCM_anf_VLW 0;
BA_ "GenSigSendType" SG_ 2527679637 BCM_Defrost_Taste 3;
BA_ "GenSigStartValue" SG_ 2527679637 BCM_Defrost_Taste 3;
BA_ "GenSigSwitchedByIgnition" SG_ 2527679637 BCM_Defrost_Taste 0;
BA_ "Fehlerwert" SG_ 2527679637 BCM_Defrost_Taste 2;
BA_ "GenSigSendType" SG_ 2527679637 BCM_FAS_Taster 4;
BA_ "GenSigSwitchedByIgnition" SG_ 2527679637 BCM_FAS_Taster 0;
BA_ "GenSigSendType" SG_ 2527679637 BCM_FSH_Taste 3;
BA_ "GenSigStartValue" SG_ 2527679637 BCM_FSH_Taste 3;
BA_ "GenSigSwitchedByIgnition" SG_ 2527679637 BCM_FSH_Taste 0;
BA_ "Fehlerwert" SG_ 2527679637 BCM_FSH_Taste 2;
BA_ "GenSigSendType" SG_ 2527679637 BCM_HSH_Taste 3;
BA_ "GenSigStartValue" SG_ 2527679637 BCM_HSH_Taste 3;
BA_ "GenSigSwitchedByIgnition" SG_ 2527679637 BCM_HSH_Taste 0;
BA_ "Fehlerwert" SG_ 2527679637 BCM_HSH_Taste 2;
BA_ "GenSigSendType" SG_ 2527679637 BCM_LTM_Allwetterl_Status 3;
BA_ "GenSigSwitchedByIgnition" SG_ 2527679637 BCM_LTM_Allwetterl_Status 0;
BA_ "GenSigSendType" SG_ 2527679637 BCM_LTM_Nebell_Status 3;
BA_ "GenSigSwitchedByIgnition" SG_ 2527679637 BCM_LTM_Nebell_Status 0;
BA_ "GenSigSendType" SG_ 2527679637 BCM_LTM_Nebelschluss_Status 3;
BA_ "GenSigSwitchedByIgnition" SG_ 2527679637 BCM_LTM_Nebelschluss_Status 0;
BA_ "GenSigSendType" SG_ 2527679637 BCM_LTM_PopUp_Anf 3;
BA_ "GenSigSwitchedByIgnition" SG_ 2527679637 BCM_LTM_PopUp_Anf 0;
BA_ "GenSigSendType" SG_ 2527679637 BCM_LTM_PopUp_Inhalt 3;
BA_ "GenSigSwitchedByIgnition" SG_ 2527679637 BCM_LTM_PopUp_Inhalt 0;
BA_ "GenSigSendType" SG_ 2527679637 BCM_LTM_PopUp_Status 3;
BA_ "GenSigSwitchedByIgnition" SG_ 2527679637 BCM_LTM_PopUp_Status 0;
BA_ "GenSigSendType" SG_ 2527679637 BCM_LTM_PopUp_Texte 3;
BA_ "GenSigSwitchedByIgnition" SG_ 2527679637 BCM_LTM_PopUp_Texte 0;
BA_ "GenSigSendType" SG_ 2527679637 CPD_Warnung 3;
BA_ "GenSigSwitchedByIgnition" SG_ 2527679637 CPD_Warnung 0;
BA_ "GenSigSendType" SG_ 2527679637 LiSi_Touch_Event 3;
BA_ "GenSigSwitchedByIgnition" SG_ 2527679637 LiSi_Touch_Event 0;
BA_ "Fehlerwert" SG_ 2527679637 LiSi_Touch_Event 15;
BA_ "GenSigSendType" SG_ 2527679637 LTMs_01_alt 0;
BA_ "GenSigStartValue" SG_ 2527679637 LTMs_01_alt 1;
BA_ "GenSigFuncType" SG_ 2527679637 LTMs_01_alt 5;
BA_ "GenSigSwitchedByIgnition" SG_ 2527679637 LTMs_01_alt 0;
BA_ "GenSigSendType" SG_ 2527679637 MiKo_Tisch_Positionswarnung 3;
BA_ "GenSigSwitchedByIgnition" SG_ 2527679637 MiKo_Tisch_Positionswarnung 0;
BA_ "GenSigSendType" SG_ 2463978607 BCM_RGB_Blau 3;
BA_ "GenSigSwitchedByIgnition" SG_ 2463978607 BCM_RGB_Blau 0;
BA_ "GenSigSendType" SG_ 2463978607 BCM_RGB_Dimmrampe 3;
BA_ "GenSigSwitchedByIgnition" SG_ 2463978607 BCM_RGB_Dimmrampe 0;
BA_ "GenSigSendType" SG_ 2463978607 BCM_RGB_Dimmzeit_Zeitbasis 3;
BA_ "GenSigSwitchedByIgnition" SG_ 2463978607 BCM_RGB_Dimmzeit_Zeitbasis 0;
BA_ "GenSigSendType" SG_ 2463978607 BCM_RGB_Gruen 3;
BA_ "GenSigSwitchedByIgnition" SG_ 2463978607 BCM_RGB_Gruen 0;
BA_ "GenSigSendType" SG_ 2463978607 BCM_RGB_Intensitaet 3;
BA_ "GenSigStartValue" SG_ 2463978607 BCM_RGB_Intensitaet 126;
BA_ "GenSigSwitchedByIgnition" SG_ 2463978607 BCM_RGB_Intensitaet 0;
BA_ "Fehlerwert" SG_ 2463978607 BCM_RGB_Intensitaet 127;
BA_ "GenSigSendType" SG_ 2463978607 BCM_RGB_Normierung_Intensitaet 3;
BA_ "GenSigSwitchedByIgnition" SG_ 2463978607 BCM_RGB_Normierung_Intensitaet 0;
BA_ "GenSigSendType" SG_ 2463978607 BCM_RGB_Rot 3;
BA_ "GenSigSwitchedByIgnition" SG_ 2463978607 BCM_RGB_Rot 0;
BA_ "GenSigSendType" SG_ 2463978609 BCM_Relais_2_Batterie 3;
BA_ "GenSigSwitchedByIgnition" SG_ 2463978609 BCM_Relais_2_Batterie 0;
BA_ "GenSigSendType" SG_ 2463978609 FA_Hoehenwert_HL_01 3;
BA_ "GenSigStartValue" SG_ 2463978609 FA_Hoehenwert_HL_01 254;
BA_ "Fehlerwert" SG_ 2463978609 FA_Hoehenwert_HL_01 255;
BA_ "GenSigSendType" SG_ 2463978609 FA_Hoehenwert_VL_01 3;
BA_ "GenSigStartValue" SG_ 2463978609 FA_Hoehenwert_VL_01 254;
BA_ "Fehlerwert" SG_ 2463978609 FA_Hoehenwert_VL_01 255;
BA_ "GenSigSendType" SG_ 2463978609 HSH_LED 3;
BA_ "GenSigSwitchedByIgnition" SG_ 2463978609 HSH_LED 0;
BA_ "GenSigSendType" SG_ 2463978609 HSH_Status 0;
BA_ "GenSigSwitchedByIgnition" SG_ 2463978609 HSH_Status 0;
BA_ "GenSigSendType" SG_ 2463978609 KRH_Stufe_LED_li 3;
BA_ "GenSigSwitchedByIgnition" SG_ 2463978609 KRH_Stufe_LED_li 0;
BA_ "GenSigSendType" SG_ 2463978609 KRH_Stufe_LED_re 3;
BA_ "GenSigSwitchedByIgnition" SG_ 2463978609 KRH_Stufe_LED_re 0;
BA_ "GenSigSendType" SG_ 2463978609 Niveausensor_HL_verbaut 3;
BA_ "GenSigSwitchedByIgnition" SG_ 2463978609 Niveausensor_HL_verbaut 0;
BA_ "GenSigSendType" SG_ 2463978609 Niveausensor_VL_verbaut 3;
BA_ "GenSigSwitchedByIgnition" SG_ 2463978609 Niveausensor_VL_verbaut 0;
BA_ "GenSigSendType" SG_ 2463978609 SIL_Stufe_LED_li 3;
BA_ "GenSigSwitchedByIgnition" SG_ 2463978609 SIL_Stufe_LED_li 0;
BA_ "GenSigSendType" SG_ 2463978609 SIL_Stufe_LED_re 3;
BA_ "GenSigSwitchedByIgnition" SG_ 2463978609 SIL_Stufe_LED_re 0;
BA_ "GenSigSendType" SG_ 2463978887 BDM_I_Batt_Low 0;
BA_ "GenSigSwitchedByIgnition" SG_ 2463978887 BDM_I_Batt_Low 0;
BA_ "GenSigSendType" SG_ 2463978887 BDM_I_Bereich_dyn 0;
BA_ "GenSigStartValue" SG_ 2463978887 BDM_I_Bereich_dyn 3;
BA_ "GenSigSwitchedByIgnition" SG_ 2463978887 BDM_I_Bereich_dyn 0;
BA_ "GenSigSendType" SG_ 2463978887 BDM_Kommunikationsbasis 0;
BA_ "GenSigStartValue" SG_ 2463978887 BDM_Kommunikationsbasis 1;
BA_ "GenSigSwitchedByIgnition" SG_ 2463978887 BDM_Kommunikationsbasis 0;
BA_ "GenSigSendType" SG_ 2463978887 BDM_QRS_Feedback 0;
BA_ "GenSigSwitchedByIgnition" SG_ 2463978887 BDM_QRS_Feedback 0;
BA_ "GenSigSendType" SG_ 2463978887 BDM_ResponseError 0;
BA_ "GenSigSwitchedByIgnition" SG_ 2463978887 BDM_ResponseError 0;
BA_ "Fehlerwert" SG_ 2463978887 BDM_ResponseError 1;
BA_ "GenSigSendType" SG_ 2463978887 BDM_Spannung_dyn 0;
BA_ "GenSigStartValue" SG_ 2463978887 BDM_Spannung_dyn 16383;
BA_ "GenSigSwitchedByIgnition" SG_ 2463978887 BDM_Spannung_dyn 0;
BA_ "GenSigSendType" SG_ 2463978887 BDM_Status_dyn 0;
BA_ "GenSigSwitchedByIgnition" SG_ 2463978887 BDM_Status_dyn 0;
BA_ "GenSigSendType" SG_ 2463978887 BDM_Strom_dyn 0;
BA_ "GenSigStartValue" SG_ 2463978887 BDM_Strom_dyn 65535;
BA_ "GenSigSwitchedByIgnition" SG_ 2463978887 BDM_Strom_dyn 0;
BA_ "GenSigSendType" SG_ 2463978887 BDM_Temp_dyn 0;
BA_ "GenSigStartValue" SG_ 2463978887 BDM_Temp_dyn 255;
BA_ "GenSigSwitchedByIgnition" SG_ 2463978887 BDM_Temp_dyn 0;
BA_ "GenSigSendType" SG_ 2463978887 BDM_UBattVorgabe 0;
BA_ "GenSigStartValue" SG_ 2463978887 BDM_UBattVorgabe 63;
BA_ "GenSigSwitchedByIgnition" SG_ 2463978887 BDM_UBattVorgabe 0;
BA_ "GenSigSendType" SG_ 2463978887 BDM_WD_dyn 0;
BA_ "GenSigSwitchedByIgnition" SG_ 2463978887 BDM_WD_dyn 0;
BA_ "GenSigSendType" SG_ 2463978887 BDM_Zaehler_dyn 0;
BA_ "GenSigSwitchedByIgnition" SG_ 2463978887 BDM_Zaehler_dyn 0;
BA_ "GenSigSendType" SG_ 2463978882 BedienDisp_hbfs_01_BZ 0;
BA_ "GenSigFuncType" SG_ 2463978882 BedienDisp_hbfs_01_BZ 1;
BA_ "GenSigSwitchedByIgnition" SG_ 2463978882 BedienDisp_hbfs_01_BZ 0;
BA_ "GenSigSendType" SG_ 2463978882 BedienDisp_hbfs_01_CRC 0;
BA_ "GenSigFuncType" SG_ 2463978882 BedienDisp_hbfs_01_CRC 2;
BA_ "GenSigSwitchedByIgnition" SG_ 2463978882 BedienDisp_hbfs_01_CRC 0;
BA_ "GenSigSendType" SG_ 2463978882 BedienDisp_hbfs_control_vol 4;
BA_ "GenSigSwitchedByIgnition" SG_ 2463978882 BedienDisp_hbfs_control_vol 0;
BA_ "Fehlerwert" SG_ 2463978882 BedienDisp_hbfs_control_vol 15;
BA_ "GenSigSendType" SG_ 2463978882 BedienDisp_hbfs_control_vol_02 4;
BA_ "GenSigStartValue" SG_ 2463978882 BedienDisp_hbfs_control_vol_02 126;
BA_ "GenSigSwitchedByIgnition" SG_ 2463978882 BedienDisp_hbfs_control_vol_02 0;
BA_ "Fehlerwert" SG_ 2463978882 BedienDisp_hbfs_control_vol_02 127;
BA_ "GenSigSendType" SG_ 2463978882 BedienDisp_hbfs_fader 4;
BA_ "GenSigSwitchedByIgnition" SG_ 2463978882 BedienDisp_hbfs_fader 0;
BA_ "Fehlerwert" SG_ 2463978882 BedienDisp_hbfs_fader 15;
BA_ "GenSigSendType" SG_ 2463978882 BedienDisp_hbfs_Lordose_hoch 4;
BA_ "GenSigSwitchedByIgnition" SG_ 2463978882 BedienDisp_hbfs_Lordose_hoch 0;
BA_ "GenSigSendType" SG_ 2463978882 BedienDisp_hbfs_Lordose_runter 4;
BA_ "GenSigSwitchedByIgnition" SG_ 2463978882 BedienDisp_hbfs_Lordose_runter 0;
BA_ "GenSigSendType" SG_ 2463978882 BedienDisp_hbfs_Lordose_vor 4;
BA_ "GenSigSwitchedByIgnition" SG_ 2463978882 BedienDisp_hbfs_Lordose_vor 0;
BA_ "GenSigSendType" SG_ 2463978882 BedienDisp_hbfs_Lordose_zurueck 4;
BA_ "GenSigSwitchedByIgnition" SG_ 2463978882 BedienDisp_hbfs_Lordose_zurueck 0;
BA_ "GenSigSendType" SG_ 2463978882 BedienDisp_hbfs_sound 4;
BA_ "GenSigSwitchedByIgnition" SG_ 2463978882 BedienDisp_hbfs_sound 0;
BA_ "GenSigSendType" SG_ 2463978882 BedienDisp_hbfs_sound_fokus 4;
BA_ "GenSigSwitchedByIgnition" SG_ 2463978882 BedienDisp_hbfs_sound_fokus 0;
BA_ "Fehlerwert" SG_ 2463978882 BedienDisp_hbfs_sound_fokus 15;
BA_ "GenSigSendType" SG_ 2463978882 BedienDisp_hbfs_surround 4;
BA_ "GenSigSwitchedByIgnition" SG_ 2463978882 BedienDisp_hbfs_surround 0;
BA_ "Fehlerwert" SG_ 2463978882 BedienDisp_hbfs_surround 15;
BA_ "GenSigSendType" SG_ 2463978882 BedienDisp_hbfs_surround_02 4;
BA_ "Fehlerwert" SG_ 2463978882 BedienDisp_hbfs_surround_02 127;
BA_ "GenSigSendType" SG_ 2463978882 BedienDisp_hbfs_touch 4;
BA_ "GenSigSwitchedByIgnition" SG_ 2463978882 BedienDisp_hbfs_touch 0;
BA_ "Fehlerwert" SG_ 2463978882 BedienDisp_hbfs_touch 15;
BA_ "GenSigSendType" SG_ 2463978882 BedienDisp_hbfs_UseCase_Pos 3;
BA_ "GenSigSwitchedByIgnition" SG_ 2463978882 BedienDisp_hbfs_UseCase_Pos 0;
BA_ "GenSigSendType" SG_ 2463978882 BedienDisp_HBFSFo_Bestaetigung 3;
BA_ "GenSigSwitchedByIgnition" SG_ 2463978882 BedienDisp_HBFSFo_Bestaetigung 0;
BA_ "Fehlerwert" SG_ 2463978882 BedienDisp_HBFSFo_Bestaetigung 3;
BA_ "GenSigSendType" SG_ 2463978882 BedienDisp_HBFSFo_Stoerung 3;
BA_ "GenSigSwitchedByIgnition" SG_ 2463978882 BedienDisp_HBFSFo_Stoerung 0;
BA_ "GenSigSendType" SG_ 2463978881 BedienDisp_hfs_01_BZ 0;
BA_ "GenSigFuncType" SG_ 2463978881 BedienDisp_hfs_01_BZ 1;
BA_ "GenSigSwitchedByIgnition" SG_ 2463978881 BedienDisp_hfs_01_BZ 0;
BA_ "GenSigSendType" SG_ 2463978881 BedienDisp_hfs_01_CRC 0;
BA_ "GenSigFuncType" SG_ 2463978881 BedienDisp_hfs_01_CRC 2;
BA_ "GenSigSwitchedByIgnition" SG_ 2463978881 BedienDisp_hfs_01_CRC 0;
BA_ "GenSigSendType" SG_ 2463978881 BedienDisp_hfs_control_vol 4;
BA_ "GenSigSwitchedByIgnition" SG_ 2463978881 BedienDisp_hfs_control_vol 0;
BA_ "Fehlerwert" SG_ 2463978881 BedienDisp_hfs_control_vol 15;
BA_ "GenSigSendType" SG_ 2463978881 BedienDisp_hfs_control_vol_02 4;
BA_ "GenSigStartValue" SG_ 2463978881 BedienDisp_hfs_control_vol_02 126;
BA_ "GenSigSwitchedByIgnition" SG_ 2463978881 BedienDisp_hfs_control_vol_02 0;
BA_ "Fehlerwert" SG_ 2463978881 BedienDisp_hfs_control_vol_02 127;
BA_ "GenSigSendType" SG_ 2463978881 BedienDisp_hfs_fader 4;
BA_ "GenSigSwitchedByIgnition" SG_ 2463978881 BedienDisp_hfs_fader 0;
BA_ "Fehlerwert" SG_ 2463978881 BedienDisp_hfs_fader 15;
BA_ "GenSigSendType" SG_ 2463978881 BedienDisp_hfs_Lordose_hoch 4;
BA_ "GenSigSwitchedByIgnition" SG_ 2463978881 BedienDisp_hfs_Lordose_hoch 0;
BA_ "GenSigSendType" SG_ 2463978881 BedienDisp_hfs_Lordose_runter 4;
BA_ "GenSigSwitchedByIgnition" SG_ 2463978881 BedienDisp_hfs_Lordose_runter 0;
BA_ "GenSigSendType" SG_ 2463978881 BedienDisp_hfs_Lordose_vor 4;
BA_ "GenSigSwitchedByIgnition" SG_ 2463978881 BedienDisp_hfs_Lordose_vor 0;
BA_ "GenSigSendType" SG_ 2463978881 BedienDisp_hfs_Lordose_zurueck 4;
BA_ "GenSigSwitchedByIgnition" SG_ 2463978881 BedienDisp_hfs_Lordose_zurueck 0;
BA_ "GenSigSendType" SG_ 2463978881 BedienDisp_hfs_sound 4;
BA_ "GenSigSwitchedByIgnition" SG_ 2463978881 BedienDisp_hfs_sound 0;
BA_ "GenSigSendType" SG_ 2463978881 BedienDisp_hfs_sound_fokus 4;
BA_ "GenSigSwitchedByIgnition" SG_ 2463978881 BedienDisp_hfs_sound_fokus 0;
BA_ "Fehlerwert" SG_ 2463978881 BedienDisp_hfs_sound_fokus 15;
BA_ "GenSigSendType" SG_ 2463978881 BedienDisp_hfs_surround 4;
BA_ "GenSigSwitchedByIgnition" SG_ 2463978881 BedienDisp_hfs_surround 0;
BA_ "Fehlerwert" SG_ 2463978881 BedienDisp_hfs_surround 15;
BA_ "GenSigSendType" SG_ 2463978881 BedienDisp_hfs_surround_02 4;
BA_ "Fehlerwert" SG_ 2463978881 BedienDisp_hfs_surround_02 127;
BA_ "GenSigSendType" SG_ 2463978881 BedienDisp_hfs_touch 4;
BA_ "GenSigSwitchedByIgnition" SG_ 2463978881 BedienDisp_hfs_touch 0;
BA_ "Fehlerwert" SG_ 2463978881 BedienDisp_hfs_touch 15;
BA_ "GenSigSendType" SG_ 2463978881 BedienDisp_hfs_UseCase_Pos 3;
BA_ "GenSigSwitchedByIgnition" SG_ 2463978881 BedienDisp_hfs_UseCase_Pos 0;
BA_ "GenSigSendType" SG_ 2463978881 BedienDisp_HFSFo_Bestaetigung 3;
BA_ "GenSigSwitchedByIgnition" SG_ 2463978881 BedienDisp_HFSFo_Bestaetigung 0;
BA_ "Fehlerwert" SG_ 2463978881 BedienDisp_HFSFo_Bestaetigung 3;
BA_ "GenSigSendType" SG_ 2463978881 BedienDisp_HFSFo_Stoerung 3;
BA_ "GenSigSwitchedByIgnition" SG_ 2463978881 BedienDisp_HFSFo_Stoerung 0;
BA_ "GenSigSendType" SG_ 1635 BEM_Anf_KL15_schalten 0;
BA_ "GenSigSwitchedByIgnition" SG_ 1635 BEM_Anf_KL15_schalten 0;
BA_ "GenSigSendType" SG_ 1635 BEM_Batt_Ab 0;
BA_ "GenSigSwitchedByIgnition" SG_ 1635 BEM_Batt_Ab 0;
BA_ "GenSigSendType" SG_ 1635 BEM_Batteriediagnose 0;
BA_ "GenSigSwitchedByIgnition" SG_ 1635 BEM_Batteriediagnose 0;
BA_ "Fehlerwert" SG_ 1635 BEM_Batteriediagnose 7;
BA_ "GenSigSendType" SG_ 1635 BEM_DFM 0;
BA_ "GenSigSwitchedByIgnition" SG_ 1635 BEM_DFM 0;
BA_ "GenSigSendType" SG_ 1635 BEM_EMLIN_ungueltig 0;
BA_ "GenSigSwitchedByIgnition" SG_ 1635 BEM_EMLIN_ungueltig 0;
BA_ "GenSigSendType" SG_ 1635 BEM_Generatordiagnose 0;
BA_ "GenSigSwitchedByIgnition" SG_ 1635 BEM_Generatordiagnose 0;
BA_ "GenSigSendType" SG_ 1635 BEM_HL_Kontingentierung 0;
BA_ "GenSigSwitchedByIgnition" SG_ 1635 BEM_HL_Kontingentierung 0;
BA_ "GenSigSendType" SG_ 1635 BEM_HL_Regelung_Status 0;
BA_ "GenSigSwitchedByIgnition" SG_ 1635 BEM_HL_Regelung_Status 0;
BA_ "GenSigSendType" SG_ 1635 BEM_Ladezustand 0;
BA_ "GenSigStartValue" SG_ 1635 BEM_Ladezustand 14;
BA_ "GenSigSwitchedByIgnition" SG_ 1635 BEM_Ladezustand 0;
BA_ "Fehlerwert" SG_ 1635 BEM_Ladezustand 15;
BA_ "GenSigSendType" SG_ 1635 BEM_MMI_Vorwarnung 0;
BA_ "GenSigSwitchedByIgnition" SG_ 1635 BEM_MMI_Vorwarnung 0;
BA_ "GenSigSendType" SG_ 1635 BEM_Red_Innengeblaese 0;
BA_ "GenSigSwitchedByIgnition" SG_ 1635 BEM_Red_Innengeblaese 0;
BA_ "GenSigSendType" SG_ 1635 BEM_REK_aktiv 0;
BA_ "GenSigSwitchedByIgnition" SG_ 1635 BEM_REK_aktiv 0;
BA_ "GenSigSendType" SG_ 1635 BEM_STH_Einschaltverbot 0;
BA_ "GenSigSwitchedByIgnition" SG_ 1635 BEM_STH_Einschaltverbot 0;
BA_ "GenSigSendType" SG_ 1635 BEM_STH_Zielzeit 0;
BA_ "GenSigStartValue" SG_ 1635 BEM_STH_Zielzeit 14;
BA_ "GenSigSwitchedByIgnition" SG_ 1635 BEM_STH_Zielzeit 0;
BA_ "Fehlerwert" SG_ 1635 BEM_STH_Zielzeit 15;
BA_ "GenSigSendType" SG_ 1635 BEM_UBDM 0;
BA_ "GenSigSwitchedByIgnition" SG_ 1635 BEM_UBDM 0;
BA_ "Fehlerwert" SG_ 1635 BEM_UBDM 255;
BA_ "GenSigSendType" SG_ 1635 BEM_UGenSoll 0;
BA_ "GenSigSwitchedByIgnition" SG_ 1635 BEM_UGenSoll 0;
BA_ "GenSigSendType" SG_ 1635 MIB_Stromsparmodus 0;
BA_ "GenSigSwitchedByIgnition" SG_ 1635 MIB_Stromsparmodus 0;
BA_ "GenSigSendType" SG_ 1635 NVEM_Abschaltstufe 0;
BA_ "GenSigSwitchedByIgnition" SG_ 1635 NVEM_Abschaltstufe 0;
BA_ "GenSigSendType" SG_ 1635 NVEM_Anf_SD_schalten 0;
BA_ "GenSigSwitchedByIgnition" SG_ 1635 NVEM_Anf_SD_schalten 0;
BA_ "GenSigSendType" SG_ 1635 NVEM_Batterie_Service 0;
BA_ "GenSigSwitchedByIgnition" SG_ 1635 NVEM_Batterie_Service 0;
BA_ "GenSigSendType" SG_ 1635 NVEM_Freigabe_OnlineUpdate 0;
BA_ "GenSigSwitchedByIgnition" SG_ 1635 NVEM_Freigabe_OnlineUpdate 0;
BA_ "GenSigSendType" SG_ 1635 NVEM_Freigabe_ORU4 0;
BA_ "GenSigSwitchedByIgnition" SG_ 1635 NVEM_Freigabe_ORU4 0;
BA_ "GenSigSendType" SG_ 1635 NVEM_Freigabe_ZusBatt_Laden 0;
BA_ "GenSigSwitchedByIgnition" SG_ 1635 NVEM_Freigabe_ZusBatt_Laden 0;
BA_ "GenSigSendType" SG_ 1635 NVEM_Verbraucherabsch_Anz 0;
BA_ "GenSigSwitchedByIgnition" SG_ 1635 NVEM_Verbraucherabsch_Anz 0;
BA_ "GenSigSendType" SG_ 1163 BEM_06_BZ 0;
BA_ "GenSigFuncType" SG_ 1163 BEM_06_BZ 1;
BA_ "GenSigSwitchedByIgnition" SG_ 1163 BEM_06_BZ 0;
BA_ "GenSigSendType" SG_ 1163 BEM_06_CRC 0;
BA_ "GenSigFuncType" SG_ 1163 BEM_06_CRC 2;
BA_ "GenSigSwitchedByIgnition" SG_ 1163 BEM_06_CRC 0;
BA_ "GenSigSendType" SG_ 1163 HLR_PTC_linear_Freigabe 0;
BA_ "GenSigSwitchedByIgnition" SG_ 1163 HLR_PTC_linear_Freigabe 0;
BA_ "Fehlerwert" SG_ 1163 HLR_PTC_linear_Freigabe 63;
BA_ "GenSigSendType" SG_ 1163 NVEM2_Status_FuSiFahrt 0;
BA_ "GenSigSwitchedByIgnition" SG_ 1163 NVEM2_Status_FuSiFahrt 0;
BA_ "Fehlerwert" SG_ 1163 NVEM2_Status_FuSiFahrt 7;
BA_ "GenSigSendType" SG_ 1163 NVEM2_Typ_EnergieNetz 0;
BA_ "GenSigStartValue" SG_ 1163 NVEM2_Typ_EnergieNetz 15;
BA_ "GenSigSwitchedByIgnition" SG_ 1163 NVEM2_Typ_EnergieNetz 0;
BA_ "Fehlerwert" SG_ 1163 NVEM2_Typ_EnergieNetz 14;
BA_ "GenSigSendType" SG_ 1163 NVEM_Betriebsart 0;
BA_ "GenSigSwitchedByIgnition" SG_ 1163 NVEM_Betriebsart 0;
BA_ "Fehlerwert" SG_ 1163 NVEM_Betriebsart 15;
BA_ "GenSigSendType" SG_ 1163 NVEM_Bordnetzdiagnose 0;
BA_ "GenSigSwitchedByIgnition" SG_ 1163 NVEM_Bordnetzdiagnose 0;
BA_ "GenSigSendType" SG_ 1163 NVEM_Energie_Klima_Vorgabe 0;
BA_ "GenSigStartValue" SG_ 1163 NVEM_Energie_Klima_Vorgabe 254;
BA_ "GenSigSwitchedByIgnition" SG_ 1163 NVEM_Energie_Klima_Vorgabe 0;
BA_ "Fehlerwert" SG_ 1163 NVEM_Energie_Klima_Vorgabe 255;
BA_ "GenSigSendType" SG_ 1163 NVEM_Energienetz_Status 0;
BA_ "GenSigStartValue" SG_ 1163 NVEM_Energienetz_Status 6;
BA_ "GenSigSwitchedByIgnition" SG_ 1163 NVEM_Energienetz_Status 0;
BA_ "Fehlerwert" SG_ 1163 NVEM_Energienetz_Status 7;
BA_ "GenSigSendType" SG_ 1163 NVEM_Ladezustand 0;
BA_ "GenSigStartValue" SG_ 1163 NVEM_Ladezustand 126;
BA_ "GenSigSwitchedByIgnition" SG_ 1163 NVEM_Ladezustand 0;
BA_ "Fehlerwert" SG_ 1163 NVEM_Ladezustand 127;
BA_ "GenSigSendType" SG_ 1163 NVEM_Last_Anf 0;
BA_ "GenSigSwitchedByIgnition" SG_ 1163 NVEM_Last_Anf 0;
BA_ "GenSigSendType" SG_ 1163 NVEM_PTC_Sollstufe 0;
BA_ "GenSigSwitchedByIgnition" SG_ 1163 NVEM_PTC_Sollstufe 0;
BA_ "GenSigSendType" SG_ 1163 NVEM_Red_KomfortVerbrauch 0;
BA_ "GenSigSwitchedByIgnition" SG_ 1163 NVEM_Red_KomfortVerbrauch 0;
BA_ "Fehlerwert" SG_ 1163 NVEM_Red_KomfortVerbrauch 15;
BA_ "GenSigSendType" SG_ 1163 NVEM_STH_ZielzeitLang 0;
BA_ "GenSigStartValue" SG_ 1163 NVEM_STH_ZielzeitLang 14;
BA_ "GenSigSwitchedByIgnition" SG_ 1163 NVEM_STH_ZielzeitLang 0;
BA_ "Fehlerwert" SG_ 1163 NVEM_STH_ZielzeitLang 15;
BA_ "GenSigSendType" SG_ 1163 NVEM_Vorgabe_Leistungsstufe 0;
BA_ "GenSigSwitchedByIgnition" SG_ 1163 NVEM_Vorgabe_Leistungsstufe 0;
BA_ "Fehlerwert" SG_ 1163 NVEM_Vorgabe_Leistungsstufe 7;
BA_ "GenSigSendType" SG_ 2463978850 BEM_07_BZ 0;
BA_ "GenSigFuncType" SG_ 2463978850 BEM_07_BZ 1;
BA_ "GenSigSwitchedByIgnition" SG_ 2463978850 BEM_07_BZ 0;
BA_ "GenSigSendType" SG_ 2463978850 BEM_07_CRC 0;
BA_ "GenSigFuncType" SG_ 2463978850 BEM_07_CRC 2;
BA_ "GenSigSwitchedByIgnition" SG_ 2463978850 BEM_07_CRC 0;
BA_ "GenSigSendType" SG_ 2463978850 NVEM2_VerbrZustandsAnf 0;
BA_ "GenSigStartValue" SG_ 2463978850 NVEM2_VerbrZustandsAnf 14;
BA_ "GenSigSwitchedByIgnition" SG_ 2463978850 NVEM2_VerbrZustandsAnf 0;
BA_ "Fehlerwert" SG_ 2463978850 NVEM2_VerbrZustandsAnf 15;
BA_ "GenSigSendType" SG_ 2463978850 NVEM3_Absch_SCR 0;
BA_ "GenSigSwitchedByIgnition" SG_ 2463978850 NVEM3_Absch_SCR 0;
BA_ "GenSigSendType" SG_ 2463978850 NVEM_Batt_Temp_Hinweis 0;
BA_ "GenSigSwitchedByIgnition" SG_ 2463978850 NVEM_Batt_Temp_Hinweis 0;
BA_ "GenSigSendType" SG_ 2463978850 NVEM_Bordnetz_Information 0;
BA_ "GenSigStartValue" SG_ 2463978850 NVEM_Bordnetz_Information 14;
BA_ "GenSigSwitchedByIgnition" SG_ 2463978850 NVEM_Bordnetz_Information 0;
BA_ "Fehlerwert" SG_ 2463978850 NVEM_Bordnetz_Information 15;
BA_ "GenSigSendType" SG_ 2463978850 NVEM_NVStuetzungAnf 0;
BA_ "GenSigSwitchedByIgnition" SG_ 2463978850 NVEM_NVStuetzungAnf 0;
BA_ "Fehlerwert" SG_ 2463978850 NVEM_NVStuetzungAnf 3;
BA_ "GenSigSendType" SG_ 2463978850 NVEM_Verbraucher_Information 0;
BA_ "GenSigStartValue" SG_ 2463978850 NVEM_Verbraucher_Information 6;
BA_ "GenSigSwitchedByIgnition" SG_ 2463978850 NVEM_Verbraucher_Information 0;
BA_ "Fehlerwert" SG_ 2463978850 NVEM_Verbraucher_Information 7;
BA_ "GenSigSendType" SG_ 870 Blinken_li_Fzg_Takt 4;
BA_ "GenSigSwitchedByIgnition" SG_ 870 Blinken_li_Fzg_Takt 0;
BA_ "GenSigSendType" SG_ 870 Blinken_li_Kombi_Takt 4;
BA_ "GenSigSwitchedByIgnition" SG_ 870 Blinken_li_Kombi_Takt 0;
BA_ "GenSigSendType" SG_ 870 Blinken_re_Fzg_Takt 4;
BA_ "GenSigSwitchedByIgnition" SG_ 870 Blinken_re_Fzg_Takt 0;
BA_ "GenSigSendType" SG_ 870 Blinken_re_Kombi_Takt 4;
BA_ "GenSigSwitchedByIgnition" SG_ 870 Blinken_re_Kombi_Takt 0;
BA_ "GenSigSendType" SG_ 870 Blinkmodi_02_BZ 0;
BA_ "GenSigFuncType" SG_ 870 Blinkmodi_02_BZ 1;
BA_ "GenSigSwitchedByIgnition" SG_ 870 Blinkmodi_02_BZ 0;
BA_ "GenSigSendType" SG_ 870 Blinkmodi_02_CRC 0;
BA_ "GenSigFuncType" SG_ 870 Blinkmodi_02_CRC 2;
BA_ "GenSigSwitchedByIgnition" SG_ 870 Blinkmodi_02_CRC 0;
BA_ "GenSigSendType" SG_ 870 BM_Autobahn 4;
BA_ "GenSigSwitchedByIgnition" SG_ 870 BM_Autobahn 0;
BA_ "GenSigSendType" SG_ 870 BM_Crash 4;
BA_ "GenSigSwitchedByIgnition" SG_ 870 BM_Crash 0;
BA_ "GenSigSendType" SG_ 870 BM_DWA_Alarm 4;
BA_ "GenSigSwitchedByIgnition" SG_ 870 BM_DWA_Alarm 0;
BA_ "GenSigSendType" SG_ 870 BM_DWA_ein 4;
BA_ "GenSigSwitchedByIgnition" SG_ 870 BM_DWA_ein 0;
BA_ "GenSigSendType" SG_ 870 BM_GDO 4;
BA_ "GenSigSwitchedByIgnition" SG_ 870 BM_GDO 0;
BA_ "GenSigSendType" SG_ 870 BM_HD_Oeffnung_angelernt 3;
BA_ "GenSigSwitchedByIgnition" SG_ 870 BM_HD_Oeffnung_angelernt 0;
BA_ "GenSigSendType" SG_ 870 BM_links 4;
BA_ "GenSigSwitchedByIgnition" SG_ 870 BM_links 0;
BA_ "GenSigSendType" SG_ 870 BM_NBA_n_codiert_n_aktiv 3;
BA_ "GenSigStartValue" SG_ 870 BM_NBA_n_codiert_n_aktiv 1;
BA_ "GenSigSwitchedByIgnition" SG_ 870 BM_NBA_n_codiert_n_aktiv 0;
BA_ "GenSigSendType" SG_ 870 BM_NBA_Status 4;
BA_ "GenSigSwitchedByIgnition" SG_ 870 BM_NBA_Status 0;
BA_ "GenSigSendType" SG_ 870 BM_Not_Bremsung 4;
BA_ "GenSigSwitchedByIgnition" SG_ 870 BM_Not_Bremsung 0;
BA_ "GenSigSendType" SG_ 870 BM_Panik 4;
BA_ "GenSigSwitchedByIgnition" SG_ 870 BM_Panik 0;
BA_ "GenSigSendType" SG_ 870 BM_PiloPa 4;
BA_ "GenSigSwitchedByIgnition" SG_ 870 BM_PiloPa 0;
BA_ "GenSigSendType" SG_ 870 BM_Recas 5;
BA_ "GenSigSwitchedByIgnition" SG_ 870 BM_Recas 0;
BA_ "GenSigSendType" SG_ 870 BM_rechts 4;
BA_ "GenSigSwitchedByIgnition" SG_ 870 BM_rechts 0;
BA_ "GenSigSendType" SG_ 870 BM_Rollenmodus_Blinken 5;
BA_ "GenSigSwitchedByIgnition" SG_ 870 BM_Rollenmodus_Blinken 0;
BA_ "GenSigSendType" SG_ 870 BM_Taxi_Notalarm 4;
BA_ "GenSigSwitchedByIgnition" SG_ 870 BM_Taxi_Notalarm 0;
BA_ "GenSigSendType" SG_ 870 BM_Telematik 4;
BA_ "GenSigSwitchedByIgnition" SG_ 870 BM_Telematik 0;
BA_ "GenSigSendType" SG_ 870 BM_Telematik_Abbruchgrund 4;
BA_ "GenSigSwitchedByIgnition" SG_ 870 BM_Telematik_Abbruchgrund 0;
BA_ "GenSigSendType" SG_ 870 BM_Warnblinken 4;
BA_ "GenSigSwitchedByIgnition" SG_ 870 BM_Warnblinken 0;
BA_ "GenSigSendType" SG_ 870 BM_WBA_Warnblinken 4;
BA_ "GenSigSwitchedByIgnition" SG_ 870 BM_WBA_Warnblinken 0;
BA_ "GenSigSendType" SG_ 870 BM_WBT_Beleuchtung 3;
BA_ "GenSigSwitchedByIgnition" SG_ 870 BM_WBT_Beleuchtung 0;
BA_ "GenSigSendType" SG_ 870 BM_Wischblinken 4;
BA_ "GenSigSwitchedByIgnition" SG_ 870 BM_Wischblinken 0;
BA_ "GenSigSendType" SG_ 870 BM_ZV_auf 4;
BA_ "GenSigSwitchedByIgnition" SG_ 870 BM_ZV_auf 0;
BA_ "GenSigSendType" SG_ 870 BM_ZV_zu 4;
BA_ "GenSigSwitchedByIgnition" SG_ 870 BM_ZV_zu 0;
BA_ "GenSigSendType" SG_ 870 SAL_RHP_Blinken_Status 3;
BA_ "GenSigSwitchedByIgnition" SG_ 870 SAL_RHP_Blinken_Status 0;
BA_ "GenSigSendType" SG_ 870 SAL_RHP_Warnblinken 3;
BA_ "GenSigSwitchedByIgnition" SG_ 870 SAL_RHP_Warnblinken 0;
BA_ "GenSigSendType" SG_ 870 SAL_TA_Blinken_Status 4;
BA_ "GenSigSwitchedByIgnition" SG_ 870 SAL_TA_Blinken_Status 0;
BA_ "GenSigSendType" SG_ 687 BMC_Spannung 0;
BA_ "GenSigStartValue" SG_ 687 BMC_Spannung 16382;
BA_ "GenSigSwitchedByIgnition" SG_ 687 BMC_Spannung 0;
BA_ "Fehlerwert" SG_ 687 BMC_Spannung 16383;
BA_ "GenSigSendType" SG_ 687 BMS_As_Entladezaehler 0;
BA_ "GenSigSwitchedByIgnition" SG_ 687 BMS_As_Entladezaehler 0;
BA_ "GenSigSendType" SG_ 687 BMS_As_Entladezaehler_Ueberlauf 0;
BA_ "GenSigSwitchedByIgnition" SG_ 687 BMS_As_Entladezaehler_Ueberlauf 0;
BA_ "GenSigSendType" SG_ 687 BMS_Rekuperation 0;
BA_ "GenSigSwitchedByIgnition" SG_ 687 BMS_Rekuperation 0;
BA_ "GenSigSendType" SG_ 687 BMS_Rekuperation_Ueberlauf 0;
BA_ "GenSigSwitchedByIgnition" SG_ 687 BMS_Rekuperation_Ueberlauf 0;
BA_ "GenSigSendType" SG_ 687 BMS_Verbrauch 0;
BA_ "GenSigSwitchedByIgnition" SG_ 687 BMS_Verbrauch 0;
BA_ "GenSigSendType" SG_ 687 BMS_Verbrauch_Ueberlauf 0;
BA_ "GenSigSwitchedByIgnition" SG_ 687 BMS_Verbrauch_Ueberlauf 0;
BA_ "GenSigSendType" SG_ 1482 BMS_07_BZ 0;
BA_ "GenSigFuncType" SG_ 1482 BMS_07_BZ 1;
BA_ "GenSigSwitchedByIgnition" SG_ 1482 BMS_07_BZ 0;
BA_ "GenSigSendType" SG_ 1482 BMS_07_CRC 0;
BA_ "GenSigFuncType" SG_ 1482 BMS_07_CRC 2;
BA_ "GenSigSwitchedByIgnition" SG_ 1482 BMS_07_CRC 0;
BA_ "GenSigSendType" SG_ 1482 BMS_Ausgleichsladung_Anf 0;
BA_ "GenSigSwitchedByIgnition" SG_ 1482 BMS_Ausgleichsladung_Anf 0;
BA_ "GenSigSendType" SG_ 1482 BMS_Balancing_Aktiv 0;
BA_ "GenSigSwitchedByIgnition" SG_ 1482 BMS_Balancing_Aktiv 0;
BA_ "GenSigSendType" SG_ 1482 BMS_Batteriediagnose 3;
BA_ "GenSigStartValue" SG_ 1482 BMS_Batteriediagnose 1;
BA_ "GenSigSwitchedByIgnition" SG_ 1482 BMS_Batteriediagnose 0;
BA_ "Fehlerwert" SG_ 1482 BMS_Batteriediagnose 7;
BA_ "GenSigSendType" SG_ 1482 BMS_Energieinhalt 0;
BA_ "GenSigStartValue" SG_ 1482 BMS_Energieinhalt 2046;
BA_ "GenSigSwitchedByIgnition" SG_ 1482 BMS_Energieinhalt 0;
BA_ "Fehlerwert" SG_ 1482 BMS_Energieinhalt 2047;
BA_ "GenSigSendType" SG_ 1482 BMS_Gesamtst_Spgfreiheit 3;
BA_ "GenSigSwitchedByIgnition" SG_ 1482 BMS_Gesamtst_Spgfreiheit 0;
BA_ "GenSigSendType" SG_ 1482 BMS_KundenWarnung 3;
BA_ "GenSigSwitchedByIgnition" SG_ 1482 BMS_KundenWarnung 0;
BA_ "GenSigSendType" SG_ 1482 BMS_Ladevorgang_aktiv 0;
BA_ "GenSigSwitchedByIgnition" SG_ 1482 BMS_Ladevorgang_aktiv 0;
BA_ "GenSigSendType" SG_ 1482 BMS_MaxEnergieinhalt 0;
BA_ "GenSigStartValue" SG_ 1482 BMS_MaxEnergieinhalt 2046;
BA_ "GenSigSwitchedByIgnition" SG_ 1482 BMS_MaxEnergieinhalt 0;
BA_ "Fehlerwert" SG_ 1482 BMS_MaxEnergieinhalt 2047;
BA_ "GenSigSendType" SG_ 1482 BMS_RIso_Ext 0;
BA_ "GenSigStartValue" SG_ 1482 BMS_RIso_Ext 4094;
BA_ "GenSigSwitchedByIgnition" SG_ 1482 BMS_RIso_Ext 0;
BA_ "Fehlerwert" SG_ 1482 BMS_RIso_Ext 4095;
BA_ "GenSigSendType" SG_ 2589283664 BMS_Balancing_Aktiv 0;
BA_ "GenSigSwitchedByIgnition" SG_ 2589283664 BMS_Balancing_Aktiv 0;
BA_ "GenSigSendType" SG_ 2589283664 BMS_Ladevorgang_aktiv 0;
BA_ "GenSigSwitchedByIgnition" SG_ 2589283664 BMS_Ladevorgang_aktiv 0;
BA_ "GenSigSendType" SG_ 2589283664 BMS_Max_Energie 0;
BA_ "GenSigStartValue" SG_ 2589283664 BMS_Max_Energie 8190;
BA_ "GenSigSwitchedByIgnition" SG_ 2589283664 BMS_Max_Energie 0;
BA_ "GenSigSendType" SG_ 2589283664 BMS_Max_Ladezustand 0;
BA_ "GenSigStartValue" SG_ 2589283664 BMS_Max_Ladezustand 2046;
BA_ "GenSigSwitchedByIgnition" SG_ 2589283664 BMS_Max_Ladezustand 0;
BA_ "GenSigSendType" SG_ 2589283664 BMS_Min_Ladezustand 0;
BA_ "GenSigStartValue" SG_ 2589283664 BMS_Min_Ladezustand 2046;
BA_ "GenSigSwitchedByIgnition" SG_ 2589283664 BMS_Min_Ladezustand 0;
BA_ "GenSigSendType" SG_ 2589283664 BMS_RIso_Ext 0;
BA_ "GenSigStartValue" SG_ 2589283664 BMS_RIso_Ext 4094;
BA_ "GenSigSwitchedByIgnition" SG_ 2589283664 BMS_RIso_Ext 0;
BA_ "Fehlerwert" SG_ 2589283664 BMS_RIso_Ext 4095;
BA_ "GenSigSendType" SG_ 2589283665 BMS_BattHeizung_VerbautStatus 0;
BA_ "GenSigSwitchedByIgnition" SG_ 2589283665 BMS_BattHeizung_VerbautStatus 0;
BA_ "GenSigSendType" SG_ 2589283665 BMS_Fehler_NTKreis 0;
BA_ "GenSigSwitchedByIgnition" SG_ 2589283665 BMS_Fehler_NTKreis 0;
BA_ "Fehlerwert" SG_ 2589283665 BMS_Fehler_NTKreis 1;
BA_ "GenSigSendType" SG_ 2589283665 BMS_Pumpe1_Ansteuerung 0;
BA_ "GenSigStartValue" SG_ 2589283665 BMS_Pumpe1_Ansteuerung 14;
BA_ "GenSigSwitchedByIgnition" SG_ 2589283665 BMS_Pumpe1_Ansteuerung 0;
BA_ "Fehlerwert" SG_ 2589283665 BMS_Pumpe1_Ansteuerung 15;
BA_ "GenSigSendType" SG_ 2589283665 BMS_Pumpe2_Ansteuerung 0;
BA_ "GenSigStartValue" SG_ 2589283665 BMS_Pumpe2_Ansteuerung 14;
BA_ "GenSigSwitchedByIgnition" SG_ 2589283665 BMS_Pumpe2_Ansteuerung 0;
BA_ "Fehlerwert" SG_ 2589283665 BMS_Pumpe2_Ansteuerung 15;
BA_ "GenSigSendType" SG_ 2589283665 BMS_RuecklaufTemperatur 0;
BA_ "GenSigStartValue" SG_ 2589283665 BMS_RuecklaufTemperatur 254;
BA_ "GenSigSwitchedByIgnition" SG_ 2589283665 BMS_RuecklaufTemperatur 0;
BA_ "Fehlerwert" SG_ 2589283665 BMS_RuecklaufTemperatur 255;
BA_ "GenSigSendType" SG_ 2589283665 BMS_SollVorlauftemperatur 0;
BA_ "GenSigStartValue" SG_ 2589283665 BMS_SollVorlauftemperatur 254;
BA_ "GenSigSwitchedByIgnition" SG_ 2589283665 BMS_SollVorlauftemperatur 0;
BA_ "Fehlerwert" SG_ 2589283665 BMS_SollVorlauftemperatur 255;
BA_ "GenSigSendType" SG_ 2589283665 BMS_Status_Ventil1 0;
BA_ "GenSigStartValue" SG_ 2589283665 BMS_Status_Ventil1 6;
BA_ "GenSigSwitchedByIgnition" SG_ 2589283665 BMS_Status_Ventil1 0;
BA_ "Fehlerwert" SG_ 2589283665 BMS_Status_Ventil1 7;
BA_ "GenSigSendType" SG_ 2589283665 BMS_Status_Ventil2 0;
BA_ "GenSigStartValue" SG_ 2589283665 BMS_Status_Ventil2 6;
BA_ "GenSigSwitchedByIgnition" SG_ 2589283665 BMS_Status_Ventil2 0;
BA_ "Fehlerwert" SG_ 2589283665 BMS_Status_Ventil2 7;
BA_ "GenSigSendType" SG_ 2589283665 BMS_Temperatur 0;
BA_ "GenSigStartValue" SG_ 2589283665 BMS_Temperatur 254;
BA_ "GenSigSwitchedByIgnition" SG_ 2589283665 BMS_Temperatur 0;
BA_ "Fehlerwert" SG_ 2589283665 BMS_Temperatur 255;
BA_ "GenSigSendType" SG_ 2589283665 BMS_Temperierung_Anf 0;
BA_ "GenSigStartValue" SG_ 2589283665 BMS_Temperierung_Anf 3;
BA_ "GenSigSwitchedByIgnition" SG_ 2589283665 BMS_Temperierung_Anf 0;
BA_ "GenSigSendType" SG_ 2589283665 BMS_VorlaufTemperatur 0;
BA_ "GenSigStartValue" SG_ 2589283665 BMS_VorlaufTemperatur 254;
BA_ "GenSigSwitchedByIgnition" SG_ 2589283665 BMS_VorlaufTemperatur 0;
BA_ "Fehlerwert" SG_ 2589283665 BMS_VorlaufTemperatur 255;
BA_ "GenSigSendType" SG_ 2331595856 BMS_DC_Ladeschuetze_Ist 3;
BA_ "GenSigStartValue" SG_ 2331595856 BMS_DC_Ladeschuetze_Ist 6;
BA_ "GenSigSwitchedByIgnition" SG_ 2331595856 BMS_DC_Ladeschuetze_Ist 0;
BA_ "GenSigSendType" SG_ 2331595856 BMS_EnergieVorhalt 0;
BA_ "GenSigStartValue" SG_ 2331595856 BMS_EnergieVorhalt 65534;
BA_ "GenSigSwitchedByIgnition" SG_ 2331595856 BMS_EnergieVorhalt 0;
BA_ "Fehlerwert" SG_ 2331595856 BMS_EnergieVorhalt 65535;
BA_ "GenSigSendType" SG_ 2331595856 BMS_Hauptschuetze_Ist 3;
BA_ "GenSigStartValue" SG_ 2331595856 BMS_Hauptschuetze_Ist 6;
BA_ "GenSigSwitchedByIgnition" SG_ 2331595856 BMS_Hauptschuetze_Ist 0;
BA_ "GenSigSendType" SG_ 2331595856 BMS_Last_Chg_adeq_SOCswing_Day 0;
BA_ "GenSigSwitchedByIgnition" SG_ 2331595856 BMS_Last_Chg_adeq_SOCswing_Day 0;
BA_ "GenSigSendType" SG_ 2331595856 BMS_Last_Chg_adeq_SOCswing_Month 0;
BA_ "GenSigSwitchedByIgnition" SG_ 2331595856 BMS_Last_Chg_adeq_SOCswing_Month 0;
BA_ "GenSigSendType" SG_ 2331595856 BMS_Last_Chg_adeq_SOCswing_Year 0;
BA_ "GenSigSwitchedByIgnition" SG_ 2331595856 BMS_Last_Chg_adeq_SOCswing_Year 0;
BA_ "GenSigSendType" SG_ 2331595856 BMS_Max_UBE 0;
BA_ "GenSigStartValue" SG_ 2331595856 BMS_Max_UBE 65534;
BA_ "GenSigSwitchedByIgnition" SG_ 2331595856 BMS_Max_UBE 0;
BA_ "Fehlerwert" SG_ 2331595856 BMS_Max_UBE 65535;
BA_ "GenSigSendType" SG_ 2331595856 BMS_Nennspannung 0;
BA_ "GenSigStartValue" SG_ 2331595856 BMS_Nennspannung 2046;
BA_ "GenSigSwitchedByIgnition" SG_ 2331595856 BMS_Nennspannung 0;
BA_ "GenSigSendType" SG_ 2331595856 BMS_Range_Indikator 0;
BA_ "GenSigStartValue" SG_ 2331595856 BMS_Range_Indikator 2046;
BA_ "GenSigSwitchedByIgnition" SG_ 2331595856 BMS_Range_Indikator 0;
BA_ "Fehlerwert" SG_ 2331595856 BMS_Range_Indikator 2047;
BA_ "GenSigSendType" SG_ 2331595856 BMS_UBE 0;
BA_ "GenSigStartValue" SG_ 2331595856 BMS_UBE 65534;
BA_ "GenSigSwitchedByIgnition" SG_ 2331595856 BMS_UBE 0;
BA_ "Fehlerwert" SG_ 2331595856 BMS_UBE 65535;
BA_ "GenSigSendType" SG_ 2331595856 BMS_UBE_Indik_last_update_km 0;
BA_ "GenSigStartValue" SG_ 2331595856 BMS_UBE_Indik_last_update_km 1048574;
BA_ "GenSigSwitchedByIgnition" SG_ 2331595856 BMS_UBE_Indik_last_update_km 0;
BA_ "Fehlerwert" SG_ 2331595856 BMS_UBE_Indik_last_update_km 1048575;
BA_ "GenSigSendType" SG_ 2331595856 BMS_UBE_Indikator 0;
BA_ "GenSigStartValue" SG_ 2331595856 BMS_UBE_Indikator 2046;
BA_ "GenSigSwitchedByIgnition" SG_ 2331595856 BMS_UBE_Indikator 0;
BA_ "Fehlerwert" SG_ 2331595856 BMS_UBE_Indikator 2047;
BA_ "GenSigSendType" SG_ 2331595856 BMS_UBE_T 0;
BA_ "GenSigStartValue" SG_ 2331595856 BMS_UBE_T 65534;
BA_ "GenSigSwitchedByIgnition" SG_ 2331595856 BMS_UBE_T 0;
BA_ "Fehlerwert" SG_ 2331595856 BMS_UBE_T 65535;
BA_ "GenSigSendType" SG_ 2331595856 SOK_BMS_34_Signatur 0;
BA_ "GenSigFuncType" SG_ 2331595856 SOK_BMS_34_Signatur 15;
BA_ "GenSigSwitchedByIgnition" SG_ 2331595856 SOK_BMS_34_Signatur 0;
BA_ "GenSigSendType" SG_ 2589283523 BMS_48V_Indc_StChk 0;
BA_ "GenSigStartValue" SG_ 2589283523 BMS_48V_Indc_StChk 1;
BA_ "GenSigSwitchedByIgnition" SG_ 2589283523 BMS_48V_Indc_StChk 0;
BA_ "GenSigSendType" SG_ 2589283523 BMS_48V_Indc_StFail 0;
BA_ "GenSigSwitchedByIgnition" SG_ 2589283523 BMS_48V_Indc_StFail 0;
BA_ "GenSigSendType" SG_ 2589283523 BMS_MV_Dauer_EntladeLeistung 0;
BA_ "GenSigStartValue" SG_ 2589283523 BMS_MV_Dauer_EntladeLeistung 2046;
BA_ "GenSigSwitchedByIgnition" SG_ 2589283523 BMS_MV_Dauer_EntladeLeistung 0;
BA_ "Fehlerwert" SG_ 2589283523 BMS_MV_Dauer_EntladeLeistung 2047;
BA_ "GenSigSendType" SG_ 2589283523 BMS_MV_Dauer_EntladeSpannung 0;
BA_ "GenSigStartValue" SG_ 2589283523 BMS_MV_Dauer_EntladeSpannung 254;
BA_ "GenSigSwitchedByIgnition" SG_ 2589283523 BMS_MV_Dauer_EntladeSpannung 0;
BA_ "Fehlerwert" SG_ 2589283523 BMS_MV_Dauer_EntladeSpannung 255;
BA_ "GenSigSendType" SG_ 2589283523 BMS_MV_Dauer_LadeLeistung 0;
BA_ "GenSigStartValue" SG_ 2589283523 BMS_MV_Dauer_LadeLeistung 2046;
BA_ "GenSigSwitchedByIgnition" SG_ 2589283523 BMS_MV_Dauer_LadeLeistung 0;
BA_ "Fehlerwert" SG_ 2589283523 BMS_MV_Dauer_LadeLeistung 2047;
BA_ "GenSigSendType" SG_ 2589283523 BMS_MV_Dauer_LadeSpannung 0;
BA_ "GenSigStartValue" SG_ 2589283523 BMS_MV_Dauer_LadeSpannung 254;
BA_ "GenSigSwitchedByIgnition" SG_ 2589283523 BMS_MV_Dauer_LadeSpannung 0;
BA_ "Fehlerwert" SG_ 2589283523 BMS_MV_Dauer_LadeSpannung 255;
BA_ "GenSigSendType" SG_ 2589283523 BMS_MV_Dauer_RMS_Strom 0;
BA_ "GenSigStartValue" SG_ 2589283523 BMS_MV_Dauer_RMS_Strom 254;
BA_ "GenSigSwitchedByIgnition" SG_ 2589283523 BMS_MV_Dauer_RMS_Strom 0;
BA_ "Fehlerwert" SG_ 2589283523 BMS_MV_Dauer_RMS_Strom 255;
BA_ "GenSigSendType" SG_ 2589283523 BMS_MV_Kundenwarnung 3;
BA_ "GenSigSwitchedByIgnition" SG_ 2589283523 BMS_MV_Kundenwarnung 0;
BA_ "GenSigSendType" SG_ 2589283523 BMS_MV_OBD_Lampe_Anf 0;
BA_ "GenSigSwitchedByIgnition" SG_ 2589283523 BMS_MV_OBD_Lampe_Anf 0;
BA_ "GenSigSendType" SG_ 2589283523 OBDProtocol_BMS_48V 0;
BA_ "GenSigStartValue" SG_ 2589283523 OBDProtocol_BMS_48V 254;
BA_ "GenSigSwitchedByIgnition" SG_ 2589283523 OBDProtocol_BMS_48V 0;
BA_ "Fehlerwert" SG_ 2589283523 OBDProtocol_BMS_48V 255;
BA_ "GenSigSendType" SG_ 2331596015 BSIS_Anzeigen_links 3;
BA_ "GenSigSendType" SG_ 2331596015 BSIS_LED_Ausgabemodus_links 4;
BA_ "GenSigSendType" SG_ 2331596015 BSIS_LED_Hell_links 0;
BA_ "GenSigStartValue" SG_ 2331596015 BSIS_LED_Hell_links 126;
BA_ "Fehlerwert" SG_ 2331596015 BSIS_LED_Hell_links 127;
BA_ "GenSigSendType" SG_ 2331596016 BSIS_Anzeigen_rechts 3;
BA_ "GenSigSendType" SG_ 2331596016 BSIS_LED_Ausgabemodus_rechts 4;
BA_ "GenSigSendType" SG_ 2331596016 BSIS_LED_Hell_rechts 0;
BA_ "GenSigStartValue" SG_ 2331596016 BSIS_LED_Hell_rechts 126;
BA_ "Fehlerwert" SG_ 2331596016 BSIS_LED_Hell_rechts 127;
BA_ "GenSigSendType" SG_ 902 CHA_Charge_LED 3;
BA_ "GenSigSwitchedByIgnition" SG_ 902 CHA_Charge_LED 0;
BA_ "GenSigSendType" SG_ 902 CHA_Charisma_Taste2_LED 3;
BA_ "GenSigSwitchedByIgnition" SG_ 902 CHA_Charisma_Taste2_LED 0;
BA_ "Fehlerwert" SG_ 902 CHA_Charisma_Taste2_LED 3;
BA_ "GenSigSendType" SG_ 902 CHA_Current_Mode 3;
BA_ "GenSigSwitchedByIgnition" SG_ 902 CHA_Current_Mode 0;
BA_ "GenSigSendType" SG_ 902 CHA_Current_Mode_FPA 3;
BA_ "GenSigSwitchedByIgnition" SG_ 902 CHA_Current_Mode_FPA 0;
BA_ "GenSigSendType" SG_ 902 CHA_Eco_Charisma_LED 3;
BA_ "GenSigSwitchedByIgnition" SG_ 902 CHA_Eco_Charisma_LED 0;
BA_ "GenSigSendType" SG_ 902 CHA_EV_LED 3;
BA_ "GenSigSwitchedByIgnition" SG_ 902 CHA_EV_LED 0;
BA_ "GenSigSendType" SG_ 902 CHA_Fahrer_Umschaltung 3;
BA_ "GenSigSwitchedByIgnition" SG_ 902 CHA_Fahrer_Umschaltung 0;
BA_ "GenSigSendType" SG_ 902 CHA_Kombi_Texte 3;
BA_ "GenSigSwitchedByIgnition" SG_ 902 CHA_Kombi_Texte 0;
BA_ "GenSigSendType" SG_ 902 CHA_Kombi_Texte_02 3;
BA_ "GenSigSwitchedByIgnition" SG_ 902 CHA_Kombi_Texte_02 0;
BA_ "GenSigSendType" SG_ 902 CHA_Offroad_LED 3;
BA_ "GenSigSwitchedByIgnition" SG_ 902 CHA_Offroad_LED 0;
BA_ "Fehlerwert" SG_ 902 CHA_Offroad_LED 3;
BA_ "GenSigSendType" SG_ 902 CHA_ReqPrgDispSetup 3;
BA_ "GenSigSwitchedByIgnition" SG_ 902 CHA_ReqPrgDispSetup 0;
BA_ "GenSigSendType" SG_ 902 CHA_StCurProfDft 3;
BA_ "GenSigSwitchedByIgnition" SG_ 902 CHA_StCurProfDft 0;
BA_ "GenSigSendType" SG_ 902 CHA_Ziel_FahrPr_03_01 3;
BA_ "GenSigSwitchedByIgnition" SG_ 902 CHA_Ziel_FahrPr_03_01 0;
BA_ "GenSigSendType" SG_ 902 CHA_Ziel_FahrPr_03_02 3;
BA_ "GenSigSwitchedByIgnition" SG_ 902 CHA_Ziel_FahrPr_03_02 0;
BA_ "GenSigSendType" SG_ 902 CHA_Ziel_FahrPr_AMB 3;
BA_ "GenSigSwitchedByIgnition" SG_ 902 CHA_Ziel_FahrPr_AMB 0;
BA_ "GenSigSendType" SG_ 902 CHA_Ziel_FahrPr_HSP 3;
BA_ "GenSigSwitchedByIgnition" SG_ 902 CHA_Ziel_FahrPr_HSP 0;
BA_ "GenSigSendType" SG_ 902 CHA_Ziel_FahrPr_IVB 3;
BA_ "GenSigSwitchedByIgnition" SG_ 902 CHA_Ziel_FahrPr_IVB 0;
BA_ "GenSigSendType" SG_ 902 CHA_Ziel_FahrPr_KL 3;
BA_ "GenSigSwitchedByIgnition" SG_ 902 CHA_Ziel_FahrPr_KL 0;
BA_ "GenSigSendType" SG_ 902 CHA_Ziel_FahrPr_RWB 3;
BA_ "GenSigSwitchedByIgnition" SG_ 902 CHA_Ziel_FahrPr_RWB 0;
BA_REL_ "GenSigTimeoutTime" BU_SG_REL_ Gateway_Max SG_ 2536711426 BAP_BatteryControl_ASG_03_Header 800;
BA_REL_ "GenSigTimeoutTime" BU_SG_REL_ Gateway_Max SG_ 2536710912 BAP_BCmE_ASG_01_Header 800;
BA_REL_ "GenSigTimeoutTime" BU_SG_REL_ Gateway_Max SG_ 2536723713 BAP_PaCo_ASG_02_Header 500;
BA_REL_ "GenSigTimeoutTime" BU_SG_REL_ Gateway_Max SG_ 2536723716 BAP_PaCo_ASG_05_Header 500;
BA_REL_ "GenSigTimeoutTime" BU_SG_REL_ Gateway_Max SG_ 2536736001 BAP_SLCView_ASG_02_Header 800;
BA_REL_ "GenSigTimeoutTime" BU_SG_REL_ Gateway_Max SG_ 2536711937 BAP_StartStopReasons_ASG_02_Head 800;
BA_REL_ "GenSigTimeoutTime" BU_SG_REL_ Gateway_Max SG_ 2536706320 BAP_Uhrzeit_FSG_01_Header 5000;
BA_REL_ "GenSigTimeoutTime" BU_SG_REL_ HUD SG_ 2536714512 BAP_Audio_FSG_01_Header 5000;
BA_REL_ "GenSigTimeoutTime" BU_SG_REL_ HUD SG_ 2536714513 BAP_Audio_FSG_02_Header 5000;
BA_REL_ "GenSigTimeoutTime" BU_SG_REL_ HUD SG_ 2536717328 BAP_EfficAssist_FSG_01_Header 5000;
BA_REL_ "GenSigTimeoutTime" BU_SG_REL_ HUD SG_ 2536702976 BAP_HUD_ASG_01_Header 800;
BA_REL_ "GenSigTimeoutTime" BU_SG_REL_ HUD SG_ 2536702977 BAP_HUD_ASG_02_Header 800;
BA_REL_ "GenSigTimeoutTime" BU_SG_REL_ HUD SG_ 2536702978 BAP_HUD_ASG_03_Header 800;
BA_REL_ "GenSigTimeoutTime" BU_SG_REL_ HUD SG_ 2536704016 BAP_Innenlicht_FSG_01_Header 5000;
BA_REL_ "GenSigTimeoutTime" BU_SG_REL_ HUD SG_ 2536714768 BAP_Navigation_FSG_01_Header 5000;
BA_REL_ "GenSigTimeoutTime" BU_SG_REL_ HUD SG_ 2536714769 BAP_Navigation_FSG_02_Header 5000;
BA_REL_ "GenSigTimeoutTime" BU_SG_REL_ HUD SG_ 2536712720 BAP_OnlineFunction_FSG_01_Header 5000;
BA_REL_ "GenSigTimeoutTime" BU_SG_REL_ HUD SG_ 2536704528 BAP_OPS_FSG_01_Header 5000;
BA_REL_ "GenSigTimeoutTime" BU_SG_REL_ HUD SG_ 2536704529 BAP_OPS_FSG_02_Header 5000;
BA_REL_ "GenSigTimeoutTime" BU_SG_REL_ HUD SG_ 2536723728 BAP_PaCo_FSG_01_Header 5000;
BA_REL_ "GenSigTimeoutTime" BU_SG_REL_ HUD SG_ 2536712464 BAP_Telefon2_FSG_01_Header 5000;
BA_REL_ "GenSigTimeoutTime" BU_SG_REL_ HUD SG_ 2536712465 BAP_Telefon2_FSG_02_Header 5000;
BA_REL_ "GenSigTimeoutTime" BU_SG_REL_ HUD SG_ 2536712208 BAP_Telefon_FSG_01_Header 5000;
BA_REL_ "GenSigTimeoutTime" BU_SG_REL_ HUD SG_ 2536712209 BAP_Telefon_FSG_02_Header 5000;
BA_REL_ "GenSigTimeoutTime" BU_SG_REL_ HUD SG_ 2536710416 BAP_VZA_FSG_01_Header 5000;
BA_REL_ "GenSigTimeoutTime" BU_SG_REL_ HUD SG_ 2463978607 BCM_RGB_Rot 2000;
BA_REL_ "GenSigTimeoutTime" BU_SG_REL_ HUD SG_ 2463978607 BCM_RGB_Gruen 2000;
BA_REL_ "GenSigTimeoutTime" BU_SG_REL_ HUD SG_ 2463978607 BCM_RGB_Blau 2000;
BA_REL_ "GenSigTimeoutTime" BU_SG_REL_ HUD SG_ 1635 NVEM_Abschaltstufe 1000;
BA_REL_ "GenSigTimeoutTime" BU_SG_REL_ HUD SG_ 870 Blinken_li_Kombi_Takt 5000;
BA_REL_ "GenSigTimeoutTime" BU_SG_REL_ HUD SG_ 870 Blinken_re_Kombi_Takt 5000;
BA_REL_ "GenSigTimeoutTime" BU_SG_REL_ HUD SG_ 902 CHA_Current_Mode_FPA 5000;
BA_REL_ "GenSigTimeoutTime" BU_SG_REL_ Kombi SG_ 2536714512 BAP_Audio_FSG_01_Header 5000;
BA_REL_ "GenSigTimeoutTime" BU_SG_REL_ Kombi SG_ 2536714513 BAP_Audio_FSG_02_Header 5000;
BA_REL_ "GenSigTimeoutTime" BU_SG_REL_ Kombi SG_ 2536704272 BAP_Aussenlicht_FSG_01_Header 5000;
BA_REL_ "GenSigTimeoutTime" BU_SG_REL_ Kombi SG_ 2536708880 BAP_AWV_FSG_01_Header 5000;
BA_REL_ "GenSigTimeoutTime" BU_SG_REL_ Kombi SG_ 2536711440 BAP_BatteryControl_FSG_01_Header 5000;
BA_REL_ "GenSigTimeoutTime" BU_SG_REL_ Kombi SG_ 2536705792 BAP_BC_ASG_01_Header 800;
BA_REL_ "GenSigTimeoutTime" BU_SG_REL_ Kombi SG_ 2536705793 BAP_BC_ASG_02_Header 800;
BA_REL_ "GenSigTimeoutTime" BU_SG_REL_ Kombi SG_ 2536710928 BAP_BCmE_FSG_01_Header 5000;
BA_REL_ "GenSigTimeoutTime" BU_SG_REL_ Kombi SG_ 2536719616 BAP_DisplayConfig_ASG_01_Header 800;
BA_REL_ "GenSigTimeoutTime" BU_SG_REL_ Kombi SG_ 2536719617 BAP_DisplayConfig_ASG_02_Header 800;
BA_REL_ "GenSigTimeoutTime" BU_SG_REL_ Kombi SG_ 2536705296 BAP_Doorlocking_FSG_01_Header 5000;
BA_REL_ "GenSigTimeoutTime" BU_SG_REL_ Kombi SG_ 2536717328 BAP_EfficAssist_FSG_01_Header 5000;
BA_REL_ "GenSigTimeoutTime" BU_SG_REL_ Kombi SG_ 2536706816 BAP_Einheiten_ASG_01_Header 800;
BA_REL_ "GenSigTimeoutTime" BU_SG_REL_ Kombi SG_ 2536706819 BAP_Einheiten_ASG_04_Header 800;
BA_REL_ "GenSigTimeoutTime" BU_SG_REL_ Kombi SG_ 2536702992 BAP_HUD_FSG_01_Header 5000;
BA_REL_ "GenSigTimeoutTime" BU_SG_REL_ Kombi SG_ 2536709136 BAP_Hybrid_FSG_01_Header 5000;
BA_REL_ "GenSigTimeoutTime" BU_SG_REL_ Kombi SG_ 2536722960 BAP_IAA_PSO_FSG_01_Header 5000;
BA_REL_ "GenSigTimeoutTime" BU_SG_REL_ Kombi SG_ 2536704016 BAP_Innenlicht_FSG_01_Header 5000;
BA_REL_ "GenSigTimeoutTime" BU_SG_REL_ Kombi SG_ 2536708368 BAP_LDW_FSG_01_Header 5000;
BA_REL_ "GenSigTimeoutTime" BU_SG_REL_ Kombi SG_ 2536715280 BAP_MFL_FSG_01_Header 5000;
BA_REL_ "GenSigTimeoutTime" BU_SG_REL_ Kombi SG_ 2536714768 BAP_Navigation_FSG_01_Header 5000;
BA_REL_ "GenSigTimeoutTime" BU_SG_REL_ Kombi SG_ 2536714769 BAP_Navigation_FSG_02_Header 5000;
BA_REL_ "GenSigTimeoutTime" BU_SG_REL_ Kombi SG_ 2536712720 BAP_OnlineFunction_FSG_01_Header 5000;
BA_REL_ "GenSigTimeoutTime" BU_SG_REL_ Kombi SG_ 2536704528 BAP_OPS_FSG_01_Header 5000;
BA_REL_ "GenSigTimeoutTime" BU_SG_REL_ Kombi SG_ 2536704529 BAP_OPS_FSG_02_Header 5000;
BA_REL_ "GenSigTimeoutTime" BU_SG_REL_ Kombi SG_ 2536723728 BAP_PaCo_FSG_01_Header 5000;
BA_REL_ "GenSigTimeoutTime" BU_SG_REL_ Kombi SG_ 2536731152 BAP_RMeasurement_FSG_01_Header 5000;
BA_REL_ "GenSigTimeoutTime" BU_SG_REL_ Kombi SG_ 2536731153 BAP_RMeasurement_FSG_02_Header 5000;
BA_REL_ "GenSigTimeoutTime" BU_SG_REL_ Kombi SG_ 2536703760 BAP_RDK_FSG_01_Header 5000;
BA_REL_ "GenSigTimeoutTime" BU_SG_REL_ Kombi SG_ 2536706560 BAP_SIA_ASG_01_Header 800;
BA_REL_ "GenSigTimeoutTime" BU_SG_REL_ Kombi SG_ 2536706561 BAP_SIA_ASG_02_Header 800;
BA_REL_ "GenSigTimeoutTime" BU_SG_REL_ Kombi SG_ 2536736016 BAP_SLCView_FSG_01_Header 5000;
BA_REL_ "GenSigTimeoutTime" BU_SG_REL_ Kombi SG_ 2536711952 BAP_StartStopReasons_FSG_01_Head 5000;
BA_REL_ "GenSigTimeoutTime" BU_SG_REL_ Kombi SG_ 2536720896 BAP_Statistics_ASG_01_Header 800;
BA_REL_ "GenSigTimeoutTime" BU_SG_REL_ Kombi SG_ 2536708624 BAP_SWA_FSG_01_Header 5000;
BA_REL_ "GenSigTimeoutTime" BU_SG_REL_ Kombi SG_ 2536712464 BAP_Telefon2_FSG_01_Header 5000;
BA_REL_ "GenSigTimeoutTime" BU_SG_REL_ Kombi SG_ 2536712465 BAP_Telefon2_FSG_02_Header 5000;
BA_REL_ "GenSigTimeoutTime" BU_SG_REL_ Kombi SG_ 2536712208 BAP_Telefon_FSG_01_Header 5000;
BA_REL_ "GenSigTimeoutTime" BU_SG_REL_ Kombi SG_ 2536712209 BAP_Telefon_FSG_02_Header 5000;
BA_REL_ "GenSigTimeoutTime" BU_SG_REL_ Kombi SG_ 2536706304 BAP_Uhrzeit_ASG_01_Header 800;
BA_REL_ "GenSigTimeoutTime" BU_SG_REL_ Kombi SG_ 2536706305 BAP_Uhrzeit_ASG_02_Header 800;
BA_REL_ "GenSigTimeoutTime" BU_SG_REL_ Kombi SG_ 2536706308 BAP_Uhrzeit_ASG_05_Header 800;
BA_REL_ "GenSigTimeoutTime" BU_SG_REL_ Kombi SG_ 2536710416 BAP_VZA_FSG_01_Header 5000;
BA_REL_ "GenSigTimeoutTime" BU_SG_REL_ Kombi SG_ 1626 BCM_Bremsbelag_Sensor 5000;
BA_REL_ "GenSigTimeoutTime" BU_SG_REL_ Kombi SG_ 1626 BCM_Bremsfluessigkeit_Sensor 5000;
BA_REL_ "GenSigTimeoutTime" BU_SG_REL_ Kombi SG_ 1626 BCM_Waschwasser_Sensor 5000;
BA_REL_ "GenSigTimeoutTime" BU_SG_REL_ Kombi SG_ 1626 BCM_Kuehlmittel_Sensor 5000;
BA_REL_ "GenSigTimeoutTime" BU_SG_REL_ Kombi SG_ 1626 BCM1_Hinweis_Lichtnachlauf 5000;
BA_REL_ "GenSigTimeoutTime" BU_SG_REL_ Kombi SG_ 1626 BCM1_Warnblink_Taster 5000;
BA_REL_ "GenSigTimeoutTime" BU_SG_REL_ Kombi SG_ 1626 BCM1_MH_Schalter 5000;
BA_REL_ "GenSigTimeoutTime" BU_SG_REL_ Kombi SG_ 1626 BCM1_Lichtwarn_Texte 5000;
BA_REL_ "GenSigTimeoutTime" BU_SG_REL_ Kombi SG_ 1626 Gong_TFL_Umschaltung 5000;
BA_REL_ "GenSigTimeoutTime" BU_SG_REL_ Kombi SG_ 1626 BCM_ValetTaster_Fkts_LED 5000;
BA_REL_ "GenSigTimeoutTime" BU_SG_REL_ Kombi SG_ 1626 BCM_Anf_AAW_MoLaWa 5000;
BA_REL_ "GenSigTimeoutTime" BU_SG_REL_ Kombi SG_ 1626 BCM_Handbremse_Hinweis 5000;
BA_REL_ "GenSigTimeoutTime" BU_SG_REL_ Kombi SG_ 1626 BCM_Waehlhebel_P_Hinweis 5000;
BA_REL_ "GenSigTimeoutTime" BU_SG_REL_ Kombi SG_ 1626 BCM1_Fahrlicht_Hinweis 5000;
BA_REL_ "GenSigTimeoutTime" BU_SG_REL_ Kombi SG_ 2527679637 CPD_Warnung 5000;
BA_REL_ "GenSigTimeoutTime" BU_SG_REL_ Kombi SG_ 2527679637 MiKo_Tisch_Positionswarnung 5000;
BA_REL_ "GenSigTimeoutTime" BU_SG_REL_ Kombi SG_ 2527679637 BCM_anf_VLW 5000;
BA_REL_ "GenSigTimeoutTime" BU_SG_REL_ Kombi SG_ 2527679637 BCM_LTM_Nebelschluss_Status 5000;
BA_REL_ "GenSigTimeoutTime" BU_SG_REL_ Kombi SG_ 2527679637 BCM_LTM_Allwetterl_Status 5000;
BA_REL_ "GenSigTimeoutTime" BU_SG_REL_ Kombi SG_ 2527679637 BCM_LTM_PopUp_Status 5000;
BA_REL_ "GenSigTimeoutTime" BU_SG_REL_ Kombi SG_ 2527679637 BCM_LTM_Nebell_Status 5000;
BA_REL_ "GenSigTimeoutTime" BU_SG_REL_ Kombi SG_ 2527679637 BCM_LTM_PopUp_Anf 5000;
BA_REL_ "GenSigTimeoutTime" BU_SG_REL_ Kombi SG_ 2527679637 BCM_LTM_PopUp_Inhalt 5000;
BA_REL_ "GenSigTimeoutTime" BU_SG_REL_ Kombi SG_ 2463978607 BCM_RGB_Rot 2000;
BA_REL_ "GenSigTimeoutTime" BU_SG_REL_ Kombi SG_ 2463978607 BCM_RGB_Gruen 2000;
BA_REL_ "GenSigTimeoutTime" BU_SG_REL_ Kombi SG_ 2463978607 BCM_RGB_Blau 2000;
BA_REL_ "GenSigTimeoutTime" BU_SG_REL_ Kombi SG_ 2463978882 BedienDisp_hbfs_01_CRC 5000;
BA_REL_ "GenSigTimeoutTime" BU_SG_REL_ Kombi SG_ 2463978882 BedienDisp_hbfs_01_BZ 5000;
BA_REL_ "GenSigTimeoutTime" BU_SG_REL_ Kombi SG_ 2463978882 BedienDisp_HBFSFo_Stoerung 5000;
BA_REL_ "GenSigTimeoutTime" BU_SG_REL_ Kombi SG_ 2463978881 BedienDisp_hfs_01_CRC 5000;
BA_REL_ "GenSigTimeoutTime" BU_SG_REL_ Kombi SG_ 2463978881 BedienDisp_hfs_01_BZ 5000;
BA_REL_ "GenSigTimeoutTime" BU_SG_REL_ Kombi SG_ 2463978881 BedienDisp_HFSFo_Stoerung 5000;
BA_REL_ "GenSigTimeoutTime" BU_SG_REL_ Kombi SG_ 1163 BEM_06_CRC 1000;
BA_REL_ "GenSigTimeoutTime" BU_SG_REL_ Kombi SG_ 1163 BEM_06_BZ 1000;
BA_REL_ "GenSigTimeoutTime" BU_SG_REL_ Kombi SG_ 1163 NVEM_Ladezustand 1000;
BA_REL_ "GenSigTimeoutTime" BU_SG_REL_ Kombi SG_ 1163 NVEM_Bordnetzdiagnose 1000;
BA_REL_ "GenSigTimeoutTime" BU_SG_REL_ Kombi SG_ 2463978850 NVEM_Bordnetz_Information 1000;
BA_REL_ "GenSigTimeoutTime" BU_SG_REL_ Kombi SG_ 2463978850 NVEM_Verbraucher_Information 1000;
BA_REL_ "GenSigTimeoutTime" BU_SG_REL_ Kombi SG_ 2463978850 NVEM_Batt_Temp_Hinweis 1000;
BA_REL_ "GenSigTimeoutTime" BU_SG_REL_ Kombi SG_ 870 BM_Warnblinken 5000;
BA_REL_ "GenSigTimeoutTime" BU_SG_REL_ Kombi SG_ 870 Blinken_li_Kombi_Takt 5000;
BA_REL_ "GenSigTimeoutTime" BU_SG_REL_ Kombi SG_ 870 Blinken_re_Kombi_Takt 5000;
BA_REL_ "GenSigTimeoutTime" BU_SG_REL_ Kombi SG_ 687 BMS_Rekuperation 500;
BA_REL_ "GenSigTimeoutTime" BU_SG_REL_ Kombi SG_ 687 BMS_Rekuperation_Ueberlauf 500;
BA_REL_ "GenSigTimeoutTime" BU_SG_REL_ Kombi SG_ 687 BMS_Verbrauch 500;
BA_REL_ "GenSigTimeoutTime" BU_SG_REL_ Kombi SG_ 687 BMS_Verbrauch_Ueberlauf 500;
BA_REL_ "GenSigTimeoutTime" BU_SG_REL_ Kombi SG_ 1482 BMS_07_CRC 5000;
BA_REL_ "GenSigTimeoutTime" BU_SG_REL_ Kombi SG_ 1482 BMS_07_BZ 5000;
BA_REL_ "GenSigTimeoutTime" BU_SG_REL_ Kombi SG_ 1482 BMS_KundenWarnung 5000;
BA_REL_ "GenSigTimeoutTime" BU_SG_REL_ Kombi SG_ 2589283664 BMS_Ladevorgang_aktiv 5000;
BA_REL_ "GenSigTimeoutTime" BU_SG_REL_ Kombi SG_ 2589283665 BMS_Temperatur 5000;
BA_REL_ "GenSigTimeoutTime" BU_SG_REL_ Kombi SG_ 2331596015 BSIS_Anzeigen_links 5000;
BA_REL_ "GenSigTimeoutTime" BU_SG_REL_ Kombi SG_ 2331596016 BSIS_Anzeigen_rechts 5000;
BA_REL_ "GenSigTimeoutTime" BU_SG_REL_ Kombi SG_ 902 CHA_ReqPrgDispSetup 5000;
BA_REL_ "GenSigTimeoutTime" BU_SG_REL_ Kombi SG_ 902 CHA_Current_Mode_FPA 5000;
BA_REL_ "GenSigTimeoutTime" BU_SG_REL_ Kombi SG_ 902 CHA_Kombi_Texte 5000;
BA_REL_ "GenSigTimeoutTime" BU_SG_REL_ Kombi SG_ 902 CHA_StCurProfDft 5000;
BA_REL_ "GenSigTimeoutTime" BU_SG_REL_ Kombi SG_ 902 CHA_Kombi_Texte_02 5000;
VAL_ 1626 BCM_Bremsbelag_Sensor 0 "OK" 1 "Bremsbelag_unter_min" ;
VAL_ 1626 BCM_Bremsfluessigkeit_Sensor 0 "OK" 1 "Bremsfluessigkeit_unter_min" ;
VAL_ 1626 BCM1_Licht_Warn 0 "OK" 1 "Lichtwarnung_aktiv" ;
VAL_ 1626 BCM_Waschwasser_Sensor 0 "OK" 1 "Waschwasser_unter_min" ;
VAL_ 1626 BCM_Kuehlmittel_Sensor 0 "OK" 1 "Kuehlmittel_unter_min" ;
VAL_ 1626 BCM1_Kl_15_HW_erkannt 1 "Klemme 15 erkannt" ;
VAL_ 1626 BCM1_Kl_15_Sig_HW_erkannt 0 "KL15_HW_Signal_von_BCM1_nicht_erkannt" 1 "KL15_HW_Signal_von_BCM1_erkannt" ;
VAL_ 1626 BCM_Kuehlmittel_Sensor_02 0 "OK" 1 "Kuehlmittel_unter_min" ;
VAL_ 1626 BCM1_Hinweis_Lichtnachlauf 0 "inaktiv" 1 "aktiv" ;
VAL_ 1626 BCM_Offroad_Taste 0 "Taster_nicht_betaetigt" 1 "Taster_betaetigt" ;
VAL_ 1626 BCM_Charisma_Taste2 0 "nicht_betaetigt" 1 "betaetigt" ;
VAL_ 1626 BCM_Hybrid_StSt_Taste_Fehler 0 "kein_Fehler_StSt_Taster" 1 "Fehler_StSt_Taster" ;
VAL_ 1626 BCM_Hybrid_StartStopp_Taste 0 "nicht_betaetigt" 1 "betaetigt" ;
VAL_ 1626 BCM1_Warnblink_Taster 0 "nicht_betaetigt" 1 "betaetigt" ;
VAL_ 1626 BCM1_Valet_Parking_Taster 0 "nicht_betaetigt" 1 "betaetigt" ;
VAL_ 1626 BCM1_LDS_Stellung 0 "Init" 1 "Stellung_0" 2 "Auto" 3 "Standlicht" 4 "Abblendlicht" 7 "Fehler" ;
VAL_ 1626 BCM1_Rueckfahrlicht_Schalter 0 "nicht_betaetigt" 1 "betaetigt" ;
VAL_ 1626 BCM1_MH_Schalter 0 "MH_geschlossen" 1 "MH_offen" ;
VAL_ 1626 BCM1_MH_WIV_Schalter 0 "MH_geschlossen" 1 "MH_offen" ;
VAL_ 1626 BCM_Eco_Charisma_Taste 0 "nicht_betaetigt" 1 "betaetigt" ;
VAL_ 1626 BCM1_NV_Taster 0 "Taster_nicht_betaetigt" 1 "Taster_betaetigt" ;
VAL_ 1626 BCM1_AFS_Lampe 0 "Aus" 1 "Ein" ;
VAL_ 1626 BCM1_Reisemodus_Texte 0 "keine_Anzeige" 1 "Umschaltung_auf_Linksverkehr_aktiv" 2 "Umschaltung_auf_Rechtsverkehr_aktiv" ;
VAL_ 1626 BCM1_Lichtwarn_Texte 0 "keine_Warnung" 1 "Standlichtwarnung" 2 "Parklichtwarnung" 3 "Nebelschlusslichtwarnung" ;
VAL_ 1626 Gong_TFL_Umschaltung 0 "kein_Gong" 1 "Gong_einmalig" ;
VAL_ 1626 BCM_ValetTaster_Fkts_LED 0 "LED_aus" 1 "LED_ein" ;
VAL_ 1626 LRH_Taster 0 "nicht_betaetigt" 1 "betaetigt" ;
VAL_ 1626 APS_Tongeber_defekt 0 "iO" 1 "defekt" ;
VAL_ 1626 BCM1_EasyEntry_Status 0 "Aus" 1 "Ein" ;
VAL_ 1626 BCM1_Lenksaeule_aktiv 0 "Lenksaeulenverstellung nicht aktiv" 1 "Lenksaeulenverstellung aktiv" ;
VAL_ 1626 BCM1_Spannungs_Anf 0 "keine_Anforderung" 1 "Anforderung_Stufe_1" 2 "Anforderung_Stufe_2" 3 "Anforderung_Stufe_3" ;
VAL_ 1626 DWA_Alarmquelle 0 "kein_Ausloesegrund" 1 "Tuerkontakt_Fahrertuer" 2 "Tuerkontakt_Beifahrertuer" 3 "Tuerkontakt_hinten_links" 4 "Tuerkontakt_hinten_rechts" 5 "Motorhaubenkontakt_vorne" 6 "Kofferraum_hinten" 7 "Masseschleife_der_Heckscheibe" 8 "Innenraumueberwachung" 9 "Alarm_durch_Noteinstieg" 10 "Sounder" 11 "Neigungssensor" 12 "TSG_FT_am_CAN_Bus" 13 "TSG_BT_am_CAN_Bus" 14 "TSG_HFS_am_CAN_Bus" 15 "TSG_HBFS_am_CAN_Bus" 16 "Klemme_15" 17 "Klemme_15sig" 18 "frei" 19 "Anhaengerueberwachung" 20 "Scheinwerferueberwachung_links" 21 "Scheinwerferueberwachung_rechts" 22 "Handschuhkasten" 23 "Verdeckueberwachung" 24 "OBD_Alarm" 25 "Power_on_Reset" 30 "Init" 31 "Fehler" ;
VAL_ 1626 DWA_Einschraenkung 0 "Init" 1 "Fehler" ;
VAL_ 1626 BCM_HBFS_EOE_aktiv 0 "EOE_inaktiv" 1 "EOE_aktiv" ;
VAL_ 1626 BCM_HFS_EOE_aktiv 0 "EOE_inaktiv" 1 "EOE_aktiv" ;
VAL_ 1626 BCM_Anf_AAW_MoLaWa 0 "Init" 1 "AAW_angefordert" 2 "MoLaWa_angefordert" ;
VAL_ 1626 BCM_Handbremse_Hinweis 0 "inaktiv" 1 "aktiv" ;
VAL_ 1626 BCM_Waehlhebel_P_Hinweis 0 "inaktiv" 1 "aktiv" ;
VAL_ 1626 BCM1_Fahrlicht_Hinweis 0 "kein_Fahrlicht_Hinweis" 1 "Fahrlicht_Hinweis" ;
VAL_ 1626 BCM_HDF_betaetigt 0 "nicht_betaetigt" 1 "betaetigt" ;
VAL_ 2527679637 BCM_FAS_Taster 0 "nicht_betaetigt" 1 "betaetigt" ;
VAL_ 2527679637 CPD_Warnung 0 "keine_Warnung" 1 "Warnung_mit_Ton" 2 "Warnung_ohne_Ton" ;
VAL_ 2527679637 MiKo_Tisch_Positionswarnung 0 "keine_Anzeige_Tisch_unten" 1 "Warnung_Tisch_oben" ;
VAL_ 2527679637 LiSi_Touch_Event 0 "nicht_betaetigt" 1 "Tippen" 2 "Wischen_Slide" 3 "Geste" 4 "Doppeltippen" 5 "Longpress_1" 6 "Longpress_2" 7 "Longpress_3" 8 "Press" 9 "Strongpress" 10 "reserviert" 11 "reserviert" 12 "reserviert" 13 "reserviert" 14 "Taktgeber_Inkrement" 15 "Fehler" ;
VAL_ 2527679637 BCM_anf_VLW 0 "Init" 1 "VLW_angefordert_VLK2_1" 2 "deg_VLW_FT_angefordert" 3 "deg_VLW_Werkstatt_angefordert" 4 "VLW_angefordert_VLK2_2" 5 "Wegrollwarnung_angefordert" 6 "Rollfaehigkeit_ohne_Akustik" 7 "Rollfaehigkeit_mit_Akustik" ;
VAL_ 2527679637 BCM_Defrost_Taste 0 "Taste_nicht_betaetigt" 1 "Taste_betaetigt" 2 "Fehler" 3 "Init_oder_nicht_verbaut" ;
VAL_ 2527679637 BCM_HSH_Taste 0 "Taste_nicht_betaetigt" 1 "Taste_betaetigt" 2 "Fehler" 3 "Init_oder_nicht_verbaut" ;
VAL_ 2527679637 BCM_FSH_Taste 0 "Taste_nicht_betaetigt" 1 "Taste_betaetigt" 2 "Fehler" 3 "Init_oder_nicht_verbaut" ;
VAL_ 2527679637 LTMs_01_alt 0 "aktuell" 1 "veraltet" ;
VAL_ 2527679637 BCM_LTM_Nebelschluss_Status 0 "nicht_aktiv" 1 "aktiv" ;
VAL_ 2527679637 BCM_LTM_PopUp_Texte 0 "keine_Anzeige" 1 "Ausschalt_Hinweis" 2 "Ausschalt_Quittierung" ;
VAL_ 2527679637 BCM_LTM_Allwetterl_Status 0 "nicht_aktiv" 1 "aktiv" ;
VAL_ 2527679637 BCM_LTM_PopUp_Status 0 "Init" 1 "AUTO" 2 "Abblendlicht" 3 "Standlicht" 4 "OFF" ;
VAL_ 2527679637 BCM_LTM_Nebell_Status 0 "nicht_aktiv" 1 "aktiv" ;
VAL_ 2527679637 BCM_LTM_PopUp_Anf 0 "keine_Anforderung" 1 "Licht_PopUp" 2 "Nebellicht_PopUp" 3 "Allwetterlicht_PopUp" 4 "Nebelschlusslicht_PopUp" ;
VAL_ 2527679637 BCM_LTM_PopUp_Inhalt 0 "Init" 1 "AUTO" 2 "Abblendlicht" 4 "Standlicht" 8 "OFF" ;
VAL_ 2463978607 BCM_RGB_Intensitaet 126 "Init" 127 "Fehler" ;
VAL_ 2463978607 BCM_RGB_Normierung_Intensitaet 0 "ohne Normierung" 1 "Normierung der Intensität" ;
VAL_ 2463978607 BCM_RGB_Dimmzeit_Zeitbasis 0 "Zeitbasis_50ms" 1 "Zeitbasis_250ms" ;
VAL_ 2463978609 HSH_LED 0 "Aus" 1 "Ein" ;
VAL_ 2463978609 HSH_Status 0 "aus" 1 "ein" 2 "tbd" 3 "Fehler" ;
VAL_ 2463978609 BCM_Relais_2_Batterie 0 "nicht_betaetigt" 1 "betaetigt" ;
VAL_ 2463978609 Niveausensor_HL_verbaut 0 "nicht_verbaut" 1 "verbaut" ;
VAL_ 2463978609 Niveausensor_VL_verbaut 0 "nicht_verbaut" 1 "verbaut" ;
VAL_ 2463978609 KRH_Stufe_LED_re 0 "Aus" 1 "Stufe_1" 2 "Stufe_2" 3 "Stufe_3" ;
VAL_ 2463978609 KRH_Stufe_LED_li 0 "Aus" 1 "Stufe_1" 2 "Stufe_2" 3 "Stufe_3" ;
VAL_ 2463978609 SIL_Stufe_LED_re 0 "Aus" 1 "Stufe_1" 2 "Stufe_2" 3 "Stufe_3" 4 "Stufe_4" 5 "Stufe_5" 6 "Stufe_6" ;
VAL_ 2463978609 SIL_Stufe_LED_li 0 "Aus" 1 "Stufe_1" 2 "Stufe_2" 3 "Stufe_3" 4 "Stufe_4" 5 "Stufe_5" 6 "Stufe_6" ;
VAL_ 2463978609 FA_Hoehenwert_VL_01 254 "nicht initialisiert" 255 "Fehler" ;
VAL_ 2463978609 FA_Hoehenwert_HL_01 254 "nicht initialisiert" 255 "Fehler" ;
VAL_ 2463978887 BDM_Spannung_dyn 16383 "Init/Fehler" ;
VAL_ 2463978887 BDM_I_Bereich_dyn 0 "-30A ... 30A (1mA/Digit)" 1 "-300A ... 300A (10mA/Digit)" 2 "-3000A ... 3000A (100mA/Digit)" 3 "Init/Fehler" ;
VAL_ 2463978887 BDM_Strom_dyn 65535 "Init/Fehler" ;
VAL_ 2463978887 BDM_Temp_dyn 255 "Init/Fehler" ;
VAL_ 2463978887 BDM_UBattVorgabe 63 "Init/Fehler" ;
VAL_ 2463978887 BDM_WD_dyn 0 "kein Reset" 1 "Reset" ;
VAL_ 2463978887 BDM_I_Batt_Low 0 "Batterie_nicht_ab" 1 "Batterie_ab" ;
VAL_ 2463978887 BDM_Status_dyn 0 "reserviert" 1 "LiIon_Vorwarnung_TE_oeffnet" 2 "reserviert" 3 "T_Messung_nicht_moeglich" 4 "I_Messung_nicht_moeglich" 5 "U_Messung_nicht_moeglich" 6 "Kalibrierungsdaten_inkonsistent" 7 "Vorhalt" ;
VAL_ 2463978887 BDM_ResponseError 0 "normal" 1 "Fehler" ;
VAL_ 2463978887 BDM_Kommunikationsbasis 0 "erweiterte_Kommunikation" 1 "Basiskommunikation" ;
VAL_ 2463978887 BDM_QRS_Feedback 0 "inaktiv" 1 "aktiv" ;
VAL_ 2463978882 BedienDisp_hbfs_control_vol 0 "Init" 1 "Mute" 2 "Volume_up" 3 "Volume_down" 4 "Volume_up_relativ" 5 "Volume_down_relativ" 6 "Volume_absolut" 7 "Volume_prozent" 15 "Fehler" ;
VAL_ 2463978882 BedienDisp_hbfs_fader 0 "Init" 1 "Rear_Mute" 2 "Fader_front" 3 "Fader_rear" 4 "Front_Mute" 15 "Fehler" ;
VAL_ 2463978882 BedienDisp_hbfs_surround 0 "Init" 1 "Surround_off" 2 "Surround_up" 3 "Surround_down" 4 "Surround_up_relativ" 5 "Surround_down_relativ" 6 "Surround_absolut" 7 "Surround_prozent" 15 "Fehler" ;
VAL_ 2463978882 BedienDisp_hbfs_sound 0 "Init" 1 "No_function_availible" 2 "NaVi" 3 "SDS" 4 "Audio" 5 "TA" 6 "Phone" 7 "Phone_ringing" 8 "Digital_voice_assistant" ;
VAL_ 2463978882 BedienDisp_hbfs_Lordose_hoch 0 "Aus" 1 "Ein" ;
VAL_ 2463978882 BedienDisp_hbfs_Lordose_runter 0 "Aus" 1 "Ein" ;
VAL_ 2463978882 BedienDisp_hbfs_Lordose_vor 0 "Aus" 1 "Ein" ;
VAL_ 2463978882 BedienDisp_hbfs_Lordose_zurueck 0 "Aus" 1 "Ein" ;
VAL_ 2463978882 BedienDisp_hbfs_touch 0 "nicht_betaetigt" 1 "Tippen" 2 "Wischen_Slide" 3 "Geste" 4 "Doppeltippen_Doppelklick" 5 "Longpress_1_Halten_1" 6 "Longpress_2_Halten_2" 7 "Longpress_3_Halten_3" 8 "Press" 9 "Strong_Press" 10 "reserviert" 11 "reserviert" 12 "reserviert" 13 "reserviert" 14 "Taktgeber_Inkrement" 15 "Fehler" ;
VAL_ 2463978882 BedienDisp_hbfs_sound_fokus 0 "Init" 1 "All" 2 "Front_left" 3 "Front_right" 4 "Front" 5 "Rear_left" 6 "Rear_right" 7 "Rear" 14 "Surround" 15 "Fehler" ;
VAL_ 2463978882 BedienDisp_hbfs_surround_02 126 "Init" 127 "Fehler" ;
VAL_ 2463978882 BedienDisp_hbfs_control_vol_02 126 "Init" 127 "Fehler" ;
VAL_ 2463978882 BedienDisp_HBFSFo_Bestaetigung 0 "keine_Bestaetigung" 1 "Bestaetigung" 2 "Reserve" 3 "Fehler" ;
VAL_ 2463978882 BedienDisp_HBFSFo_Stoerung 0 "kein_Fehler_MCC4ABT" 1 "Fehler_MCC4ABT_aktiv" ;
VAL_ 2463978882 BedienDisp_hbfs_UseCase_Pos 0 "inaktiv_Init" 1 "UseCase_Pos_1" 2 "UseCase_Pos_2" 3 "UseCase_Pos_3" 4 "UseCase_Pos_4" 5 "UseCase_Pos_5" 6 "UseCase_Pos_6" 7 "UseCase_Pos_7" ;
VAL_ 2463978881 BedienDisp_hfs_control_vol 0 "Init" 1 "Mute" 2 "Volume_up" 3 "Volume_down" 4 "Volume_up_relativ" 5 "Volume_down_relativ" 6 "Volume_absolut" 7 "Volume_prozent" 15 "Fehler" ;
VAL_ 2463978881 BedienDisp_hfs_fader 0 "Init" 1 "Rear_Mute" 2 "Fader_front" 3 "Fader_rear" 4 "Front_Mute" 15 "Fehler" ;
VAL_ 2463978881 BedienDisp_hfs_surround 0 "Init" 1 "Surround_off" 2 "Surround_up" 3 "Surround_down" 4 "Surround_up_relativ" 5 "Surround_down_relativ" 6 "Surround_absolut" 7 "Surround_prozent" 15 "Fehler" ;
VAL_ 2463978881 BedienDisp_hfs_sound 0 "Init" 1 "No_function_availible" 2 "NaVi" 3 "SDS" 4 "Audio" 5 "TA" 6 "Phone" 7 "Phone_ringing" 8 "Digital_voice_assistant" ;
VAL_ 2463978881 BedienDisp_hfs_Lordose_hoch 0 "Aus" 1 "Ein" ;
VAL_ 2463978881 BedienDisp_hfs_Lordose_runter 0 "Aus" 1 "Ein" ;
VAL_ 2463978881 BedienDisp_hfs_Lordose_vor 0 "Aus" 1 "Ein" ;
VAL_ 2463978881 BedienDisp_hfs_Lordose_zurueck 0 "Aus" 1 "Ein" ;
VAL_ 2463978881 BedienDisp_hfs_touch 0 "nicht_betaetigt" 1 "Tippen" 2 "Wischen_Slide" 3 "Geste" 4 "Doppeltippen_Doppelklick" 5 "Longpress_1_Halten_1" 6 "Longpress_2_Halten_2" 7 "Longpress_3_Halten_3" 8 "Press" 9 "Strong_Press" 10 "reserviert" 11 "reserviert" 12 "reserviert" 13 "reserviert" 14 "Taktgeber_Inkrement" 15 "Fehler" ;
VAL_ 2463978881 BedienDisp_hfs_sound_fokus 0 "Init" 1 "All" 2 "Front_left" 3 "Front_right" 4 "Front" 5 "Rear_left" 6 "Rear_right" 7 "Rear" 14 "Surround" 15 "Fehler" ;
VAL_ 2463978881 BedienDisp_hfs_surround_02 126 "Init" 127 "Fehler" ;
VAL_ 2463978881 BedienDisp_hfs_control_vol_02 126 "Init" 127 "Fehler" ;
VAL_ 2463978881 BedienDisp_HFSFo_Bestaetigung 0 "keine_Bestaetigung" 1 "Bestaetigung" 2 "Reserve" 3 "Fehler" ;
VAL_ 2463978881 BedienDisp_HFSFo_Stoerung 0 "kein_Fehler_MCC4ABT" 1 "Fehler_MCC4ABT_aktiv" ;
VAL_ 2463978881 BedienDisp_hfs_UseCase_Pos 0 "inaktiv_Init" 1 "UseCase_Pos_1" 2 "UseCase_Pos_2" 3 "UseCase_Pos_3" 4 "UseCase_Pos_4" 5 "UseCase_Pos_5" 6 "UseCase_Pos_6" 7 "UseCase_Pos_7" ;
VAL_ 1635 NVEM_Abschaltstufe 0 "Stufe_0_keine_Einschraenkung" 1 "Stufe_1" 2 "Stufe_2" 3 "Stufe_3" ;
VAL_ 1635 BEM_STH_Zielzeit 14 "Init" 15 "Fehler" ;
VAL_ 1635 BEM_MMI_Vorwarnung 0 "keine Anzeige" 1 "Anzeige MMI-Vorwarnung" ;
VAL_ 1635 NVEM_Freigabe_ZusBatt_Laden 0 "keine_Freigabe_Laderelais" 1 "Freigabe_Laderelais_schliessen" ;
VAL_ 1635 NVEM_Anf_SD_schalten 0 "Anf_SD_Nachlauf_nicht_aktiv" 1 "Anf_SD_Nachlauf_aktiv" ;
VAL_ 1635 BEM_Generatordiagnose 0 "keine Anzeige" 1 "Ladekontrollanzeige ein (Vorhalt)" 2 "rotes Batteriesymbol und Text (Generator defekt)" 3 "Hybrid_DCDC_Wandler_defekt" ;
VAL_ 1635 BEM_Red_Innengeblaese 0 "keine Reduzierung" 1 "Reduzierung Stufe 1" 2 "Reduzierung Stufe 2" 3 "Reduzierung Stufe 2 und Abschaltung Kompressor" ;
VAL_ 1635 BEM_STH_Einschaltverbot 0 "volle Verfuegbarkeit Standheizung/-lueftung" 1 "Standheizung/-lueftung nicht aktivierbar" ;
VAL_ 1635 BEM_HL_Regelung_Status 0 "HL_Regelung_inaktiv_(vor_und_waehrend_Motorstart)" 1 "HL_Regelung_Stufe_1" 2 "HL_Regelung_Stufe_2" 3 "HL_Regelung_Stufe_3" 4 "Verbrauchernotabschaltung_(VNA)" 5 "HL_Regelung_Stufe_5" 7 "Default" ;
VAL_ 1635 BEM_Ladezustand 14 "Init" 15 "Fehler" ;
VAL_ 1635 BEM_Batteriediagnose 0 "keine_Anzeige" 1 "nicht_belegt" 2 "Anzeige_aberkannte_Batterie" 3 "Anzeige_schwache_Batterie" 4 "Anzeige_Batterie_OK" 5 "Anzeige_Batterie_Laden" 6 "Anzeige_Batterie_Pruefen" 7 "Fehler" ;
VAL_ 1635 MIB_Stromsparmodus 0 "inaktiv" 1 "aktiv" ;
VAL_ 1635 BEM_REK_aktiv 0 "keine_Rekuperationsfreigabe" 1 "Rekuperationsfreigabe" ;
VAL_ 1635 BEM_EMLIN_ungueltig 0 "Signale_gueltig" 1 "Signale_ungueltig" ;
VAL_ 1635 BEM_Batt_Ab 0 "verbunden" 1 "nicht_verbunden" ;
VAL_ 1635 BEM_UBDM 0 "Init" 255 "Fehler" ;
VAL_ 1635 BEM_Anf_KL15_schalten 0 "Keine_Einschraenkung_Kl15" 1 "Empfehlung_auto_Abschaltung_Kl15" 2 "Veto_auto_Abschaltung_Kl15" 3 "Veto_auto_Abschaltung_Fahrtbetrieb" ;
VAL_ 1635 NVEM_Batterie_Service 0 "kein_Service" 1 "Service_Information1" 2 "Service_Information2" 3 "Service_Information3" ;
VAL_ 1635 NVEM_Freigabe_OnlineUpdate 0 "keine_Freigabe" 1 "Freigabe" ;
VAL_ 1635 NVEM_Freigabe_ORU4 0 "Init" 1 "keine_Freigabe" 2 "Freigabe_erteilt" 3 "Veto_Freigabe" ;
VAL_ 1635 NVEM_Verbraucherabsch_Anz 0 "keine_Anzeige" 1 "Anzeige_aktiv" ;
VAL_ 1163 NVEM_Betriebsart 0 "oKl15_Sing_oVerbr" 1 "oKl15_Red_RedKontingent_oVerbr" 2 "oKl15_Red_HohKontingent_oVerbr" 3 "oKl15_Red_mVerbr" 4 "reserved" 5 "reserved" 6 "reserved" 7 "reserved" 8 "mKl15_Sing_oVerbr" 9 "mKl15_Red_RedKontingent_oVerbr" 10 "mKl15_Red_HohKontingent_oVerbr" 11 "mKl15_Red_mVerbr" 12 "Fahrbereitschaft_mVerbr" 13 "reserved" 14 "reserved" 15 "Fehler" ;
VAL_ 1163 NVEM_Ladezustand 126 "INIT" 127 "Fehler" ;
VAL_ 1163 NVEM2_Status_FuSiFahrt 0 "Init" 1 "Keine_FuSi_Fahrt" 2 "Qualifikation_FuSi_Fahrt" 3 "FuSi_Fahrt_Aktiv" 4 "Qualifikation_Ende_FuSi_Fahrt" 5 "FuSi_Stand" 6 "FuSi_Nachlauf" 7 "Fehler" ;
VAL_ 1163 NVEM_Energienetz_Status 0 "QM" 1 "ASIL_A" 2 "ASIL_B" 3 "ASIL_C" 6 "InitWert" 7 "Fehler" ;
VAL_ 1163 NVEM_Vorgabe_Leistungsstufe 0 "Init" 1 "Leistungsstufe_0" 2 "Leistungsstufe_1" 3 "Leistungsstufe_2" 4 "Leistungsstufe_3" 5 "Leistungsstufe_4" 6 "Leistungsstufe_5" 7 "Fehler" ;
VAL_ 1163 NVEM2_Typ_EnergieNetz 0 "Sp12V_Gen_ICE" 1 "Sp12V_BEV" 2 "Sp12V_PHEV" 3 "Sp12V_MHEV" 4 "Sp12V_HEV" 5 "Sp12V_Sp48V_Gen_Insel" 6 "Sp12V_Sp12V_RSG_MHEV12V" 7 "Sp12V_BEV_ASILC" 14 "Fehler" 15 "Init" ;
VAL_ 1163 NVEM_Energie_Klima_Vorgabe 254 "Init" 255 "Fehler" ;
VAL_ 1163 NVEM_Last_Anf 0 "keine Anforderung" 1 "Verbraucher_Anforderung_Stufe_1" 2 "Verbraucher_Anforderung_Stufe_2" 3 "Verbraucher_Anforderung_Stufe_3" ;
VAL_ 1163 NVEM_STH_ZielzeitLang 14 "Init" 15 "Fehler" ;
VAL_ 1163 NVEM_Red_KomfortVerbrauch 0 "keine_Einschraenkung" 1 "Einschraenkung_Stufe_1" 2 "Einschraenkung_Stufe_2" 3 "Einschraenkung_Stufe_3" 4 "Einschraenkung_Stufe_4" 5 "Einschraenkung_Stufe_5" 6 "Einschraenkung_Stufe_6" 7 "Einschraenkung_Stufe_7" 8 "Einschraenkung_Stufe_8" 15 "Fehler" ;
VAL_ 1163 NVEM_PTC_Sollstufe 0 "Aus" 1 "Stufe_1" 2 "Stufe_2" 3 "Stufe_3" ;
VAL_ 1163 NVEM_Bordnetzdiagnose 0 "kein_Fehler" 1 "Warnung_1" 2 "Warnung_2" 3 "Warnung_3" ;
VAL_ 1163 HLR_PTC_linear_Freigabe 63 "Fehler" ;
VAL_ 2463978850 NVEM_Bordnetz_Information 0 "keine_Anzeige" 1 "NV_Batterie_iO" 2 "NV_Batterie_laden" 3 "NV_Batterie_pruefen" 4 "NV_Batterie_schwach" 5 "NV_Batterie_Ab" 6 "NV_Batterie_Service" 7 "NV_Energiesystem_unplausibel" 8 "Ladekontrollleuchte" 9 "Generator_defekt" 10 "reserviert" 11 "reserviert" 12 "reserviert" 13 "reserviert" 14 "Init" 15 "Fehler" ;
VAL_ 2463978850 NVEM_Verbraucher_Information 0 "Keine_Anzeige" 1 "MMI_Vorwarnung" 2 "Anzeige_Verbraucherabschaltung" 3 "reserviert" 4 "reserviert" 5 "reserviert" 6 "Init" 7 "Fehler" ;
VAL_ 2463978850 NVEM2_VerbrZustandsAnf 0 "Freigabe" 1 "Verbraucher_Sperren" 2 "Verbr_Sperren_KL_Red" 3 "reserved" 4 "reserved" 5 "reserved" 6 "Verbr_Sperren_KL_Anf" 7 "Teilweise_Anschalt_Anf" 8 "Anschalt_Anf" 9 "reserved" 10 "reserved" 11 "Abschaltstufe_1" 12 "Abschaltstufe_2" 13 "Abschaltstufe_3" 14 "Init" 15 "Fehler" ;
VAL_ 2463978850 NVEM_NVStuetzungAnf 0 "keine_Anforderung" 1 "Anforderung_sichere_Versorgung" 2 "Anforderung_Abschaltung" 3 "Fehler" ;
VAL_ 2463978850 NVEM3_Absch_SCR 0 "Init" 1 "Abschaltung_SCR" ;
VAL_ 2463978850 NVEM_Batt_Temp_Hinweis 0 "Keine_Anzeige" 1 "Hinweis_Aussenhuelle_zu" 2 "Hinweis_Klima_ein" 3 "Wunsch_Aussenhuelle_zu" 4 "Wunsch_Klima_ein" ;
VAL_ 870 BM_ZV_auf 0 "inaktiv" 1 "aktiv" ;
VAL_ 870 BM_ZV_zu 0 "inaktiv" 1 "aktiv" ;
VAL_ 870 BM_DWA_ein 0 "inaktiv" 1 "aktiv" ;
VAL_ 870 BM_DWA_Alarm 0 "inaktiv" 1 "aktiv" ;
VAL_ 870 BM_Crash 0 "inaktiv" 1 "aktiv" ;
VAL_ 870 BM_Panik 0 "inaktiv" 1 "aktiv" ;
VAL_ 870 BM_Not_Bremsung 0 "kein_blinken" 1 "Notbremswarnblinken_aktiv" ;
VAL_ 870 BM_GDO 0 "inaktiv" 1 "aktiv" ;
VAL_ 870 BM_Warnblinken 0 "inaktiv" 1 "aktiv" ;
VAL_ 870 BM_Taxi_Notalarm 0 "inaktiv" 1 "aktiv" ;
VAL_ 870 BM_Telematik 0 "inaktiv" 1 "aktiv" ;
VAL_ 870 BM_links 0 "inaktiv" 1 "aktiv" ;
VAL_ 870 BM_rechts 0 "inaktiv" 1 "aktiv" ;
VAL_ 870 Blinken_li_Fzg_Takt 0 "Blinker_links_ausgeschaltet" 1 "Blinker_links_eingeschaltet" ;
VAL_ 870 Blinken_re_Fzg_Takt 0 "Blinker_rechts_ausgeschaltet" 1 "Blinker_rechts_eingeschaltet" ;
VAL_ 870 Blinken_li_Kombi_Takt 0 "Blinkerkontrolllampe_links_ausgeschaltet" 1 "Blinkerkontrolllampe_links_eingeschaltet" ;
VAL_ 870 Blinken_re_Kombi_Takt 0 "Blinkerkontrolllampe_rechts_ausgeschaltet" 1 "Blinkerkontrolllampe_rechts_eingeschaltet" ;
VAL_ 870 BM_NBA_n_codiert_n_aktiv 0 "codiert_AND_kein_Fehler" 1 "nicht_codiert_OR_Fehler_erkannt" ;
VAL_ 870 BM_NBA_Status 0 "NBA_nicht_aktiv" 1 "BRL_Dunkelphase" 3 "BRL_Hellphase" ;
VAL_ 870 BM_WBT_Beleuchtung 0 "inaktiv" 1 "aktiv" ;
VAL_ 870 BM_HD_Oeffnung_angelernt 0 "keine_Quittierung" 1 "Quittierung" ;
VAL_ 870 BM_Autobahn 0 "inaktiv" 1 "aktiv" ;
VAL_ 870 BM_Rollenmodus_Blinken 0 "inaktiv" 1 "aktiv" ;
VAL_ 870 BM_Recas 0 "kein_blinken" 1 "Recasblinken_aktiv" ;
VAL_ 870 BM_Wischblinken 0 "inaktiv" 1 "aktiv" ;
VAL_ 870 BM_Telematik_Abbruchgrund 0 "Init" 1 "speed_out_of_range" 2 "defect" 3 "clamp_s_on" 4 "clamp_15_on" 5 "door_open" 6 "engine_hood_open" 7 "trunk_open" 8 "convertible_top_not_locked" 9 "horn_activated_by_user" 10 "Higher_Prioritiy_Function_active" 11 "Central_Lock_status_changed" 12 "Request_Dropped_by_Requester" 13 "Service_Duration_Expired" 14 "not_possible_due_to_coding" 15 "no_reason_or_unknown_timeout" ;
VAL_ 870 BM_PiloPa 0 "PiloPa_Blinkerquittierung_inaktiv" 1 "PiloPa_Blinkerquittierung_aktiv" ;
VAL_ 870 SAL_TA_Blinken_Status 0 "init" 1 "nicht_bereit" 2 "bereit" 3 "aktiv_links" 4 "aktiv_rechts" ;
VAL_ 870 BM_WBA_Warnblinken 0 "WBA_Warnblinken_inaktiv" 1 "WBA_Warnblinken_aktiv" ;
VAL_ 870 SAL_RHP_Blinken_Status 0 "init" 1 "nicht_bereit" 2 "bereit" 3 "aktiv_links" 4 "aktiv_rechts" ;
VAL_ 870 SAL_RHP_Warnblinken 0 "inaktiv" 1 "aktiv" ;
VAL_ 687 BMC_Spannung 16381 "Null_Bank" 16382 "Init" 16383 "Fehler" ;
VAL_ 687 BMS_As_Entladezaehler_Ueberlauf 0 "kein_Ueberlauf" 1 "Ueberlauf" ;
VAL_ 687 BMS_Rekuperation_Ueberlauf 0 "kein_Ueberlauf" 1 "Ueberlauf" ;
VAL_ 687 BMS_Verbrauch_Ueberlauf 0 "kein_Ueberlauf" 1 "Ueberlauf" ;
VAL_ 1482 BMS_Energieinhalt 2046 "Init" 2047 "Fehler" ;
VAL_ 1482 BMS_Ladevorgang_aktiv 0 "inaktiv" 1 "aktiv" ;
VAL_ 1482 BMS_Batteriediagnose 1 "Anzeige_Batterie" 4 "Anzeige_Batterie_OK" 5 "Anzeige_Batterie_Laden" 6 "Anzeige_Batterie_Pruefen" 7 "Fehler" ;
VAL_ 1482 BMS_Balancing_Aktiv 0 "Init" 1 "aktiv" 2 "nicht_aktiv" ;
VAL_ 1482 BMS_MaxEnergieinhalt 2046 "Init" 2047 "Fehler" ;
VAL_ 1482 BMS_Ausgleichsladung_Anf 1 "Balancing_Request" ;
VAL_ 1482 BMS_Gesamtst_Spgfreiheit 0 "Funktion_nicht_aktiviert" 1 "HV_System_spannungsfrei" 2 "HV_System_nicht_spannungsfrei" 3 "Fehler_nicht_spannungsfrei" ;
VAL_ 1482 BMS_RIso_Ext 4094 "Init" 4095 "Fehler" ;
VAL_ 1482 BMS_KundenWarnung 0 "keine_Warnung" 1 "Warnung_Temperatur_Level1" 2 "Warnung_Temperatur_Level2" ;
VAL_ 2589283664 BMS_Balancing_Aktiv 0 "Init" 1 "aktiv" 2 "nicht_aktiv" ;
VAL_ 2589283664 BMS_Ladevorgang_aktiv 0 "inaktiv" 1 "aktiv" ;
VAL_ 2589283664 BMS_RIso_Ext 4094 "Init" 4095 "Fehler" ;
VAL_ 2589283664 BMS_Min_Ladezustand 2046 "Init" ;
VAL_ 2589283664 BMS_Max_Energie 8190 "Init" ;
VAL_ 2589283664 BMS_Max_Ladezustand 2046 "Init" ;
VAL_ 2589283665 BMS_BattHeizung_VerbautStatus 0 "nicht_verbaut" 1 "verbaut" ;
VAL_ 2589283665 BMS_Fehler_NTKreis 0 "kein_Fehler" 1 "Fehler" ;
VAL_ 2589283665 BMS_Temperierung_Anf 0 "hoher_Kuehlbedarf" 1 "mittlerer_Kuehlbedarf" 2 "niedriger_Kuehlbedarf" 3 "kein_Temperierungsbedarf_Init" 4 "niedriger_Heizbedarf" 5 "mittlerer_Heizbedarf" 6 "hoher_Heizbedarf" 7 "Umwaelzungsbedarf" ;
VAL_ 2589283665 BMS_Status_Ventil1 0 "Ventil_nicht_angesteuert" 1 "Ventil_angesteuert" 2 "reserviert" 3 "reserviert" 4 "reserviert" 5 "Ventil_nicht_verbaut" 6 "Init" 7 "Fehler" ;
VAL_ 2589283665 BMS_Status_Ventil2 0 "Ventil_nicht_angesteuert" 1 "Ventil_angesteuert" 2 "reserviert" 3 "reserviert" 4 "reserviert" 5 "Ventil_nicht_verbaut" 6 "Init" 7 "Fehler" ;
VAL_ 2589283665 BMS_Pumpe1_Ansteuerung 13 "nicht_verbaut" 14 "Init" 15 "Fehler" ;
VAL_ 2589283665 BMS_Pumpe2_Ansteuerung 13 "nicht_verbaut" 14 "Init" 15 "Fehler" ;
VAL_ 2589283665 BMS_VorlaufTemperatur 253 "nicht_verbaut" 254 "Init" 255 "Fehler" ;
VAL_ 2589283665 BMS_Temperatur 254 "Init" 255 "Fehler" ;
VAL_ 2589283665 BMS_SollVorlauftemperatur 254 "Init" 255 "Fehler" ;
VAL_ 2589283665 BMS_RuecklaufTemperatur 253 "nicht_verbaut" 254 "Init" 255 "Fehler" ;
VAL_ 2331595856 BMS_UBE 65534 "Init" 65535 "Fehler" ;
VAL_ 2331595856 BMS_UBE_T 65534 "Init" 65535 "Fehler" ;
VAL_ 2331595856 BMS_Max_UBE 65534 "Init" 65535 "Fehler" ;
VAL_ 2331595856 BMS_Nennspannung 2046 "Init" ;
VAL_ 2331595856 BMS_DC_Ladeschuetze_Ist 0 "geoeffnet" 1 "geschlossen" 2 "reserviert" 3 "reserviert" 4 "reserviert" 5 "nicht_verbaut" 6 "Init" 7 "Schuetzfehler" ;
VAL_ 2331595856 BMS_Hauptschuetze_Ist 0 "geoeffnet" 1 "geschlossen" 2 "reserviert" 3 "reserviert" 4 "reserviert" 5 "nicht_verbaut" 6 "Init" 7 "Schuetzfehler" ;
VAL_ 2331595856 BMS_UBE_Indikator 2042 "Funktion_nicht_vorhanden" 2043 "kleiner_0" 2044 "groesser_100" 2045 "nicht_angelernt" 2046 "Init" 2047 "Fehler" ;
VAL_ 2331595856 BMS_UBE_Indik_last_update_km 1048573 "Funktion_nicht_umgesetzt" 1048574 "Init" 1048575 "Fehler" ;
VAL_ 2331595856 BMS_Last_Chg_adeq_SOCswing_Day 0 "Funktion_nicht_verwendet" ;
VAL_ 2331595856 BMS_Last_Chg_adeq_SOCswing_Month 0 "Funktion_nicht_verwendet" ;
VAL_ 2331595856 BMS_Last_Chg_adeq_SOCswing_Year 0 "Funktion_nicht_verwendet" ;
VAL_ 2331595856 BMS_EnergieVorhalt 65533 "Funktion_nicht_umgesetzt" 65534 "Init" 65535 "Fehler" ;
VAL_ 2331595856 BMS_Range_Indikator 2042 "Funktion_nicht_vorhanden" 2043 "kleiner_0" 2044 "groesser_100" 2045 "nicht_angelernt" 2046 "Init" 2047 "Fehler" ;
VAL_ 2589283523 OBDProtocol_BMS_48V 0 "OBDonUDS" 1 "OBDclassic" 16 "NoOBD" 254 "Init" 255 "Fehler" ;
VAL_ 2589283523 BMS_MV_OBD_Lampe_Anf 0 "Init" 1 "MIL_Request" ;
VAL_ 2589283523 BMS_48V_Indc_StChk 0 "Complete" 1 "NotComplete" ;
VAL_ 2589283523 BMS_48V_Indc_StFail 0 "passiv" 1 "aktiv" ;
VAL_ 2589283523 BMS_MV_Kundenwarnung 0 "keine_Warnung" 1 "Warnung_Temperatur_Level1" 2 "Warnung_Temperatur_Level2" ;
VAL_ 2589283523 BMS_MV_Dauer_EntladeLeistung 2046 "Init" 2047 "Fehler" ;
VAL_ 2589283523 BMS_MV_Dauer_LadeLeistung 2046 "Init" 2047 "Fehler" ;
VAL_ 2589283523 BMS_MV_Dauer_EntladeSpannung 254 "Init" 255 "Fehler" ;
VAL_ 2589283523 BMS_MV_Dauer_LadeSpannung 254 "Init" 255 "Fehler" ;
VAL_ 2589283523 BMS_MV_Dauer_RMS_Strom 254 "Init" 255 "Fehler" ;
VAL_ 2331596015 BSIS_Anzeigen_links 0 "keine_Anzeige" 1 "BSIS_Systemstoerung" 2 "BSIS_nicht_verfuegbar" 3 "BSIS_Sensor_eingeschraenkt" 4 "BSIS_Sensor_nicht_verfuegbar" 5 "BSIS_Anhaenger_eingeschraenkt" 6 "BSIS_Anhaenger_nicht_verfuegbar" 7 "BSIS_Fkt_deaktiviert" 8 "BSIS_Sound_deaktivert" 9 "BSIS_Warnton" ;
VAL_ 2331596015 BSIS_LED_Hell_links 126 "Init" 127 "Fehler" ;
VAL_ 2331596015 BSIS_LED_Ausgabemodus_links 0 "LED_aus" 1 "Infostufe" 2 "Warnstufe" 3 "Akutwarnstufe" 4 "Aufpruefen_BSIS" 5 "Demolauf_BSIS" ;
VAL_ 2331596016 BSIS_Anzeigen_rechts 0 "keine_Anzeige" 1 "BSIS_Systemstoerung" 2 "BSIS_nicht_verfuegbar" 3 "BSIS_Sensor_eingeschraenkt" 4 "BSIS_Sensor_nicht_verfuegbar" 5 "BSIS_Anhaenger_eingeschraenkt" 6 "BSIS_Anhaenger_nicht_verfuegbar" 7 "BSIS_Fkt_deaktiviert" 8 "BSIS_Sound_deaktivert" 9 "BSIS_Warnton" ;
VAL_ 2331596016 BSIS_LED_Hell_rechts 126 "Init" 127 "Fehler" ;
VAL_ 2331596016 BSIS_LED_Ausgabemodus_rechts 0 "LED_aus" 1 "Infostufe" 2 "Warnstufe" 3 "Akutwarnstufe" 4 "Aufpruefen_BSIS" 5 "Demolauf_BSIS" ;
VAL_ 902 CHA_Charisma_Taste2_LED 0 "LED_aus" 1 "LED_ein" 2 "LED_blinken" 3 "Fehler" ;
VAL_ 902 CHA_ReqPrgDispSetup 0 "init" 1 "layout_comfort" 2 "layout_eco" 3 "layout_sport" 4 "layout_offroad" 5 "layout_sportplus" 6 "program_6" 7 "program_7" 8 "program_8" 9 "program_9" 10 "program_10" 11 "program_11" 12 "program_12" 13 "program_13" 14 "program_14" 15 "program_15" ;
VAL_ 902 CHA_Current_Mode_FPA 0 "keine_Funktion" 1 "Programm_1" 2 "Programm_2" 3 "Programm_3" 4 "Programm_4" 5 "Programm_5" 6 "Programm_6" 7 "Programm_7" 8 "Programm_8" 9 "Programm_9" 10 "Programm_10" 11 "Programm_11" 12 "Programm_12" 13 "Programm_13" 14 "Programm_14" 15 "Programm_15" 16 "Programm_16" 17 "Programm_17" 18 "Programm_18" 19 "Programm_19" 20 "Programm_20" 21 "Programm_21" 22 "Programm_22" 23 "Programm_23" 24 "Programm_24" 25 "Programm_25" 26 "Programm_26" 27 "Programm_27" 28 "Programm_28" 29 "Programm_29" 30 "Programm_30" 31 "Programm_31" 32 "Programm_32" ;
VAL_ 902 CHA_Eco_Charisma_LED 0 "LED_aus_und_Blinken_aus" 1 "LED_ein_und_Blinken_aus" 2 "LED_ein_und_Blinken_ein_50_percent" 3 "reserviert" ;
VAL_ 902 CHA_Fahrer_Umschaltung 0 "keine_oder_automatische_Umschaltung" 1 "manuelle_Umschaltung" ;
VAL_ 902 CHA_EV_LED 0 "LED_aus" 1 "LED_an" ;
VAL_ 902 CHA_Ziel_FahrPr_AMB 0 "keine_Funktion" 1 "Programm_1" 2 "Programm_2" 3 "Programm_3" 4 "Programm_4" 5 "Programm_5" 6 "Programm_6" 7 "Programm_7" 8 "Programm_8" 9 "Programm_9" 10 "Programm_10" 11 "Programm_11" 12 "Programm_12" 13 "Programm_13" 14 "Programm_14" 15 "Programm_15" ;
VAL_ 902 CHA_Ziel_FahrPr_IVB 0 "keine_Funktion" 1 "Programm_1" 2 "Programm_2" 3 "Programm_3" 4 "Programm_4" 5 "Programm_5" 6 "Programm_6" 7 "Programm_7" 8 "Programm_8" 9 "Programm_9" 10 "Programm_10" 11 "Programm_11" 12 "Programm_12" 13 "Programm_13" 14 "Programm_14" 15 "Programm_15" ;
VAL_ 902 CHA_Kombi_Texte 0 "keine_Anzeige" 1 "Text_1" 2 "Text_2" 3 "Text_3" 4 "Text_4" 5 "Text_5" 6 "Text_6" 7 "Text_7" 8 "Text_8" 9 "Text_9" 10 "Text_10" 11 "Text_11" 12 "Text_12" 13 "Text_13" 14 "Text_14" 15 "Text_15" ;
VAL_ 902 CHA_Ziel_FahrPr_KL 0 "keine_Funktion" 1 "Programm_1" 2 "Programm_2" 3 "Programm_3" 4 "Programm_4" 5 "Programm_5" 6 "Programm_6" 7 "Programm_7" 8 "Programm_8" 9 "Programm_9" 10 "Programm_10" 11 "Programm_11" 12 "Programm_12" 13 "Programm_13" 14 "Programm_14" 15 "Programm_15" ;
VAL_ 902 CHA_Ziel_FahrPr_HSP 0 "keine_Funktion" 1 "Programm_1" 2 "Programm_2" 3 "Programm_3" 4 "Programm_4" 5 "Programm_5" 6 "Programm_6" 7 "Programm_7" 8 "Programm_8" 9 "Programm_9" 10 "Programm_10" 11 "Programm_11" 12 "Programm_12" 13 "Programm_13" 14 "Programm_14" 15 "Programm_15" ;
VAL_ 902 CHA_StCurProfDft 0 "Init" 1 "profile_is_not_configurable" 2 "profile_is_default" 3 "profile_is_not_default" ;
VAL_ 902 CHA_Ziel_FahrPr_RWB 0 "keine_Funktion" 1 "Programm_1" 2 "Programm_2" 3 "Programm_3" 4 "Programm_4" 5 "Programm_5" 6 "Programm_6" 7 "Programm_7" 8 "Programm_8" 9 "Programm_9" 10 "Programm_10" 11 "Programm_11" 12 "Programm_12" 13 "Programm_13" 14 "Programm_14" 15 "Programm_15" ;
VAL_ 902 CHA_Ziel_FahrPr_03_01 0 "keine_Funktion" 1 "Programm_1" 2 "Programm_2" 3 "Programm_3" 4 "Programm_4" 5 "Programm_5" 6 "Programm_6" 7 "Programm_7" 8 "Programm_8" 9 "Programm_9" 10 "Programm_10" 11 "Programm_11" 12 "Programm_12" 13 "Programm_13" 14 "Programm_14" 15 "Programm_15" ;
VAL_ 902 CHA_Ziel_FahrPr_03_02 0 "keine_Funktion" 1 "Programm_1" 2 "Programm_2" 3 "Programm_3" 4 "Programm_4" 5 "Programm_5" 6 "Programm_6" 7 "Programm_7" 8 "Programm_8" 9 "Programm_9" 10 "Programm_10" 11 "Programm_11" 12 "Programm_12" 13 "Programm_13" 14 "Programm_14" 15 "Programm_15" ;
VAL_ 902 CHA_Current_Mode 0 "keine_Funktion" 1 "Programm_1" 2 "Programm_2" 3 "Programm_3" 4 "Programm_4" 5 "Programm_5" 6 "Programm_6" 7 "Programm_7" 8 "Programm_8" 9 "Programm_9" 10 "Programm_10" 11 "Programm_11" 12 "Programm_12" 13 "Programm_13" 14 "Programm_14" 15 "Programm_15" ;
VAL_ 902 CHA_Charge_LED 0 "LED_aus" 1 "LED_ein" ;
VAL_ 902 CHA_Offroad_LED 0 "LED_aus" 1 "LED_ein" 2 "LED_blinken" 3 "Fehler" ;
VAL_ 902 CHA_Kombi_Texte_02 0 "Init" 1 "Text_1" 2 "Text_2" 3 "Text_3" 4 "Text_4" 5 "Text_5" 6 "Text_6" 7 "Text_7" 8 "Text_8" 9 "Text_9" 10 "Text_10" 11 "Text_11" 12 "Text_12" 13 "Text_13" 14 "Text_14" 15 "Text_15" ;
